VERSION "10.7.4"

NS_ :

BS_:

BU_: ADAS_PT BMS_Tester DUMMY_ECU DUMMY_POD_TOOL EDS_F EDS_R EPS2 GS IDB_PT POD RCU_PT VCU_PT XGW_PT

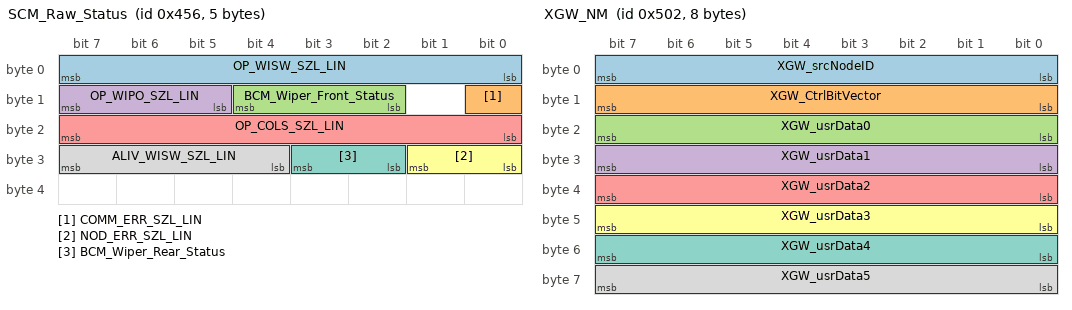
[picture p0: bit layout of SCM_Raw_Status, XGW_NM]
BO_ 1110 SCM_Raw_Status: 5 XGW_PT
  SG_ OP_WISW_SZL_LIN : 7|8@0+ (1,0) [0|255] "" DUMMY_ECU
  SG_ COMM_ERR_SZL_LIN : 8|1@0+ (1,0) [0|1] "" DUMMY_ECU
  SG_ BCM_Wiper_Front_Status : 12|3@0+ (1,0) [0|7] "" IDB_PT
  SG_ OP_WIPO_SZL_LIN : 15|3@0+ (1,0) [0|7] "-" DUMMY_ECU
  SG_ OP_COLS_SZL_LIN : 23|8@0+ (1,0) [0|255] "-" DUMMY_ECU
  SG_ NOD_ERR_SZL_LIN : 25|2@0+ (1,0) [0|3] "" DUMMY_ECU
  SG_ BCM_Wiper_Rear_Status : 27|2@0+ (1,0) [0|3] "" DUMMY_ECU
  SG_ ALIV_WISW_SZL_LIN : 31|4@0+ (1,0) [0|14] "" DUMMY_ECU

BO_ 1168 GS_WarnMsg: 8 GS
  SG_ CHSKM_GS_WarnMsg : 7|8@0+ (1,0) [0|255] "" VCU_PT,XGW_PT
  SG_ ALV_GS_WarnMsg : 11|4@0+ (1,0) [0|14] "" VCU_PT,XGW_PT
  SG_ GS_Warning_Flag_1 : 12|1@0+ (1,0) [0|1] "" VCU_PT,XGW_PT
  SG_ GS_Warning_Flag_2 : 13|1@0+ (1,0) [0|1] "" VCU_PT,XGW_PT
  SG_ GS_Warning_Flag_3 : 14|1@0+ (1,0) [0|1] "-" VCU_PT,XGW_PT
  SG_ GS_Warning_Flag_4 : 15|1@0+ (1,0) [0|1] "-" VCU_PT,XGW_PT
  SG_ GS_Warning_Flag_5 : 16|1@0+ (1,0) [0|1] "" VCU_PT,XGW_PT
  SG_ GS_Warning_Flag_6 : 17|1@0+ (1,0) [0|1] "-" VCU_PT,XGW_PT
  SG_ GS_Warning_Flag_7 : 18|1@0+ (1,0) [0|1] "" VCU_PT,XGW_PT
  SG_ GS_Warning_Flag_8 : 19|1@0+ (1,0) [0|1] "" VCU_PT,XGW_PT
  SG_ GS_Warning_Flag_9 : 20|1@0+ (1,0) [0|1] "-" VCU_PT,XGW_PT
  SG_ GS_Warning_Flag_10 : 21|1@0+ (1,0) [0|1] "-" VCU_PT,XGW_PT
  SG_ GS_Warning_Flag_11 : 22|1@0+ (1,0) [0|1] "" VCU_PT,XGW_PT
  SG_ GS_Warning_Flag_12 : 23|1@0+ (1,0) [0|1] "" VCU_PT,XGW_PT
  SG_ GS_Reserved_signal1 : 31|8@0+ (1,0) [0|255] "-" VCU_PT,XGW_PT
  SG_ GS_Reserved_signal2 : 39|8@0+ (1,0) [0|255] "" VCU_PT,XGW_PT
  SG_ GS_Reserved_signal3 : 47|8@0+ (1,0) [0|255] "" VCU_PT,XGW_PT
  SG_ GS_Reserved_signal4 : 55|8@0+ (1,0) [0|255] "-" VCU_PT,XGW_PT
  SG_ GS_Reserved_signal5 : 63|8@0+ (1,0) [0|255] "" VCU_PT,XGW_PT

BO_ 1178 EDS_R_WarnMsg: 8 EDS_R
  SG_ CHSKM_EDS_R_WarnMsg : 7|8@0+ (1,0) [0|255] "" XGW_PT
  SG_ ALV_EDS_R_WarnMsg : 11|4@0+ (1,0) [0|14] "" XGW_PT
  SG_ EDS_R_Warning_Flag_1 : 12|1@0+ (1,0) [0|1] "" XGW_PT
  SG_ EDS_R_Warning_Flag_2 : 13|1@0+ (1,0) [0|1] "" XGW_PT
  SG_ EDS_R_Warning_Flag_3 : 14|1@0+ (1,0) [0|1] "" XGW_PT
  SG_ EDS_R_Warning_Flag_4 : 15|1@0+ (1,0) [0|1] "-" XGW_PT
  SG_ EDS_R_Warning_Flag_5 : 16|1@0+ (1,0) [0|1] "" XGW_PT
  SG_ EDS_R_Warning_Flag_6 : 17|1@0+ (1,0) [0|1] "-" XGW_PT
  SG_ EDS_R_Warning_Flag_7 : 18|1@0+ (1,0) [0|1] "" XGW_PT
  SG_ EDS_R_Warning_Flag_8 : 19|1@0+ (1,0) [0|1] "" XGW_PT
  SG_ EDS_R_Warning_Flag_9 : 20|1@0+ (1,0) [0|1] "-" XGW_PT
  SG_ EDS_R_Warning_Flag_10 : 21|1@0+ (1,0) [0|1] "" XGW_PT
  SG_ EDS_R_Warning_Flag_11 : 22|1@0+ (1,0) [0|1] "" XGW_PT
  SG_ EDS_R_Warning_Flag_12 : 23|1@0+ (1,0) [0|1] "-" XGW_PT
  SG_ EDS_R_Reserved_signal1 : 31|8@0+ (1,0) [0|255] "" XGW_PT
  SG_ EDS_R_Reserved_signal2 : 39|8@0+ (1,0) [0|255] "" XGW_PT
  SG_ EDS_R_Reserved_signal3 : 47|8@0+ (1,0) [0|255] "-" XGW_PT
  SG_ EDS_R_Reserved_signal4 : 55|8@0+ (1,0) [0|255] "-" XGW_PT
  SG_ EDS_R_Reserved_signal5 : 63|8@0+ (1,0) [0|255] "-" XGW_PT

BO_ 1179 EDS_F_WarnMsg: 8 EDS_F
  SG_ CHSKM_EDS_F_WarnMsg : 7|8@0+ (1,0) [0|255] "" XGW_PT
  SG_ ALV_EDS_F_WarnMsg : 11|4@0+ (1,0) [0|14] "" XGW_PT
  SG_ EDS_F_Warning_Flag_1 : 12|1@0+ (1,0) [0|1] "" XGW_PT
  SG_ EDS_F_Warning_Flag_2 : 13|1@0+ (1,0) [0|1] "-" XGW_PT
  SG_ EDS_F_Warning_Flag_3 : 14|1@0+ (1,0) [0|1] "-" XGW_PT
  SG_ EDS_F_Warning_Flag_4 : 15|1@0+ (1,0) [0|1] "" XGW_PT
  SG_ EDS_F_Warning_Flag_5 : 16|1@0+ (1,0) [0|1] "" XGW_PT
  SG_ EDS_F_Warning_Flag_6 : 17|1@0+ (1,0) [0|1] "-" XGW_PT
  SG_ EDS_F_Warning_Flag_7 : 18|1@0+ (1,0) [0|1] "-" XGW_PT
  SG_ EDS_F_Warning_Flag_8 : 19|1@0+ (1,0) [0|1] "" XGW_PT
  SG_ EDS_F_Warning_Flag_9 : 20|1@0+ (1,0) [0|1] "" XGW_PT
  SG_ EDS_F_Warning_Flag_10 : 21|1@0+ (1,0) [0|1] "-" XGW_PT
  SG_ EDS_F_Warning_Flag_11 : 22|1@0+ (1,0) [0|1] "-" XGW_PT
  SG_ EDS_F_Warning_Flag_12 : 23|1@0+ (1,0) [0|1] "" XGW_PT
  SG_ EDS_F_Reserved_signal1 : 31|8@0+ (1,0) [0|255] "" XGW_PT
  SG_ EDS_F_Reserved_signal2 : 39|8@0+ (1,0) [0|255] "-" XGW_PT
  SG_ EDS_F_Reserved_signal3 : 47|8@0+ (1,0) [0|255] "" XGW_PT
  SG_ EDS_F_Reserved_signal4 : 55|8@0+ (1,0) [0|255] "-" XGW_PT
  SG_ EDS_F_Reserved_signal5 : 63|8@0+ (1,0) [0|255] "" XGW_PT

BO_ 1195 EPS2_WarnMsg: 8 EPS2
  SG_ CHSKM_EPS2_WarnMsg : 7|8@0+ (1,0) [0|255] "" XGW_PT
  SG_ ALV_EPS2_WarnMsg : 11|4@0+ (1,0) [0|14] "" XGW_PT
  SG_ EPS2_Malfunction : 12|1@0+ (1,0) [0|1] "" XGW_PT
  SG_ EPS2_Reduced : 13|1@0+ (1,0) [0|1] "" XGW_PT
  SG_ EPS2_Overheat : 14|1@0+ (1,0) [0|1] "" XGW_PT
  SG_ EPS2_NotReady : 15|1@0+ (1,0) [0|1] "" XGW_PT
  SG_ EPS2_Warning_Flag_5 : 16|1@0+ (1,0) [0|1] "" XGW_PT
  SG_ EPS2_Warning_Flag_6 : 17|1@0+ (1,0) [0|1] "" XGW_PT
  SG_ EPS2_Warning_Flag_7 : 18|1@0+ (1,0) [0|1] "" XGW_PT
  SG_ EPS2_Warning_Flag_8 : 19|1@0+ (1,0) [0|1] "" XGW_PT
  SG_ EPS2_Warning_Flag_9 : 20|1@0+ (1,0) [0|1] "" XGW_PT
  SG_ EPS2_Warning_Flag_10 : 21|1@0+ (1,0) [0|1] "" XGW_PT
  SG_ EPS2_Warning_Flag_11 : 22|1@0+ (1,0) [0|1] "" XGW_PT
  SG_ EPS2_Warning_Flag_12 : 23|1@0+ (1,0) [0|1] "" XGW_PT
  SG_ EPS2_Reserved_signal1 : 31|8@0+ (1,0) [0|255] "" XGW_PT
  SG_ EPS2_Reserved_signal2 : 39|8@0+ (1,0) [0|255] "" XGW_PT
  SG_ EPS2_Reserved_signal3 : 47|8@0+ (1,0) [0|255] "" XGW_PT
  SG_ EPS2_Reserved_signal4 : 55|8@0+ (1,0) [0|255] "" XGW_PT
  SG_ EPS2_Reserved_signal5 : 63|8@0+ (1,0) [0|255] "" XGW_PT

BO_ 1196 VCU_WarnMsg: 8 VCU_PT
  SG_ CHSKM_VCU_WarnMsg : 7|8@0+ (1,0) [0|255] "" XGW_PT
  SG_ ALV_VCU_WarnMsg : 11|4@0+ (1,0) [0|14] "" XGW_PT
  SG_ VCU_GearPOnlyAtStationaryAlert : 12|1@0+ (1,0) [0|1] "" XGW_PT
  SG_ VCU_GearP_NotPossibleAlert : 13|1@0+ (1,0) [0|1] "" XGW_PT
  SG_ VCU_PressBrakeToEngageGear : 14|1@0+ (1,0) [0|1] "" XGW_PT
  SG_ VCU_CantChangeGear : 15|1@0+ (1,0) [0|1] "" XGW_PT
  SG_ VCU_GearMalfunction : 16|1@0+ (1,0) [0|1] "" XGW_PT
  SG_ VCU_RangeAlert : 17|1@0+ (1,0) [0|1] "" XGW_PT
  SG_ VCU_HVSystemReduced : 18|1@0+ (1,0) [0|1] "" XGW_PT
  SG_ VCU_FrontEDSReduced : 19|1@0+ (1,0) [0|1] "" XGW_PT
  SG_ VCU_FrontEDS_Malfunc : 20|1@0+ (1,0) [0|1] "" XGW_PT
  SG_ VCU_RearEDSReduced : 21|1@0+ (1,0) [0|1] "" XGW_PT
  SG_ VCU_RearEDS_Malfunc : 22|1@0+ (1,0) [0|1] "" XGW_PT
  SG_ VCU_CoolingSystem_Malfunc : 23|1@0+ (1,0) [0|1] "" XGW_PT
  SG_ VCU_NeutralRequest : 24|1@0+ (1,0) [0|1] "" XGW_PT
  SG_ VCU_SoftShutdown : 25|1@0+ (1,0) [0|1] "" XGW_PT
  SG_ VCU_EmergencyShutdown : 26|1@0+ (1,0) [0|1] "" XGW_PT
  SG_ VCU_ChgPortDoorSys_Malfunc : 27|1@0+ (1,0) [0|1] "" XGW_PT
  SG_ VCU_Gearchange_NotPossible : 28|1@0+ (1,0) [0|1] "" XGW_PT
  SG_ VCU_12v_Warning : 29|1@0+ (1,0) [0|1] "" XGW_PT
  SG_ VCU_WflagRes19 : 30|1@0+ (1,0) [0|1] "" XGW_PT
  SG_ VCU_WflagRes20 : 31|1@0+ (1,0) [0|1] "" XGW_PT
  SG_ VCU_WflagRes21 : 32|1@0+ (1,0) [0|1] "" XGW_PT
  SG_ VCU_WflagRes22 : 33|1@0+ (1,0) [0|1] "" XGW_PT
  SG_ VCU_WflagRes23 : 34|1@0+ (1,0) [0|1] "" XGW_PT
  SG_ VCU_WflagRes24 : 35|1@0+ (1,0) [0|1] "" XGW_PT
  SG_ VCU_WflagRes25 : 36|1@0+ (1,0) [0|1] "" XGW_PT
  SG_ VCU_WflagRes26 : 37|1@0+ (1,0) [0|1] "" XGW_PT
  SG_ VCU_WflagRes27 : 38|1@0+ (1,0) [0|1] "" XGW_PT
  SG_ VCU_SuperFastCharge_longer : 39|1@0+ (1,0) [0|1] "" XGW_PT
  SG_ VCU_Reserved_signal1 : 47|8@0+ (1,0) [0|255] "" XGW_PT
  SG_ VCU_Reserved_signal2 : 55|8@0+ (1,0) [0|255] "" XGW_PT
  SG_ VCU_Reserved_signal3 : 63|8@0+ (1,0) [0|255] "" XGW_PT

BO_ 1213 POD_WarnMsg: 8 POD
  SG_ CHSKM_POD_WarnMsg : 7|8@0+ (1,0) [0|255] "" XGW_PT
  SG_ ALV_POD_WarnMsg : 11|4@0+ (1,0) [0|14] "" XGW_PT
  SG_ POD_Warning_Flag_1 : 12|1@0+ (1,0) [0|1] "-" XGW_PT
  SG_ POD_Warning_Flag_2 : 13|1@0+ (1,0) [0|1] "-" XGW_PT
  SG_ POD_Warning_Flag_3 : 14|1@0+ (1,0) [0|1] "-" XGW_PT
  SG_ POD_Warning_Flag_4 : 15|1@0+ (1,0) [0|1] "-" XGW_PT
  SG_ POD_Warning_Flag_5 : 16|1@0+ (1,0) [0|1] "-" XGW_PT
  SG_ POD_Warning_Flag_6 : 17|1@0+ (1,0) [0|1] "-" XGW_PT
  SG_ POD_Warning_Flag_7 : 18|1@0+ (1,0) [0|1] "-" XGW_PT
  SG_ POD_Warning_Flag_8 : 19|1@0+ (1,0) [0|1] "-" XGW_PT
  SG_ POD_Warning_Flag_9 : 20|1@0+ (1,0) [0|1] "-" XGW_PT
  SG_ POD_Warning_Flag_10 : 21|1@0+ (1,0) [0|1] "-" XGW_PT
  SG_ POD_Warning_Flag_11 : 22|1@0+ (1,0) [0|1] "-" XGW_PT
  SG_ POD_Warning_Flag_12 : 23|1@0+ (1,0) [0|1] "-" XGW_PT
  SG_ POD_Warning_Flag_13 : 24|1@0+ (1,0) [0|1] "-" XGW_PT
  SG_ POD_Warning_Flag_14 : 25|1@0+ (1,0) [0|1] "-" XGW_PT
  SG_ POD_Warning_Flag_15 : 26|1@0+ (1,0) [0|1] "-" XGW_PT
  SG_ POD_Warning_Flag_16 : 27|1@0+ (1,0) [0|1] "-" XGW_PT
  SG_ POD_Warning_Flag_17 : 28|1@0+ (1,0) [0|1] "-" XGW_PT
  SG_ POD_Warning_Flag_18 : 29|1@0+ (1,0) [0|1] "-" XGW_PT
  SG_ POD_Warning_Flag_19 : 30|1@0+ (1,0) [0|1] "-" XGW_PT
  SG_ POD_Warning_Flag_20 : 31|1@0+ (1,0) [0|1] "-" XGW_PT
  SG_ POD_Warning_Flag_21 : 32|1@0+ (1,0) [0|1] "-" XGW_PT
  SG_ POD_Warning_Flag_22 : 33|1@0+ (1,0) [0|1] "-" XGW_PT
  SG_ POD_Warning_Flag_23 : 34|1@0+ (1,0) [0|1] "-" XGW_PT
  SG_ POD_Warning_Flag_24 : 35|1@0+ (1,0) [0|1] "-" XGW_PT
  SG_ POD_Warning_Flag_25 : 36|1@0+ (1,0) [0|1] "-" XGW_PT
  SG_ POD_Warning_Flag_26 : 37|1@0+ (1,0) [0|1] "-" XGW_PT
  SG_ POD_Warning_Flag_27 : 38|1@0+ (1,0) [0|1] "-" XGW_PT
  SG_ POD_Warning_Flag_28 : 39|1@0+ (1,0) [0|1] "-" XGW_PT
  SG_ POD_Reserved_signal3 : 47|8@0+ (1,0) [0|255] "-" XGW_PT
  SG_ POD_Reserved_signal4 : 55|8@0+ (1,0) [0|255] "-" XGW_PT
  SG_ POD_Reserved_signal5 : 63|8@0+ (1,0) [0|255] "-" XGW_PT

BO_ 1282 XGW_NM: 8 XGW_PT
  SG_ XGW_srcNodeID : 7|8@0+ (1,0) [0|255] "" EDS_F,EDS_R,GS,IDB_PT,POD,VCU_PT
  SG_ XGW_CtrlBitVector : 15|8@0+ (1,0) [0|255] "" EDS_F,EDS_R,GS,IDB_PT,POD,VCU_PT
  SG_ XGW_usrData0 : 23|8@0+ (1,0) [0|255] "" EDS_F,EDS_R,GS,IDB_PT,POD,VCU_PT
  SG_ XGW_usrData1 : 31|8@0+ (1,0) [0|255] "" EDS_F,EDS_R,GS,IDB_PT,POD,VCU_PT
  SG_ XGW_usrData2 : 39|8@0+ (1,0) [0|255] "" EDS_F,EDS_R,GS,IDB_PT,POD,VCU_PT
  SG_ XGW_usrData3 : 47|8@0+ (1,0) [0|255] "" EDS_F,EDS_R,GS,IDB_PT,POD,VCU_PT
  SG_ XGW_usrData4 : 55|8@0+ (1,0) [0|255] "" EDS_F,EDS_R,GS,IDB_PT,POD,VCU_PT
  SG_ XGW_usrData5 : 63|8@0+ (1,0) [0|255] "" EDS_F,EDS_R,GS,IDB_PT,POD,VCU_PT

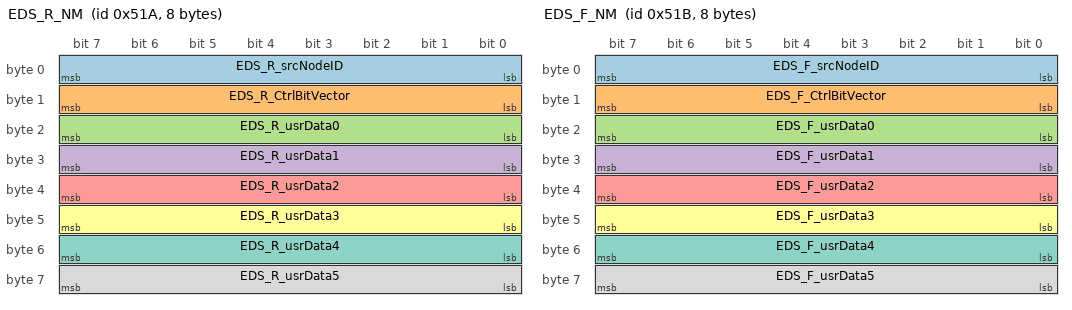
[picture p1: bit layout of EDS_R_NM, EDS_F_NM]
BO_ 1306 EDS_R_NM: 8 EDS_R
  SG_ EDS_R_srcNodeID : 7|8@0+ (1,0) [0|255] "" EDS_F,GS,IDB_PT,POD,VCU_PT,XGW_PT
  SG_ EDS_R_CtrlBitVector : 15|8@0+ (1,0) [0|255] "" EDS_F,GS,IDB_PT,POD,VCU_PT,XGW_PT
  SG_ EDS_R_usrData0 : 23|8@0+ (1,0) [0|255] "" EDS_F,GS,IDB_PT,POD,VCU_PT,XGW_PT
  SG_ EDS_R_usrData1 : 31|8@0+ (1,0) [0|255] "" EDS_F,GS,IDB_PT,POD,VCU_PT,XGW_PT
  SG_ EDS_R_usrData2 : 39|8@0+ (1,0) [0|255] "" EDS_F,GS,IDB_PT,POD,VCU_PT,XGW_PT
  SG_ EDS_R_usrData3 : 47|8@0+ (1,0) [0|255] "" EDS_F,GS,IDB_PT,POD,VCU_PT,XGW_PT
  SG_ EDS_R_usrData4 : 55|8@0+ (1,0) [0|255] "" EDS_F,GS,IDB_PT,POD,VCU_PT,XGW_PT
  SG_ EDS_R_usrData5 : 63|8@0+ (1,0) [0|255] "" EDS_F,GS,IDB_PT,POD,VCU_PT,XGW_PT

BO_ 1307 EDS_F_NM: 8 EDS_F
  SG_ EDS_F_srcNodeID : 7|8@0+ (1,0) [0|255] "" EDS_R,GS,IDB_PT,POD,VCU_PT,XGW_PT
  SG_ EDS_F_CtrlBitVector : 15|8@0+ (1,0) [0|255] "" EDS_R,GS,IDB_PT,POD,VCU_PT,XGW_PT
  SG_ EDS_F_usrData0 : 23|8@0+ (1,0) [0|255] "" EDS_R,GS,IDB_PT,POD,VCU_PT,XGW_PT
  SG_ EDS_F_usrData1 : 31|8@0+ (1,0) [0|255] "" EDS_R,GS,IDB_PT,POD,VCU_PT,XGW_PT
  SG_ EDS_F_usrData2 : 39|8@0+ (1,0) [0|255] "" EDS_R,GS,IDB_PT,POD,VCU_PT,XGW_PT
  SG_ EDS_F_usrData3 : 47|8@0+ (1,0) [0|255] "" EDS_R,GS,IDB_PT,POD,VCU_PT,XGW_PT
  SG_ EDS_F_usrData4 : 55|8@0+ (1,0) [0|255] "" EDS_R,GS,IDB_PT,POD,VCU_PT,XGW_PT
  SG_ EDS_F_usrData5 : 63|8@0+ (1,0) [0|255] "" EDS_R,GS,IDB_PT,POD,VCU_PT,XGW_PT

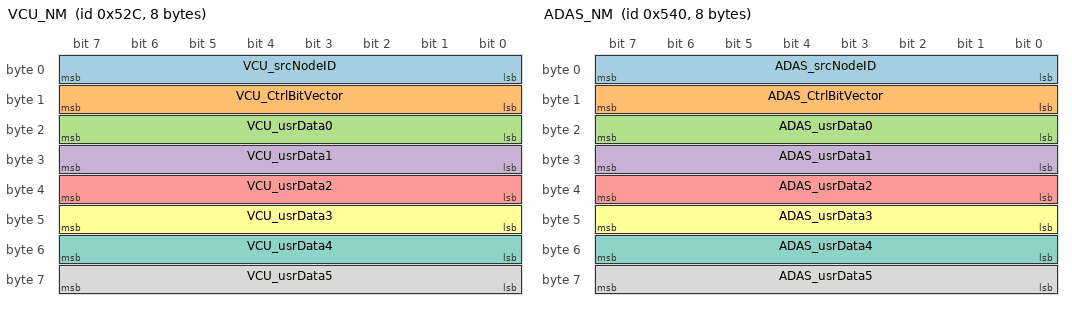
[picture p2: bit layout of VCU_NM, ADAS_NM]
BO_ 1324 VCU_NM: 8 VCU_PT
  SG_ VCU_srcNodeID : 7|8@0+ (1,0) [0|255] "" EDS_F,EDS_R,GS,IDB_PT,POD,XGW_PT
  SG_ VCU_CtrlBitVector : 15|8@0+ (1,0) [0|255] "" EDS_F,EDS_R,GS,IDB_PT,POD,XGW_PT
  SG_ VCU_usrData0 : 23|8@0+ (1,0) [0|255] "" EDS_F,EDS_R,GS,IDB_PT,POD,XGW_PT
  SG_ VCU_usrData1 : 31|8@0+ (1,0) [0|255] "" EDS_F,EDS_R,GS,IDB_PT,POD,XGW_PT
  SG_ VCU_usrData2 : 39|8@0+ (1,0) [0|255] "" EDS_F,EDS_R,GS,IDB_PT,POD,XGW_PT
  SG_ VCU_usrData3 : 47|8@0+ (1,0) [0|255] "" EDS_F,EDS_R,GS,IDB_PT,POD,XGW_PT
  SG_ VCU_usrData4 : 55|8@0+ (1,0) [0|255] "" EDS_F,EDS_R,GS,IDB_PT,POD,XGW_PT
  SG_ VCU_usrData5 : 63|8@0+ (1,0) [0|255] "" EDS_F,EDS_R,GS,IDB_PT,POD,XGW_PT

BO_ 1344 ADAS_NM: 8 ADAS_PT
  SG_ ADAS_srcNodeID : 7|8@0+ (1,0) [0|255] "" EDS_F,EDS_R,GS,IDB_PT,POD,VCU_PT,XGW_PT
  SG_ ADAS_CtrlBitVector : 15|8@0+ (1,0) [0|255] "-" EDS_F,EDS_R,GS,IDB_PT,POD,VCU_PT,XGW_PT
  SG_ ADAS_usrData0 : 23|8@0+ (1,0) [0|255] "" EDS_F,EDS_R,GS,IDB_PT,POD,VCU_PT,XGW_PT
  SG_ ADAS_usrData1 : 31|8@0+ (1,0) [0|255] "" EDS_F,EDS_R,GS,IDB_PT,POD,VCU_PT,XGW_PT
  SG_ ADAS_usrData2 : 39|8@0+ (1,0) [0|255] "" EDS_F,EDS_R,GS,IDB_PT,POD,VCU_PT,XGW_PT
  SG_ ADAS_usrData3 : 47|8@0+ (1,0) [0|255] "-" EDS_F,EDS_R,GS,IDB_PT,POD,VCU_PT,XGW_PT
  SG_ ADAS_usrData4 : 55|8@0+ (1,0) [0|255] "-" EDS_F,EDS_R,GS,IDB_PT,POD,VCU_PT,XGW_PT
  SG_ ADAS_usrData5 : 63|8@0+ (1,0) [0|255] "-" EDS_F,EDS_R,GS,IDB_PT,POD,VCU_PT,XGW_PT

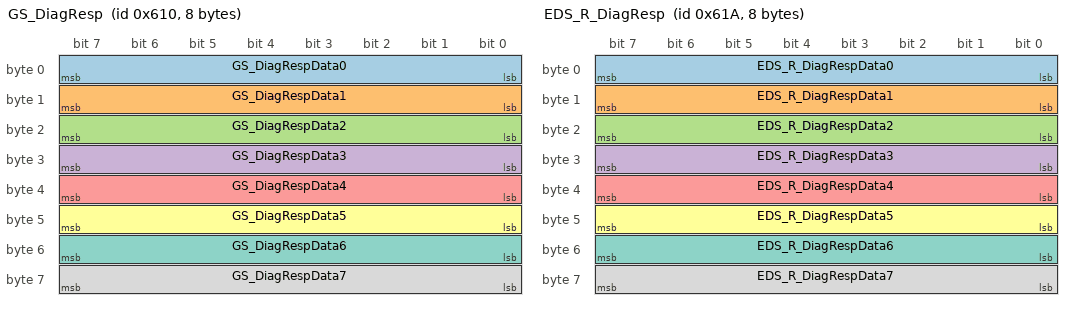
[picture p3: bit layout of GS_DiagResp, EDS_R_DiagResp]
BO_ 1552 GS_DiagResp: 8 GS
  SG_ GS_DiagRespData0 : 7|8@0+ (1,0) [0|255] "-" XGW_PT
  SG_ GS_DiagRespData1 : 15|8@0+ (1,0) [0|255] "" XGW_PT
  SG_ GS_DiagRespData2 : 23|8@0+ (1,0) [0|255] "-" XGW_PT
  SG_ GS_DiagRespData3 : 31|8@0+ (1,0) [0|255] "" XGW_PT
  SG_ GS_DiagRespData4 : 39|8@0+ (1,0) [0|255] "" XGW_PT
  SG_ GS_DiagRespData5 : 47|8@0+ (1,0) [0|255] "" XGW_PT
  SG_ GS_DiagRespData6 : 55|8@0+ (1,0) [0|255] "-" XGW_PT
  SG_ GS_DiagRespData7 : 63|8@0+ (1,0) [0|255] "" XGW_PT

BO_ 1562 EDS_R_DiagResp: 8 EDS_R
  SG_ EDS_R_DiagRespData0 : 7|8@0+ (1,0) [0|255] "" XGW_PT
  SG_ EDS_R_DiagRespData1 : 15|8@0+ (1,0) [0|255] "" XGW_PT
  SG_ EDS_R_DiagRespData2 : 23|8@0+ (1,0) [0|255] "-" XGW_PT
  SG_ EDS_R_DiagRespData3 : 31|8@0+ (1,0) [0|255] "" XGW_PT
  SG_ EDS_R_DiagRespData4 : 39|8@0+ (1,0) [0|255] "" XGW_PT
  SG_ EDS_R_DiagRespData5 : 47|8@0+ (1,0) [0|255] "-" XGW_PT
  SG_ EDS_R_DiagRespData6 : 55|8@0+ (1,0) [0|255] "-" XGW_PT
  SG_ EDS_R_DiagRespData7 : 63|8@0+ (1,0) [0|255] "-" XGW_PT

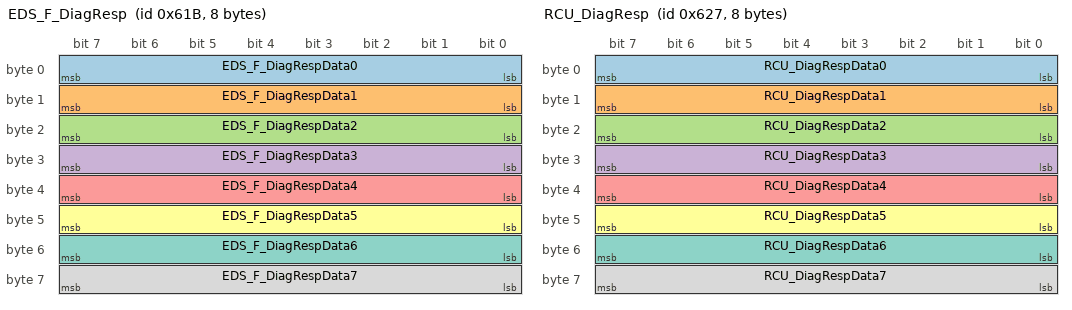
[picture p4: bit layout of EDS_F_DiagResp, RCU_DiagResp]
BO_ 1563 EDS_F_DiagResp: 8 EDS_F
  SG_ EDS_F_DiagRespData0 : 7|8@0+ (1,0) [0|255] "" XGW_PT
  SG_ EDS_F_DiagRespData1 : 15|8@0+ (1,0) [0|255] "" XGW_PT
  SG_ EDS_F_DiagRespData2 : 23|8@0+ (1,0) [0|255] "-" XGW_PT
  SG_ EDS_F_DiagRespData3 : 31|8@0+ (1,0) [0|255] "" XGW_PT
  SG_ EDS_F_DiagRespData4 : 39|8@0+ (1,0) [0|255] "" XGW_PT
  SG_ EDS_F_DiagRespData5 : 47|8@0+ (1,0) [0|255] "" XGW_PT
  SG_ EDS_F_DiagRespData6 : 55|8@0+ (1,0) [0|255] "-" XGW_PT
  SG_ EDS_F_DiagRespData7 : 63|8@0+ (1,0) [0|255] "" XGW_PT

BO_ 1575 RCU_DiagResp: 8 RCU_PT
  SG_ RCU_DiagRespData0 : 7|8@0+ (1,0) [0|255] "" XGW_PT
  SG_ RCU_DiagRespData1 : 15|8@0+ (1,0) [0|255] "" XGW_PT
  SG_ RCU_DiagRespData2 : 23|8@0+ (1,0) [0|255] "" XGW_PT
  SG_ RCU_DiagRespData3 : 31|8@0+ (1,0) [0|255] "" XGW_PT
  SG_ RCU_DiagRespData4 : 39|8@0+ (1,0) [0|255] "" XGW_PT
  SG_ RCU_DiagRespData5 : 47|8@0+ (1,0) [0|255] "" XGW_PT
  SG_ RCU_DiagRespData6 : 55|8@0+ (1,0) [0|255] "" XGW_PT
  SG_ RCU_DiagRespData7 : 63|8@0+ (1,0) [0|255] "" XGW_PT

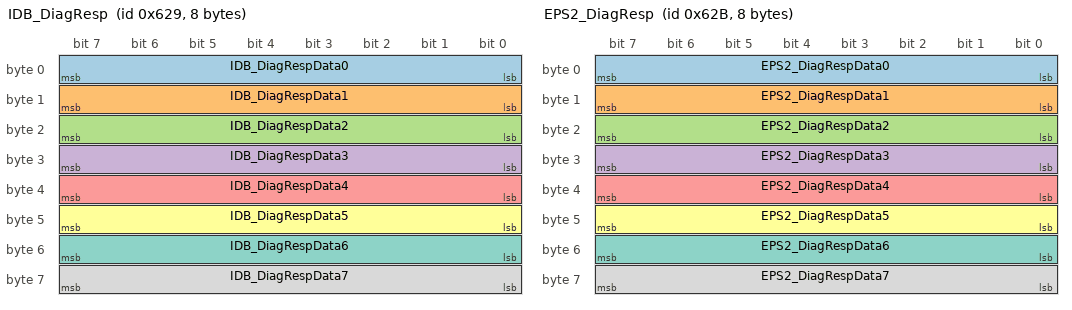
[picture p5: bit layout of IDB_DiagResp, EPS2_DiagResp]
BO_ 1577 IDB_DiagResp: 8 IDB_PT
  SG_ IDB_DiagRespData0 : 7|8@0+ (1,0) [0|255] "" XGW_PT
  SG_ IDB_DiagRespData1 : 15|8@0+ (1,0) [0|255] "-" XGW_PT
  SG_ IDB_DiagRespData2 : 23|8@0+ (1,0) [0|255] "-" XGW_PT
  SG_ IDB_DiagRespData3 : 31|8@0+ (1,0) [0|255] "" XGW_PT
  SG_ IDB_DiagRespData4 : 39|8@0+ (1,0) [0|255] "" XGW_PT
  SG_ IDB_DiagRespData5 : 47|8@0+ (1,0) [0|255] "-" XGW_PT
  SG_ IDB_DiagRespData6 : 55|8@0+ (1,0) [0|255] "-" XGW_PT
  SG_ IDB_DiagRespData7 : 63|8@0+ (1,0) [0|255] "" XGW_PT

BO_ 1579 EPS2_DiagResp: 8 EPS2
  SG_ EPS2_DiagRespData0 : 7|8@0+ (1,0) [0|255] "" XGW_PT
  SG_ EPS2_DiagRespData1 : 15|8@0+ (1,0) [0|255] "-" XGW_PT
  SG_ EPS2_DiagRespData2 : 23|8@0+ (1,0) [0|255] "-" XGW_PT
  SG_ EPS2_DiagRespData3 : 31|8@0+ (1,0) [0|255] "" XGW_PT
  SG_ EPS2_DiagRespData4 : 39|8@0+ (1,0) [0|255] "-" XGW_PT
  SG_ EPS2_DiagRespData5 : 47|8@0+ (1,0) [0|255] "" XGW_PT
  SG_ EPS2_DiagRespData6 : 55|8@0+ (1,0) [0|255] "-" XGW_PT
  SG_ EPS2_DiagRespData7 : 63|8@0+ (1,0) [0|255] "-" XGW_PT

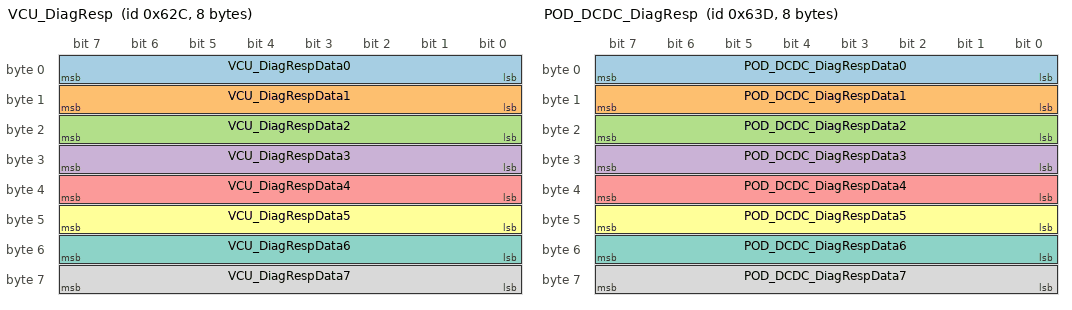
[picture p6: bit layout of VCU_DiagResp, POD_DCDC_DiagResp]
BO_ 1580 VCU_DiagResp: 8 VCU_PT
  SG_ VCU_DiagRespData0 : 7|8@0+ (1,0) [0|255] "" XGW_PT
  SG_ VCU_DiagRespData1 : 15|8@0+ (1,0) [0|255] "" XGW_PT
  SG_ VCU_DiagRespData2 : 23|8@0+ (1,0) [0|255] "" XGW_PT
  SG_ VCU_DiagRespData3 : 31|8@0+ (1,0) [0|255] "" XGW_PT
  SG_ VCU_DiagRespData4 : 39|8@0+ (1,0) [0|255] "-" XGW_PT
  SG_ VCU_DiagRespData5 : 47|8@0+ (1,0) [0|255] "" XGW_PT
  SG_ VCU_DiagRespData6 : 55|8@0+ (1,0) [0|255] "" XGW_PT
  SG_ VCU_DiagRespData7 : 63|8@0+ (1,0) [0|255] "-" XGW_PT

BO_ 1597 POD_DCDC_DiagResp: 8 POD
  SG_ POD_DCDC_DiagRespData0 : 7|8@0+ (1,0) [0|255] "" XGW_PT
  SG_ POD_DCDC_DiagRespData1 : 15|8@0+ (1,0) [0|255] "" XGW_PT
  SG_ POD_DCDC_DiagRespData2 : 23|8@0+ (1,0) [0|255] "-" XGW_PT
  SG_ POD_DCDC_DiagRespData3 : 31|8@0+ (1,0) [0|255] "-" XGW_PT
  SG_ POD_DCDC_DiagRespData4 : 39|8@0+ (1,0) [0|255] "" XGW_PT
  SG_ POD_DCDC_DiagRespData5 : 47|8@0+ (1,0) [0|255] "" XGW_PT
  SG_ POD_DCDC_DiagRespData6 : 55|8@0+ (1,0) [0|255] "-" XGW_PT
  SG_ POD_DCDC_DiagRespData7 : 63|8@0+ (1,0) [0|255] "" XGW_PT

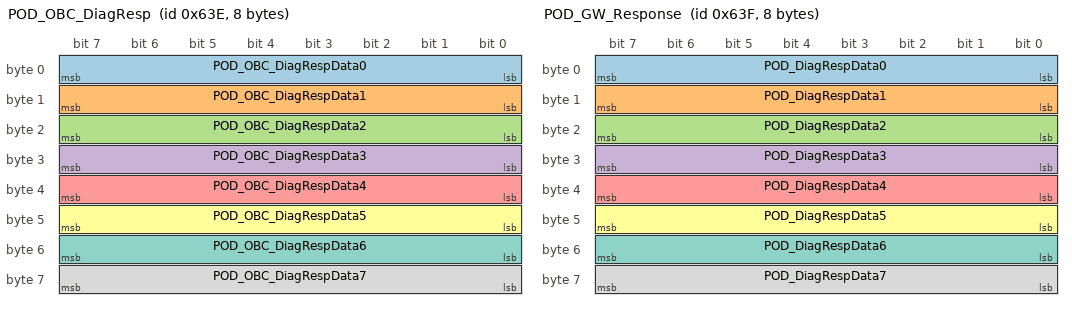
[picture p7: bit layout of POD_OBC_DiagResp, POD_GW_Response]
BO_ 1598 POD_OBC_DiagResp: 8 POD
  SG_ POD_OBC_DiagRespData0 : 7|8@0+ (1,0) [0|255] "" XGW_PT
  SG_ POD_OBC_DiagRespData1 : 15|8@0+ (1,0) [0|255] "-" XGW_PT
  SG_ POD_OBC_DiagRespData2 : 23|8@0+ (1,0) [0|255] "" XGW_PT
  SG_ POD_OBC_DiagRespData3 : 31|8@0+ (1,0) [0|255] "-" XGW_PT
  SG_ POD_OBC_DiagRespData4 : 39|8@0+ (1,0) [0|255] "" XGW_PT
  SG_ POD_OBC_DiagRespData5 : 47|8@0+ (1,0) [0|255] "-" XGW_PT
  SG_ POD_OBC_DiagRespData6 : 55|8@0+ (1,0) [0|255] "" XGW_PT
  SG_ POD_OBC_DiagRespData7 : 63|8@0+ (1,0) [0|255] "-" XGW_PT

BO_ 1599 POD_GW_Response: 8 POD
  SG_ POD_DiagRespData0 : 7|8@0+ (1,0) [0|255] "-" XGW_PT
  SG_ POD_DiagRespData1 : 15|8@0+ (1,0) [0|255] "" XGW_PT
  SG_ POD_DiagRespData2 : 23|8@0+ (1,0) [0|255] "" XGW_PT
  SG_ POD_DiagRespData3 : 31|8@0+ (1,0) [0|255] "-" XGW_PT
  SG_ POD_DiagRespData4 : 39|8@0+ (1,0) [0|255] "-" XGW_PT
  SG_ POD_DiagRespData5 : 47|8@0+ (1,0) [0|255] "-" XGW_PT
  SG_ POD_DiagRespData6 : 55|8@0+ (1,0) [0|255] "" XGW_PT
  SG_ POD_DiagRespData7 : 63|8@0+ (1,0) [0|255] "" XGW_PT

BO_ 1605 POD_OBC_CPU2_Diag_Resp: 8 POD
  SG_ POD_GW_Flash_Resp : 7|64@0+ (1,0) [0|0] "" DUMMY_ECU

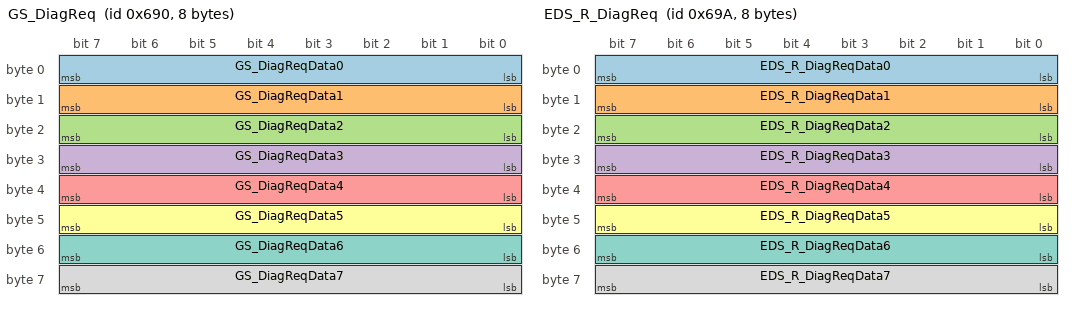
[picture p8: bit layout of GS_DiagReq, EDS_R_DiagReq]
BO_ 1680 GS_DiagReq: 8 XGW_PT
  SG_ GS_DiagReqData0 : 7|8@0+ (1,0) [0|255] "" GS
  SG_ GS_DiagReqData1 : 15|8@0+ (1,0) [0|255] "" GS
  SG_ GS_DiagReqData2 : 23|8@0+ (1,0) [0|255] "" GS
  SG_ GS_DiagReqData3 : 31|8@0+ (1,0) [0|255] "" GS
  SG_ GS_DiagReqData4 : 39|8@0+ (1,0) [0|255] "-" GS
  SG_ GS_DiagReqData5 : 47|8@0+ (1,0) [0|255] "" GS
  SG_ GS_DiagReqData6 : 55|8@0+ (1,0) [0|255] "" GS
  SG_ GS_DiagReqData7 : 63|8@0+ (1,0) [0|255] "" GS

BO_ 1690 EDS_R_DiagReq: 8 XGW_PT
  SG_ EDS_R_DiagReqData0 : 7|8@0+ (1,0) [0|255] "" EDS_R
  SG_ EDS_R_DiagReqData1 : 15|8@0+ (1,0) [0|255] "-" EDS_R
  SG_ EDS_R_DiagReqData2 : 23|8@0+ (1,0) [0|255] "" EDS_R
  SG_ EDS_R_DiagReqData3 : 31|8@0+ (1,0) [0|255] "-" EDS_R
  SG_ EDS_R_DiagReqData4 : 39|8@0+ (1,0) [0|255] "-" EDS_R
  SG_ EDS_R_DiagReqData5 : 47|8@0+ (1,0) [0|255] "" EDS_R
  SG_ EDS_R_DiagReqData6 : 55|8@0+ (1,0) [0|255] "-" EDS_R
  SG_ EDS_R_DiagReqData7 : 63|8@0+ (1,0) [0|255] "" EDS_R

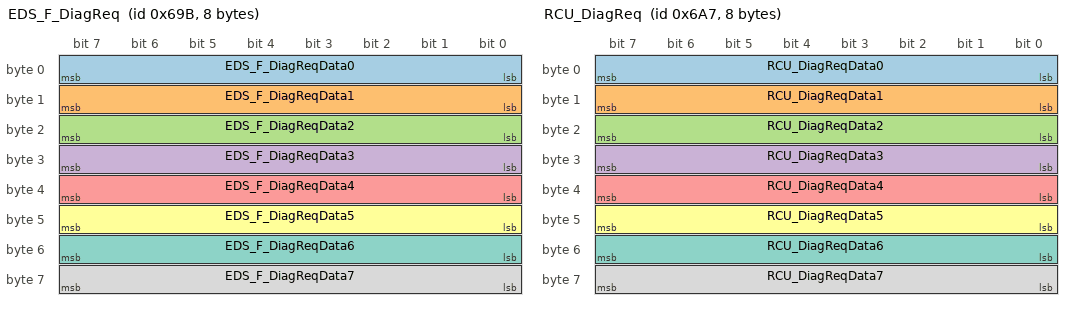
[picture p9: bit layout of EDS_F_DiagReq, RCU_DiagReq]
BO_ 1691 EDS_F_DiagReq: 8 XGW_PT
  SG_ EDS_F_DiagReqData0 : 7|8@0+ (1,0) [0|255] "-" EDS_F
  SG_ EDS_F_DiagReqData1 : 15|8@0+ (1,0) [0|255] "" EDS_F
  SG_ EDS_F_DiagReqData2 : 23|8@0+ (1,0) [0|255] "-" EDS_F
  SG_ EDS_F_DiagReqData3 : 31|8@0+ (1,0) [0|255] "" EDS_F
  SG_ EDS_F_DiagReqData4 : 39|8@0+ (1,0) [0|255] "" EDS_F
  SG_ EDS_F_DiagReqData5 : 47|8@0+ (1,0) [0|255] "" EDS_F
  SG_ EDS_F_DiagReqData6 : 55|8@0+ (1,0) [0|255] "" EDS_F
  SG_ EDS_F_DiagReqData7 : 63|8@0+ (1,0) [0|255] "" EDS_F

BO_ 1703 RCU_DiagReq: 8 XGW_PT
  SG_ RCU_DiagReqData0 : 7|8@0+ (1,0) [0|255] "" RCU_PT
  SG_ RCU_DiagReqData1 : 15|8@0+ (1,0) [0|255] "" RCU_PT
  SG_ RCU_DiagReqData2 : 23|8@0+ (1,0) [0|255] "" RCU_PT
  SG_ RCU_DiagReqData3 : 31|8@0+ (1,0) [0|255] "" RCU_PT
  SG_ RCU_DiagReqData4 : 39|8@0+ (1,0) [0|255] "-" RCU_PT
  SG_ RCU_DiagReqData5 : 47|8@0+ (1,0) [0|255] "" RCU_PT
  SG_ RCU_DiagReqData6 : 55|8@0+ (1,0) [0|255] "-" RCU_PT
  SG_ RCU_DiagReqData7 : 63|8@0+ (1,0) [0|255] "-" RCU_PT

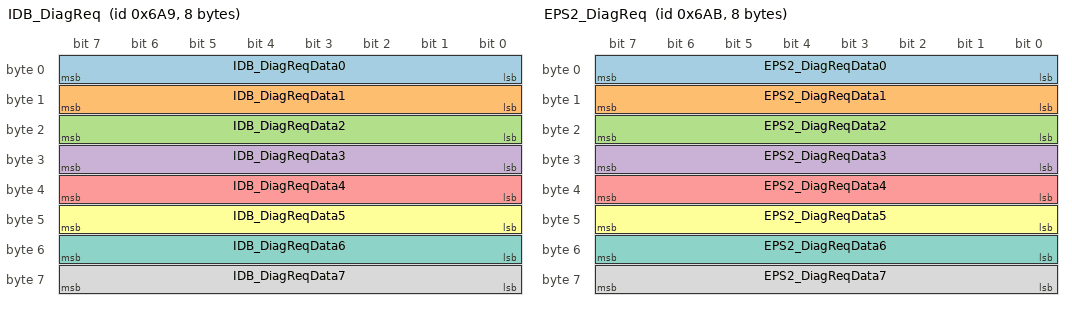
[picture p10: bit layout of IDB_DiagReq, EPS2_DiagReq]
BO_ 1705 IDB_DiagReq: 8 XGW_PT
  SG_ IDB_DiagReqData0 : 7|8@0+ (1,0) [0|255] "" IDB_PT
  SG_ IDB_DiagReqData1 : 15|8@0+ (1,0) [0|255] "" IDB_PT
  SG_ IDB_DiagReqData2 : 23|8@0+ (1,0) [0|255] "" IDB_PT
  SG_ IDB_DiagReqData3 : 31|8@0+ (1,0) [0|255] "" IDB_PT
  SG_ IDB_DiagReqData4 : 39|8@0+ (1,0) [0|255] "" IDB_PT
  SG_ IDB_DiagReqData5 : 47|8@0+ (1,0) [0|255] "" IDB_PT
  SG_ IDB_DiagReqData6 : 55|8@0+ (1,0) [0|255] "-" IDB_PT
  SG_ IDB_DiagReqData7 : 63|8@0+ (1,0) [0|255] "" IDB_PT

BO_ 1707 EPS2_DiagReq: 8 XGW_PT
  SG_ EPS2_DiagReqData0 : 7|8@0+ (1,0) [0|255] "" EPS2
  SG_ EPS2_DiagReqData1 : 15|8@0+ (1,0) [0|255] "" EPS2
  SG_ EPS2_DiagReqData2 : 23|8@0+ (1,0) [0|255] "" EPS2
  SG_ EPS2_DiagReqData3 : 31|8@0+ (1,0) [0|255] "-" EPS2
  SG_ EPS2_DiagReqData4 : 39|8@0+ (1,0) [0|255] "" EPS2
  SG_ EPS2_DiagReqData5 : 47|8@0+ (1,0) [0|255] "-" EPS2
  SG_ EPS2_DiagReqData6 : 55|8@0+ (1,0) [0|255] "" EPS2
  SG_ EPS2_DiagReqData7 : 63|8@0+ (1,0) [0|255] "" EPS2

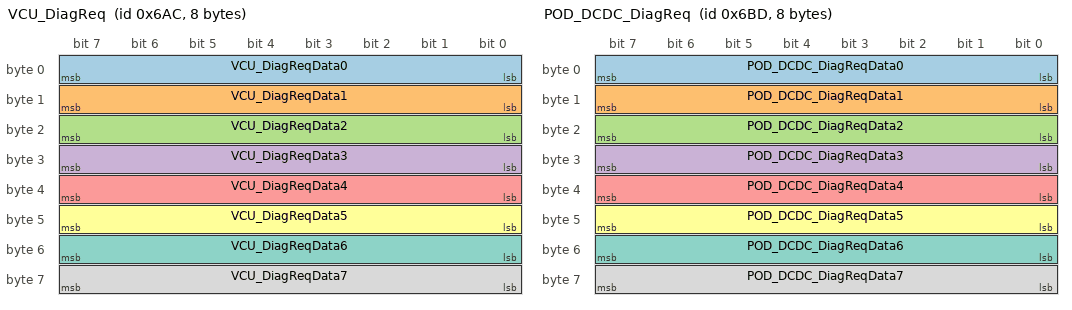
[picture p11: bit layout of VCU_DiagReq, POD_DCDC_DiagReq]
BO_ 1708 VCU_DiagReq: 8 XGW_PT
  SG_ VCU_DiagReqData0 : 7|8@0+ (1,0) [0|255] "-" VCU_PT
  SG_ VCU_DiagReqData1 : 15|8@0+ (1,0) [0|255] "" VCU_PT
  SG_ VCU_DiagReqData2 : 23|8@0+ (1,0) [0|255] "-" VCU_PT
  SG_ VCU_DiagReqData3 : 31|8@0+ (1,0) [0|255] "" VCU_PT
  SG_ VCU_DiagReqData4 : 39|8@0+ (1,0) [0|255] "" VCU_PT
  SG_ VCU_DiagReqData5 : 47|8@0+ (1,0) [0|255] "-" VCU_PT
  SG_ VCU_DiagReqData6 : 55|8@0+ (1,0) [0|255] "" VCU_PT
  SG_ VCU_DiagReqData7 : 63|8@0+ (1,0) [0|255] "-" VCU_PT

BO_ 1725 POD_DCDC_DiagReq: 8 XGW_PT
  SG_ POD_DCDC_DiagReqData0 : 7|8@0+ (1,0) [0|255] "" POD
  SG_ POD_DCDC_DiagReqData1 : 15|8@0+ (1,0) [0|255] "" POD
  SG_ POD_DCDC_DiagReqData2 : 23|8@0+ (1,0) [0|255] "-" POD
  SG_ POD_DCDC_DiagReqData3 : 31|8@0+ (1,0) [0|255] "" POD
  SG_ POD_DCDC_DiagReqData4 : 39|8@0+ (1,0) [0|255] "-" POD
  SG_ POD_DCDC_DiagReqData5 : 47|8@0+ (1,0) [0|255] "-" POD
  SG_ POD_DCDC_DiagReqData6 : 55|8@0+ (1,0) [0|255] "" POD
  SG_ POD_DCDC_DiagReqData7 : 63|8@0+ (1,0) [0|255] "" POD

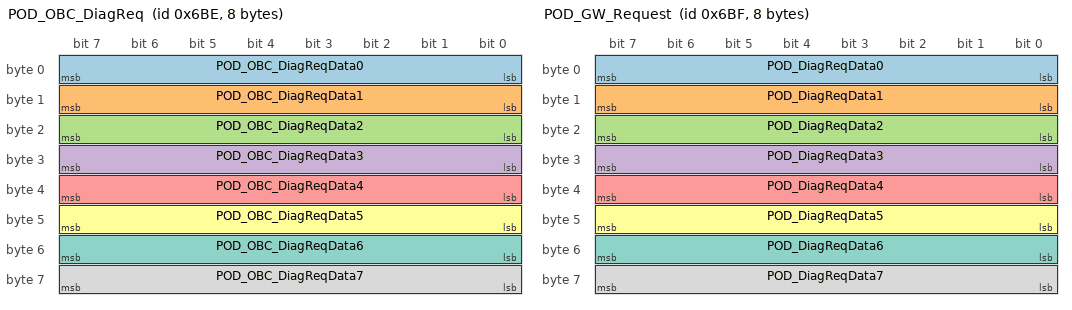
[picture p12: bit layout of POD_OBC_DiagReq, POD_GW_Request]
BO_ 1726 POD_OBC_DiagReq: 8 XGW_PT
  SG_ POD_OBC_DiagReqData0 : 7|8@0+ (1,0) [0|255] "" POD
  SG_ POD_OBC_DiagReqData1 : 15|8@0+ (1,0) [0|255] "" POD
  SG_ POD_OBC_DiagReqData2 : 23|8@0+ (1,0) [0|255] "" POD
  SG_ POD_OBC_DiagReqData3 : 31|8@0+ (1,0) [0|255] "-" POD
  SG_ POD_OBC_DiagReqData4 : 39|8@0+ (1,0) [0|255] "" POD
  SG_ POD_OBC_DiagReqData5 : 47|8@0+ (1,0) [0|255] "" POD
  SG_ POD_OBC_DiagReqData6 : 55|8@0+ (1,0) [0|255] "" POD
  SG_ POD_OBC_DiagReqData7 : 63|8@0+ (1,0) [0|255] "-" POD

BO_ 1727 POD_GW_Request: 8 XGW_PT
  SG_ POD_DiagReqData0 : 7|8@0+ (1,0) [0|255] "-" POD
  SG_ POD_DiagReqData1 : 15|8@0+ (1,0) [0|255] "" POD
  SG_ POD_DiagReqData2 : 23|8@0+ (1,0) [0|255] "" POD
  SG_ POD_DiagReqData3 : 31|8@0+ (1,0) [0|255] "" POD
  SG_ POD_DiagReqData4 : 39|8@0+ (1,0) [0|255] "" POD
  SG_ POD_DiagReqData5 : 47|8@0+ (1,0) [0|255] "" POD
  SG_ POD_DiagReqData6 : 55|8@0+ (1,0) [0|255] "" POD
  SG_ POD_DiagReqData7 : 63|8@0+ (1,0) [0|255] "" POD

BO_ 1733 POD_OBC_CPU2_Diag_Req: 8 DUMMY_ECU
  SG_ POD_GW_Flash_Req : 7|64@0+ (1,0) [0|0] "" POD

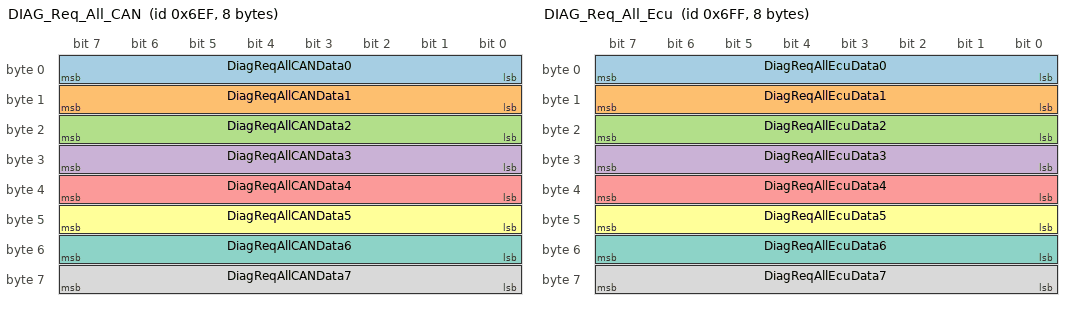
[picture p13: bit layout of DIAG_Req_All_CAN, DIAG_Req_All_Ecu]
BO_ 1775 DIAG_Req_All_CAN: 8 XGW_PT
  SG_ DiagReqAllCANData0 : 7|8@0+ (1,0) [0|255] "-" EDS_F,EDS_R,EPS2,GS,IDB_PT,POD,VCU_PT
  SG_ DiagReqAllCANData1 : 15|8@0+ (1,0) [0|255] "" EDS_F,EDS_R,EPS2,GS,IDB_PT,POD,VCU_PT
  SG_ DiagReqAllCANData2 : 23|8@0+ (1,0) [0|255] "-" EDS_F,EDS_R,EPS2,GS,IDB_PT,POD,VCU_PT
  SG_ DiagReqAllCANData3 : 31|8@0+ (1,0) [0|255] "-" EDS_F,EDS_R,EPS2,GS,IDB_PT,POD,VCU_PT
  SG_ DiagReqAllCANData4 : 39|8@0+ (1,0) [0|255] "" EDS_F,EDS_R,EPS2,GS,IDB_PT,POD,VCU_PT
  SG_ DiagReqAllCANData5 : 47|8@0+ (1,0) [0|255] "" EDS_F,EDS_R,EPS2,GS,IDB_PT,POD,VCU_PT
  SG_ DiagReqAllCANData6 : 55|8@0+ (1,0) [0|255] "" EDS_F,EDS_R,EPS2,GS,IDB_PT,POD,VCU_PT
  SG_ DiagReqAllCANData7 : 63|8@0+ (1,0) [0|255] "" EDS_F,EDS_R,EPS2,GS,IDB_PT,POD,VCU_PT

BO_ 1791 DIAG_Req_All_Ecu: 8 XGW_PT
  SG_ DiagReqAllEcuData0 : 7|8@0+ (1,0) [0|255] "-" EDS_F,EDS_R,EPS2,GS,IDB_PT,POD,VCU_PT
  SG_ DiagReqAllEcuData1 : 15|8@0+ (1,0) [0|255] "" EDS_F,EDS_R,EPS2,GS,IDB_PT,POD,VCU_PT
  SG_ DiagReqAllEcuData2 : 23|8@0+ (1,0) [0|255] "" EDS_F,EDS_R,EPS2,GS,IDB_PT,POD,VCU_PT
  SG_ DiagReqAllEcuData3 : 31|8@0+ (1,0) [0|255] "" EDS_F,EDS_R,EPS2,GS,IDB_PT,POD,VCU_PT
  SG_ DiagReqAllEcuData4 : 39|8@0+ (1,0) [0|255] "-" EDS_F,EDS_R,EPS2,GS,IDB_PT,POD,VCU_PT
  SG_ DiagReqAllEcuData5 : 47|8@0+ (1,0) [0|255] "" EDS_F,EDS_R,EPS2,GS,IDB_PT,POD,VCU_PT
  SG_ DiagReqAllEcuData6 : 55|8@0+ (1,0) [0|255] "" EDS_F,EDS_R,EPS2,GS,IDB_PT,POD,VCU_PT
  SG_ DiagReqAllEcuData7 : 63|8@0+ (1,0) [0|255] "" EDS_F,EDS_R,EPS2,GS,IDB_PT,POD,VCU_PT

BO_ 1793 SEED_CAN_Req1_CCU_R: 8 XGW_PT
  SG_ SEED_CAN_Req1 : 7|64@0+ (1,0) [0|1.84467440737096E+019] "" VCU_PT

BO_ 1795 SEED_CAN_Req2_CCU_F: 8 XGW_PT
  SG_ SEED_CAN_Req2 : 7|64@0+ (1,0) [0|1.84467440737096E+019] "" VCU_PT

BO_ 1801 SEED_CAN_Req5_EDS_R: 8 EDS_R
  SG_ SEED_CAN_Req5 : 7|64@0+ (1,0) [0|1.84467440737096E+019] "" VCU_PT

BO_ 1803 SEED_CAN_Req6_BCM: 8 XGW_PT
  SG_ SEED_CAN_Req6 : 7|64@0+ (1,0) [0|1.84467440737096E+019] "" VCU_PT

BO_ 1805 SEED_CAN_Req7_VCU_PT: 8 VCU_PT
  SG_ SEED_CAN_Req7 : 7|64@0+ (1,0) [0|1.84467440737096E+019] "" ADAS_PT,EDS_F,EDS_R,IDB_PT,POD,XGW_PT

BO_ 1807 SEED_CAN_Req8_ADAS_PT: 8 ADAS_PT
  SG_ SEED_CAN_Req8 : 7|64@0+ (1,0) [0|1.84467440737096E+019] "" VCU_PT

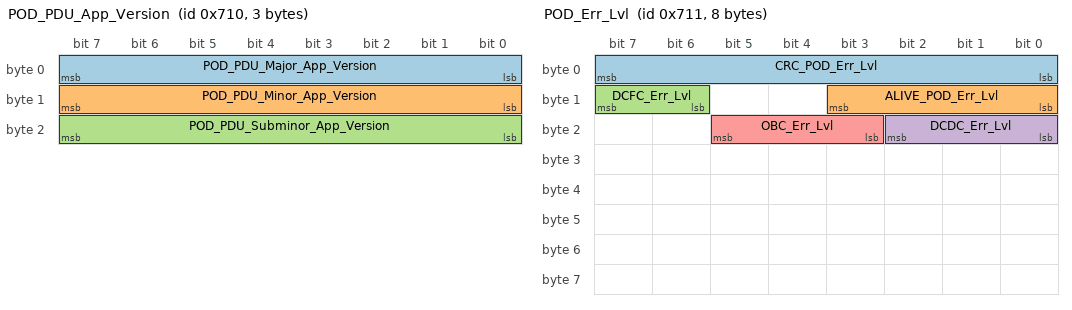
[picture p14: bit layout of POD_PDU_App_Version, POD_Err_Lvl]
BO_ 1808 POD_PDU_App_Version: 3 POD
  SG_ POD_PDU_Major_App_Version : 7|8@0+ (1,0) [0|255] "" DUMMY_POD_TOOL
  SG_ POD_PDU_Minor_App_Version : 15|8@0+ (1,0) [0|255] "" DUMMY_POD_TOOL
  SG_ POD_PDU_Subminor_App_Version : 23|8@0+ (1,0) [0|255] "" DUMMY_POD_TOOL

BO_ 1809 POD_Err_Lvl: 8 POD
  SG_ CRC_POD_Err_Lvl : 7|8@0+ (1,0) [0|255] "" VCU_PT
  SG_ ALIVE_POD_Err_Lvl : 11|4@0+ (1,0) [0|14] "" VCU_PT
  SG_ DCFC_Err_Lvl : 15|2@0+ (1,0) [0|3] "" VCU_PT
  SG_ DCDC_Err_Lvl : 18|3@0+ (1,0) [0|5] "" VCU_PT
  SG_ OBC_Err_Lvl : 21|3@0+ (1,0) [0|5] "" VCU_PT

BO_ 1815 SEED_CAN_Req10_IDB_PT: 8 IDB_PT
  SG_ SEED_CAN_Req10 : 7|64@0+ (1,0) [0|1.84467440737096E+019] "" VCU_PT

BO_ 1843 SEED_CAN_Req18_MHU: 8 XGW_PT
  SG_ SEED_CAN_Req18 : 7|64@0+ (1,0) [0|1.84467440737096E+019] "" VCU_PT

BO_ 1857 SEED_CAN_Req23_EDS_F: 8 EDS_F
  SG_ SEED_CAN_Req23 : 7|64@0+ (1,0) [0|1.84467440737096E+019] "" VCU_PT

BO_ 1859 SEED_CAN_Req22_POD: 8 POD
  SG_ SEED_CAN_Req22 : 7|64@0+ (1,0) [0|1.84467440737096E+019] "" VCU_PT

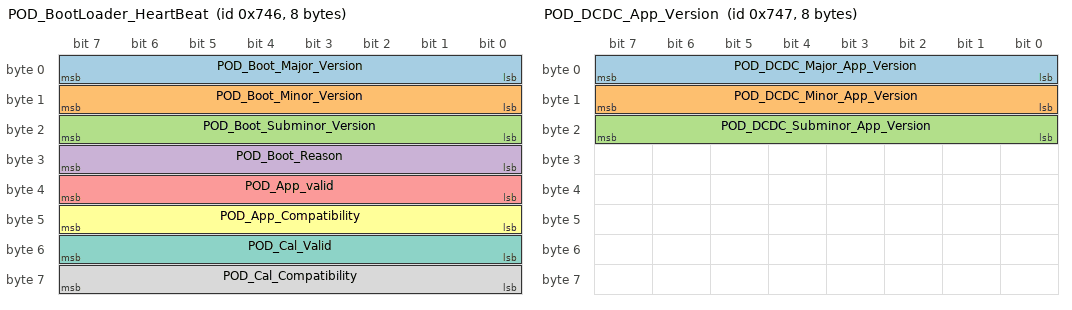
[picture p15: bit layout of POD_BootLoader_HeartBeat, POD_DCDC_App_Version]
BO_ 1862 POD_BootLoader_HeartBeat: 8 POD
  SG_ POD_Boot_Major_Version : 7|8@0+ (1,0) [0|255] "" DUMMY_POD_TOOL
  SG_ POD_Boot_Minor_Version : 15|8@0+ (1,0) [0|255] "" DUMMY_POD_TOOL
  SG_ POD_Boot_Subminor_Version : 23|8@0+ (1,0) [0|255] "" DUMMY_POD_TOOL
  SG_ POD_Boot_Reason : 31|8@0+ (1,0) [0|255] "" DUMMY_POD_TOOL
  SG_ POD_App_valid : 39|8@0+ (1,0) [0|255] "" DUMMY_POD_TOOL
  SG_ POD_App_Compatibility : 47|8@0+ (1,0) [0|255] "" DUMMY_POD_TOOL
  SG_ POD_Cal_Valid : 55|8@0+ (1,0) [0|255] "" DUMMY_POD_TOOL
  SG_ POD_Cal_Compatibility : 63|8@0+ (1,0) [0|255] "" DUMMY_POD_TOOL

BO_ 1863 POD_DCDC_App_Version: 8 POD
  SG_ POD_DCDC_Major_App_Version : 7|8@0+ (1,0) [0|255] "" DUMMY_POD_TOOL
  SG_ POD_DCDC_Minor_App_Version : 15|8@0+ (1,0) [0|255] "" DUMMY_POD_TOOL
  SG_ POD_DCDC_Subminor_App_Version : 23|8@0+ (1,0) [0|255] "" DUMMY_POD_TOOL

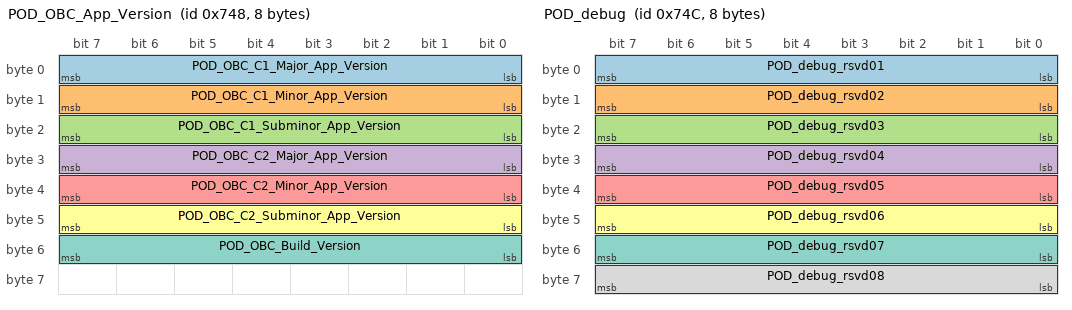
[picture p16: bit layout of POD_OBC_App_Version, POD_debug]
BO_ 1864 POD_OBC_App_Version: 8 POD
  SG_ POD_OBC_C1_Major_App_Version : 7|8@0+ (1,0) [0|255] "" DUMMY_POD_TOOL
  SG_ POD_OBC_C1_Minor_App_Version : 15|8@0+ (1,0) [0|255] "" DUMMY_POD_TOOL
  SG_ POD_OBC_C1_Subminor_App_Version : 23|8@0+ (1,0) [0|255] "" DUMMY_POD_TOOL
  SG_ POD_OBC_C2_Major_App_Version : 31|8@0+ (1,0) [0|255] "" DUMMY_POD_TOOL
  SG_ POD_OBC_C2_Minor_App_Version : 39|8@0+ (1,0) [0|255] "" DUMMY_POD_TOOL
  SG_ POD_OBC_C2_Subminor_App_Version : 47|8@0+ (1,0) [0|255] "" DUMMY_POD_TOOL
  SG_ POD_OBC_Build_Version : 55|8@0+ (1,0) [0|255] "" DUMMY_POD_TOOL

BO_ 1868 POD_debug: 8 POD
  SG_ POD_debug_rsvd01 : 7|8@0+ (1,0) [0|255] "" DUMMY_POD_TOOL
  SG_ POD_debug_rsvd02 : 15|8@0+ (1,0) [0|255] "" DUMMY_POD_TOOL
  SG_ POD_debug_rsvd03 : 23|8@0+ (1,0) [0|255] "" DUMMY_POD_TOOL
  SG_ POD_debug_rsvd04 : 31|8@0+ (1,0) [0|255] "" DUMMY_POD_TOOL
  SG_ POD_debug_rsvd05 : 39|8@0+ (1,0) [0|255] "" DUMMY_POD_TOOL
  SG_ POD_debug_rsvd06 : 47|8@0+ (1,0) [0|255] "" DUMMY_POD_TOOL
  SG_ POD_debug_rsvd07 : 55|8@0+ (1,0) [0|255] "" DUMMY_POD_TOOL
  SG_ POD_debug_rsvd08 : 63|8@0+ (1,0) [0|255] "" DUMMY_POD_TOOL

BO_ 1869 POD_GTW_EventMatrix: 8 POD
  SG_ POD_DCDC_AppVersion_mia : 0|1@0+ (1,0) [0|1] "" VCU_PT
  SG_ POD_OBC_AppVersion_mia : 5|1@0+ (1,0) [0|1] "" VCU_PT
  SG_ POD_DCDC_Status0x326_mia : 8|1@0+ (1,0) [0|1] "" VCU_PT
  SG_ POD_DCDC_Status0x346_mia : 9|1@0+ (1,0) [0|1] "" VCU_PT
  SG_ POD_DCDC_Thermal0x366_mia : 10|1@0+ (1,0) [0|1] "" VCU_PT
  SG_ POD_FC_Status0x327_mia : 11|1@0+ (1,0) [0|1] "" VCU_PT
  SG_ POD_OBC_Status0x313_mia : 12|1@0+ (1,0) [0|1] "" VCU_PT
  SG_ POD_OBC_Status0x323_mia : 13|1@0+ (1,0) [0|1] "" VCU_PT
  SG_ POD_BMS_Status0x249_mia : 14|1@0+ (1,0) [0|1] "" VCU_PT
  SG_ POD_BOOT_Broadcast_mia : 15|1@0+ (1,0) [0|1] "" VCU_PT
  SG_ POD_DCDC_Status0x326_chksum : 16|1@0+ (1,0) [0|1] "" VCU_PT
  SG_ POD_DCDC_Status0x346_chksum : 17|1@0+ (1,0) [0|1] "" VCU_PT
  SG_ POD_DCDC_Thermal0x366_chksum : 18|1@0+ (1,0) [0|1] "" VCU_PT
  SG_ POD_FC_Status0x327_chksum : 19|1@0+ (1,0) [0|1] "" VCU_PT
  SG_ POD_OBC_Status0x313_chksum : 20|1@0+ (1,0) [0|1] "" VCU_PT
  SG_ POD_OBC_Status0x323_chksum : 21|1@0+ (1,0) [0|1] "" VCU_PT
  SG_ POD_BMS_Status0x249_chksum : 22|1@0+ (1,0) [0|1] "" VCU_PT
  SG_ POD_BOOT_Broadcast_chksum : 23|1@0+ (1,0) [0|1] "" VCU_PT
  SG_ POD_OBC_Status0x323_alivecntr : 24|1@0+ (1,0) [0|1] "" VCU_PT
  SG_ POD_DCDC_Status0x346_alivecntr : 25|1@0+ (1,0) [0|1] "" VCU_PT
  SG_ POD_DCDC_Thermal0x366_alivecntr : 26|1@0+ (1,0) [0|1] "" VCU_PT
  SG_ POD_FC_Status0x327_alivecntr : 27|1@0+ (1,0) [0|1] "" VCU_PT
  SG_ POD_OBC_Status0x313_alivecntr : 28|1@0+ (1,0) [0|1] "" VCU_PT
  SG_ POD_DCDC_Status0x326_alivecntr : 29|1@0+ (1,0) [0|1] "" VCU_PT
  SG_ POD_BMS_Status0x249_alivecntr : 30|1@0+ (1,0) [0|1] "" VCU_PT
  SG_ POD_BOOT_Broadcast_alivecntr : 31|1@0+ (1,0) [0|1] "" VCU_PT
  SG_ POD_VCU_NM_mia : 32|1@0+ (1,0) [0|1] "" VCU_PT
  SG_ POD_VCU_ThermalInfoFb_mia : 33|1@0+ (1,0) [0|1] "" VCU_PT
  SG_ POD_VCU_podInfo_mia : 34|1@0+ (1,0) [0|1] "" VCU_PT
  SG_ POD_BMS_Coolant_mia : 38|1@0+ (1,0) [0|1] "" VCU_PT
  SG_ POD_VCU_NM_chksum : 40|1@0+ (1,0) [0|1] "" VCU_PT
  SG_ POD_VCU_ThermalInfoFb_chksum : 41|1@0+ (1,0) [0|1] "" VCU_PT
  SG_ POD_VCU_podInfo_chksum : 42|1@0+ (1,0) [0|1] "" VCU_PT
  SG_ POD_BMS_Coolant_chksum : 46|1@0+ (1,0) [0|1] "" VCU_PT
  SG_ POD_VCU_NM_alivecntr : 48|1@0+ (1,0) [0|1] "" VCU_PT
  SG_ POD_VCU_ThermalInfoFb_alivecntr : 49|1@0+ (1,0) [0|1] "" VCU_PT
  SG_ POD_VCU_podInfo_alivecntr : 50|1@0+ (1,0) [0|1] "" VCU_PT
  SG_ POD_BMS_Coolant_alivecntr : 54|1@0+ (1,0) [0|1] "" VCU_PT

BO_ 1870 POD_OBC_EventMatrix: 8 POD
  SG_ POD_OBC_evt_gtwMIA : 0|1@0+ (1,0) [0|1] "" VCU_PT
  SG_ POD_OBC_evt_fuseOpen : 1|1@0+ (1,0) [0|1] "" VCU_PT
  SG_ POD_OBC_evt_fLineUFWrn : 2|1@0+ (1,0) [0|1] "" VCU_PT
  SG_ POD_OBC_evt_fLineUFFlt : 3|1@0+ (1,0) [0|1] "" VCU_PT
  SG_ POD_OBC_evt_fLineOFWrn : 4|1@0+ (1,0) [0|1] "" VCU_PT
  SG_ POD_OBC_evt_fLineOFFlt : 5|1@0+ (1,0) [0|1] "" VCU_PT
  SG_ POD_OBC_evt_eStopFlt : 6|1@0+ (1,0) [0|1] "" VCU_PT
  SG_ POD_OBC_evt_evsePwrInsufficient : 7|1@0+ (1,0) [0|1] "" VCU_PT
  SG_ POD_OBC_evt_vOutUVWrn : 8|1@0+ (1,0) [0|1] "" VCU_PT
  SG_ POD_OBC_evt_vOutUVFlt : 9|1@0+ (1,0) [0|1] "" VCU_PT
  SG_ POD_OBC_evt_vOutOVWrn : 10|1@0+ (1,0) [0|1] "" VCU_PT
  SG_ POD_OBC_evt_vOutOVFlt : 11|1@0+ (1,0) [0|1] "" VCU_PT
  SG_ POD_OBC_evt_psfbErr : 12|1@0+ (1,0) [0|1] "" VCU_PT
  SG_ POD_OBC_evt_rsvd1 : 13|1@0+ (1,0) [0|1] "" VCU_PT
  SG_ POD_OBC_evt_hwIDInvalid : 14|1@0+ (1,0) [0|1] "" VCU_PT
  SG_ POD_OBC_evt_hwFlt : 15|1@0+ (1,0) [0|1] "" VCU_PT
  SG_ POD_OBC_evt_vLineImbalWrn : 16|1@0+ (1,0) [0|1] "" VCU_PT
  SG_ POD_OBC_evt_vLineImbalFlt : 17|1@0+ (1,0) [0|1] "" VCU_PT
  SG_ POD_OBC_evt_vDCLinkPchgFail : 18|1@0+ (1,0) [0|1] "" VCU_PT
  SG_ POD_OBC_evt_vDCLinkOVWrn : 19|1@0+ (1,0) [0|1] "" VCU_PT
  SG_ POD_OBC_evt_vDCLinkOVFlt : 20|1@0+ (1,0) [0|1] "" VCU_PT
  SG_ POD_OBC_evt_rsvd2 : 21|1@0+ (1,0) [0|1] "" VCU_PT
  SG_ POD_OBC_evt_rsvd3 : 22|1@0+ (1,0) [0|1] "" VCU_PT
  SG_ POD_OBC_evt_vcuMIA : 23|1@0+ (1,0) [0|1] "" VCU_PT
  SG_ POD_OBC_evt_vPhaseDetectFail : 24|1@0+ (1,0) [0|1] "" VCU_PT
  SG_ POD_OBC_evt_vLineUVWrn : 25|1@0+ (1,0) [0|1] "" VCU_PT
  SG_ POD_OBC_evt_vLineUVFlt : 26|1@0+ (1,0) [0|1] "" VCU_PT
  SG_ POD_OBC_evt_vLineOVWrn : 27|1@0+ (1,0) [0|1] "" VCU_PT
  SG_ POD_OBC_evt_vLineOVFlt : 28|1@0+ (1,0) [0|1] "" VCU_PT
  SG_ POD_OBC_evt_rsvd4 : 29|1@0+ (1,0) [0|1] "" VCU_PT
  SG_ POD_OBC_evt_rsvd5 : 30|1@0+ (1,0) [0|1] "" VCU_PT
  SG_ POD_OBC_evt_vLineInterrupted : 31|1@0+ (1,0) [0|1] "" VCU_PT
  SG_ POD_OBC_evt_iLineImbalFlt : 32|1@0+ (1,0) [0|1] "" VCU_PT
  SG_ POD_OBC_evt_iLineOCWrn : 33|1@0+ (1,0) [0|1] "" VCU_PT
  SG_ POD_OBC_evt_iLineOCFlt : 34|1@0+ (1,0) [0|1] "" VCU_PT
  SG_ POD_OBC_evt_tSensorFail : 35|1@0+ (1,0) [0|1] "" VCU_PT
  SG_ POD_OBC_evt_fLineDetWrn : 36|1@0+ (1,0) [0|1] "" VCU_PT
  SG_ POD_OBC_evt_fLineDetFlt : 37|1@0+ (1,0) [0|1] "" VCU_PT
  SG_ POD_OBC_evt_tChargerBoardOTWrn : 38|1@0+ (1,0) [0|1] "" VCU_PT
  SG_ POD_OBC_evt_tChargerBoardOTFlt : 39|1@0+ (1,0) [0|1] "" VCU_PT
  SG_ POD_OBC_evt_iOutNegOCFlt : 40|1@0+ (1,0) [0|1] "" VCU_PT
  SG_ POD_OBC_evt_iOutOCWrn : 41|1@0+ (1,0) [0|1] "" VCU_PT
  SG_ POD_OBC_evt_iOutOCFlt : 42|1@0+ (1,0) [0|1] "" VCU_PT
  SG_ POD_OBC_evt_isoPwrFail : 43|1@0+ (1,0) [0|1] "" VCU_PT
  SG_ POD_OBC_evt_swMismatch : 44|1@0+ (1,0) [0|1] "" VCU_PT
  SG_ POD_OBC_evt_vDCLinkUVWrn : 45|1@0+ (1,0) [0|1] "" VCU_PT
  SG_ POD_OBC_evt_vDCLinkUVFlt : 46|1@0+ (1,0) [0|1] "" VCU_PT
  SG_ POD_OBC_evt_iLineImbalWrn : 47|1@0+ (1,0) [0|1] "" VCU_PT
  SG_ POD_OBC_evt_PfcStartFault : 48|1@0+ (1,0) [0|1] "" VCU_PT
  SG_ POD_OBC_evt_iOutSensorErr : 49|1@0+ (1,0) [0|1] "" VCU_PT
  SG_ POD_OBC_evt_iLine4SensorErr : 50|1@0+ (1,0) [0|1] "" VCU_PT
  SG_ POD_OBC_evt_iLine3SensorErr : 51|1@0+ (1,0) [0|1] "" VCU_PT
  SG_ POD_OBC_evt_iLine2SensorErr : 52|1@0+ (1,0) [0|1] "" VCU_PT
  SG_ POD_OBC_evt_iLine1SensorErr : 53|1@0+ (1,0) [0|1] "" VCU_PT
  SG_ POD_OBC_evt_tColdPlateOTWrn : 54|1@0+ (1,0) [0|1] "" VCU_PT
  SG_ POD_OBC_evt_tColdPlateOTFlt : 55|1@0+ (1,0) [0|1] "" VCU_PT
  SG_ POD_OBC_evt_tChargeBoardUTWrn : 56|1@0+ (1,0) [0|1] "" VCU_PT
  SG_ POD_OBC_evt_tChargeBoardUTFault : 57|1@0+ (1,0) [0|1] "" VCU_PT
  SG_ POD_OBC_evt_tColdPlateUTWrn : 58|1@0+ (1,0) [0|1] "" VCU_PT
  SG_ POD_OBC_evt_tColdPlateUTFault : 59|1@0+ (1,0) [0|1] "" VCU_PT
  SG_ POD_OBC_evt_rsvd6 : 60|1@0+ (1,0) [0|1] "" VCU_PT
  SG_ POD_OBC_evt_rsvd7 : 61|1@0+ (1,0) [0|1] "" VCU_PT
  SG_ POD_OBC_evt_rsvd8 : 62|1@0+ (1,0) [0|1] "" VCU_PT
  SG_ POD_OBC_evt_DualCoreOprtFault : 63|1@0+ (1,0) [0|1] "" VCU_PT

BO_ 1871 POD_DCDC_EventMatrix: 8 POD
  SG_ POD_DCDC_evt_VCU_mia : 0|1@0+ (1,0) [0|1] "" VCU_PT
  SG_ POD_DCDC_evt_GTW_mia : 1|1@0+ (1,0) [0|1] "" VCU_PT
  SG_ POD_DCDC_Evt_Power_mismatch : 2|1@0+ (1,0) [0|1] "" VCU_PT
  SG_ POD_DCDC_evt_HV_Volt_Abnormal : 4|1@0+ (1,0) [0|1] "" VCU_PT
  SG_ POD_DCDC_evt_LV_Volt_Abnormal : 5|1@0+ (1,0) [0|1] "" VCU_PT
  SG_ POD_DCDC_evt_HV_Volt_OFF_Range : 6|1@0+ (1,0) [0|1] "" VCU_PT
  SG_ POD_DCDC_evt_fetTempHigh : 8|1@0+ (1,0) [0|1] "" VCU_PT
  SG_ POD_DCDC_evt_fetTempLow : 9|1@0+ (1,0) [0|1] "" VCU_PT
  SG_ POD_DCDC_evt_ColdplateTempHigh : 10|1@0+ (1,0) [0|1] "" VCU_PT
  SG_ POD_DCDC_evt_ColdplateTempLow : 11|1@0+ (1,0) [0|1] "" VCU_PT
  SG_ POD_DCDC_evt_Busbar_POS_TempHigh : 12|1@0+ (1,0) [0|1] "" VCU_PT
  SG_ POD_DCDC_evt_Busbar_NEG_TempHigh : 13|1@0+ (1,0) [0|1] "" VCU_PT
  SG_ POD_DCDC_evt_NTC_fail_fet : 14|1@0+ (1,0) [0|1] "" VCU_PT
  SG_ POD_DCDC_evt_NTC_Fail_ColdPlate : 15|1@0+ (1,0) [0|1] "" VCU_PT
  SG_ POD_DCDC_evt_NTC_Fail_BB_P : 16|1@0+ (1,0) [0|1] "" VCU_PT
  SG_ POD_DCDC_evt_NTC_Fail_BB_N : 17|1@0+ (1,0) [0|1] "" VCU_PT
  SG_ POD_DCDC_evt_vin_sensor_fail : 20|1@0+ (1,0) [0|1] "" VCU_PT
  SG_ POD_DCDC_evt_HV_IHigh : 24|1@0+ (1,0) [0|1] "" VCU_PT
  SG_ POD_DCDC_evt_HV_VHigh : 25|1@0+ (1,0) [0|1] "" VCU_PT
  SG_ POD_DCDC_evt_HV_VLow : 26|1@0+ (1,0) [0|1] "" VCU_PT
  SG_ POD_DCDC_evt_LV_IHigh : 27|1@0+ (1,0) [0|1] "" VCU_PT
  SG_ POD_DCDC_evt_LV_VHigh : 28|1@0+ (1,0) [0|1] "" VCU_PT
  SG_ POD_DCDC_evt_LV_VLow : 29|1@0+ (1,0) [0|1] "" VCU_PT
  SG_ POD_DCDC_evt_LV_Shortcircuit : 30|1@0+ (1,0) [0|1] "" VCU_PT
  SG_ POD_DCDC_evt_EEPROM_Failure : 31|1@0+ (1,0) [0|1] "" VCU_PT
  SG_ POD_DCDC_evt_Error_Comm : 32|1@0+ (1,0) [0|1] "" VCU_PT
  SG_ POD_DCDC_evt_Cont_welded : 33|1@0+ (1,0) [0|1] "" VCU_PT
  SG_ POD_DCDC_evt_Cont_Stuck_open : 34|1@0+ (1,0) [0|1] "" VCU_PT
  SG_ POD_DCDC_evt_Reverse_I_Protect : 35|1@0+ (1,0) [0|1] "" VCU_PT
  SG_ POD_DCDC_evt_HWTrip_avg_HVCurr : 40|1@0+ (1,0) [0|1] "" VCU_PT
  SG_ POD_DCDC_evt_HWTrip_pri_Current : 41|1@0+ (1,0) [0|1] "" VCU_PT
  SG_ POD_DCDC_evt_HWTrip_LV_Voltage : 42|1@0+ (1,0) [0|1] "" VCU_PT
  SG_ POD_DCDC_evt_SWTrip_HV_Ovp : 43|1@0+ (1,0) [0|1] "" VCU_PT
  SG_ POD_DCDC_evt_SWTrip_LV_Ovp : 44|1@0+ (1,0) [0|1] "" VCU_PT
  SG_ POD_DCDC_evt_SWTrip_LV_Ocp : 45|1@0+ (1,0) [0|1] "" VCU_PT

BO_ 1873 VCU_DebugDiag: 8 VCU_PT
  SG_ VCU_DebugDiag2 : 4|3@0+ (1,0) [0|4] "" DUMMY_ECU,XGW_PT
  SG_ VCU_DebugDiag1 : 7|3@0+ (1,0) [0|4] "" DUMMY_ECU,XGW_PT
  SG_ VCU_DebugDiag5 : 9|3@0+ (1,0) [0|4] "" DUMMY_ECU,XGW_PT
  SG_ VCU_DebugDiag4 : 12|3@0+ (1,0) [0|4] "" DUMMY_ECU,XGW_PT
  SG_ VCU_DebugDiag3 : 15|3@0+ (1,0) [0|4] "" DUMMY_ECU,XGW_PT
  SG_ VCU_DebugDiag8 : 16|3@0+ (1,0) [0|4] "" DUMMY_ECU,XGW_PT
  SG_ VCU_DebugDiag7 : 19|3@0+ (1,0) [0|4] "" DUMMY_ECU,XGW_PT
  SG_ VCU_DebugDiag6 : 22|3@0+ (1,0) [0|4] "" DUMMY_ECU,XGW_PT
  SG_ VCU_DebugDiag10 : 26|3@0+ (1,0) [0|4] "" DUMMY_ECU,XGW_PT
  SG_ VCU_DebugDiag9 : 29|3@0+ (1,0) [0|4] "" DUMMY_ECU,XGW_PT
  SG_ VCU_DebugDiag13 : 33|3@0+ (1,0) [0|4] "" DUMMY_ECU,XGW_PT
  SG_ VCU_DebugDiag12 : 36|3@0+ (1,0) [0|4] "" DUMMY_ECU,XGW_PT
  SG_ VCU_DebugDiag11 : 39|3@0+ (1,0) [0|4] "" DUMMY_ECU,XGW_PT
  SG_ VCU_DebugDiag16 : 40|3@0+ (1,0) [0|4] "" DUMMY_ECU,XGW_PT
  SG_ VCU_DebugDiag15 : 43|3@0+ (1,0) [0|4] "" DUMMY_ECU,XGW_PT
  SG_ VCU_DebugDiag14 : 46|3@0+ (1,0) [0|4] "" DUMMY_ECU,XGW_PT
  SG_ VCU_DebugDiag18 : 50|3@0+ (1,0) [0|4] "" DUMMY_ECU,XGW_PT
  SG_ VCU_DebugDiag17 : 53|3@0+ (1,0) [0|4] "" DUMMY_ECU,XGW_PT
  SG_ VCU_DebugDiag20 : 60|3@0+ (1,0) [0|4] "" DUMMY_ECU,XGW_PT
  SG_ VCU_DebugDiag19 : 63|3@0+ (1,0) [0|4] "" DUMMY_ECU,XGW_PT

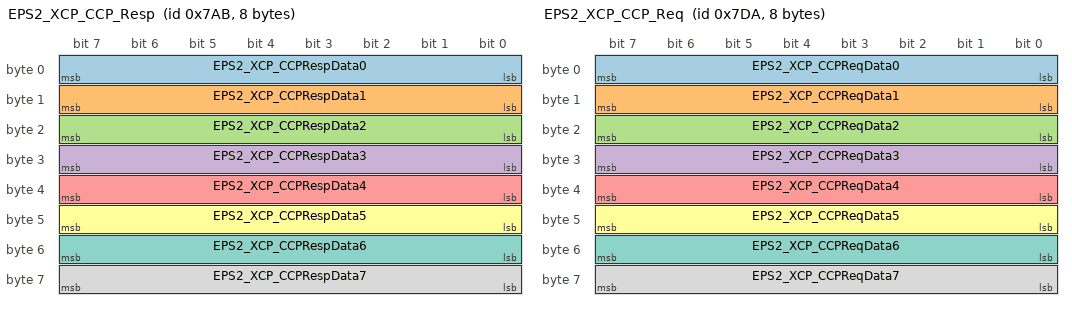
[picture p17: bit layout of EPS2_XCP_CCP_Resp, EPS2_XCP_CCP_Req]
BO_ 1963 EPS2_XCP_CCP_Resp: 8 EPS2
  SG_ EPS2_XCP_CCPRespData0 : 7|8@0+ (1,0) [0|255] "" DUMMY_ECU
  SG_ EPS2_XCP_CCPRespData1 : 15|8@0+ (1,0) [0|255] "" DUMMY_ECU
  SG_ EPS2_XCP_CCPRespData2 : 23|8@0+ (1,0) [0|255] "" DUMMY_ECU
  SG_ EPS2_XCP_CCPRespData3 : 31|8@0+ (1,0) [0|255] "" DUMMY_ECU
  SG_ EPS2_XCP_CCPRespData4 : 39|8@0+ (1,0) [0|255] "" DUMMY_ECU
  SG_ EPS2_XCP_CCPRespData5 : 47|8@0+ (1,0) [0|255] "" DUMMY_ECU
  SG_ EPS2_XCP_CCPRespData6 : 55|8@0+ (1,0) [0|255] "" DUMMY_ECU
  SG_ EPS2_XCP_CCPRespData7 : 63|8@0+ (1,0) [0|255] "" DUMMY_ECU

BO_ 2010 EPS2_XCP_CCP_Req: 8 DUMMY_ECU
  SG_ EPS2_XCP_CCPReqData0 : 7|8@0+ (1,0) [0|255] "" EPS2
  SG_ EPS2_XCP_CCPReqData1 : 15|8@0+ (1,0) [0|255] "" EPS2
  SG_ EPS2_XCP_CCPReqData2 : 23|8@0+ (1,0) [0|255] "" EPS2
  SG_ EPS2_XCP_CCPReqData3 : 31|8@0+ (1,0) [0|255] "" EPS2
  SG_ EPS2_XCP_CCPReqData4 : 39|8@0+ (1,0) [0|255] "" EPS2
  SG_ EPS2_XCP_CCPReqData5 : 47|8@0+ (1,0) [0|255] "" EPS2
  SG_ EPS2_XCP_CCPReqData6 : 55|8@0+ (1,0) [0|255] "" EPS2
  SG_ EPS2_XCP_CCPReqData7 : 63|8@0+ (1,0) [0|255] "" EPS2

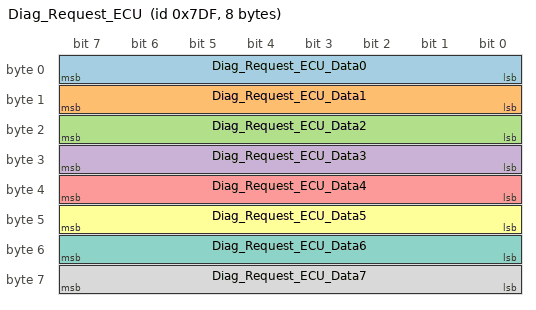
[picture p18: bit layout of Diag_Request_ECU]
BO_ 2015 Diag_Request_ECU: 8 XGW_PT
  SG_ Diag_Request_ECU_Data0 : 7|8@0+ (1,0) [0|255] "" EDS_F,EDS_R,EPS2,GS,IDB_PT,POD,VCU_PT
  SG_ Diag_Request_ECU_Data1 : 15|8@0+ (1,0) [0|255] "-" EDS_F,EDS_R,EPS2,GS,IDB_PT,POD,VCU_PT
  SG_ Diag_Request_ECU_Data2 : 23|8@0+ (1,0) [0|255] "-" EDS_F,EDS_R,EPS2,GS,IDB_PT,POD,VCU_PT
  SG_ Diag_Request_ECU_Data3 : 31|8@0+ (1,0) [0|255] "" EDS_F,EDS_R,EPS2,GS,IDB_PT,POD,VCU_PT
  SG_ Diag_Request_ECU_Data4 : 39|8@0+ (1,0) [0|255] "-" EDS_F,EDS_R,EPS2,GS,IDB_PT,POD,VCU_PT
  SG_ Diag_Request_ECU_Data5 : 47|8@0+ (1,0) [0|255] "" EDS_F,EDS_R,EPS2,GS,IDB_PT,POD,VCU_PT
  SG_ Diag_Request_ECU_Data6 : 55|8@0+ (1,0) [0|255] "-" EDS_F,EDS_R,EPS2,GS,IDB_PT,POD,VCU_PT
  SG_ Diag_Request_ECU_Data7 : 63|8@0+ (1,0) [0|255] "" EDS_F,EDS_R,EPS2,GS,IDB_PT,POD,VCU_PT

CM_ BO_ 1110 "SCM_Raw_Status";
CM_ BO_ 1168 "GS Warning message";
CM_ BO_ 1178 "EDS Rear Warning message";
CM_ BO_ 1179 "EDS Front Warning message";
CM_ BO_ 1195 "EPS2 warning message";
CM_ BO_ 1196 "VCU Warning message";
CM_ BO_ 1213 "POD WarnMsg";
CM_ BO_ 1282 "XGW Network Management";
CM_ BO_ 1306 "EDS Rear Network Management";
CM_ BO_ 1307 "EDS Front Network Management";
CM_ BO_ 1324 "VCU Network Management";
CM_ BO_ 1344 "ADAS NM";
CM_ BO_ 1552 "GS Diagnostic Responde";
CM_ BO_ 1562 "EDS Rear Diagnostic Responde";
CM_ BO_ 1563 "EDS Front Diagnostic Responde";
CM_ BO_ 1575 "Diagnostic Response for RCU     ";
CM_ BO_ 1577 "IDB Diagnostic Response";
CM_ BO_ 1579 "Diagnostic Response for EPS2     ";
CM_ BO_ 1580 "VCU Diagnostic Responde";
CM_ BO_ 1597 "POD DCDC Diagnostic Response";
CM_ BO_ 1598 "POD OBC Diagnostic Response";
CM_ BO_ 1599 "POD Diagnostic Response";
CM_ BO_ 1605 "Response message for Flashing of OBC CPU1";
CM_ BO_ 1680 "GS Diagnostic Request";
CM_ BO_ 1690 "EDS Rear Diagnostic Request";
CM_ BO_ 1691 "EDS Front Diagnostic Request";
CM_ BO_ 1703 "Diagnostic Request for RCU     ";
CM_ BO_ 1705 "IDB Diagnostic Request";
CM_ BO_ 1707 "Diagnostic Request for EPS2     ";
CM_ BO_ 1708 "VCU Diagnostic Request";
CM_ BO_ 1725 "POD DCDC Diagnostic Request";
CM_ BO_ 1726 "POD OBC Diagnostic Request";
CM_ BO_ 1727 "POD Diagnostic Request";
CM_ BO_ 1733 "Request message for Flashing of OBC CPU1";
CM_ BO_ 1775 "Diagnostic Request for all CAN";
CM_ BO_ 1791 "Diagnostic Request for all ECUs";
CM_ BO_ 1793 "SEED_CAN_Req1";
CM_ BO_ 1795 "SEED_CAN_Req2";
CM_ BO_ 1801 "SEED CAN Req5";
CM_ BO_ 1803 "SEED_CAN_Req6";
CM_ BO_ 1805 "SEED_CAN_Req7";
CM_ BO_ 1807 "SEED_CAN_Req8";
CM_ BO_ 1808 "POD PDU App Version";
CM_ BO_ 1809 "POD Error Level";
CM_ BO_ 1815 "SEED_CAN_Req10";
CM_ BO_ 1843 "SEED_CAN_Req18";
CM_ BO_ 1857 "SEED CAN Req 23";
CM_ BO_ 1859 "SEED CAN Req 22";
CM_ BO_ 1862 "POD heartBeatBoot";
CM_ BO_ 1863 "POD DCDC App Version";
CM_ BO_ 1864 "POD OBC App Version";
CM_ BO_ 1869 "POD Gateway Event Matrix";
CM_ BO_ 1870 "OBC's event matrix";
CM_ BO_ 1871 "DC DC Event Matrix";
CM_ BO_ 1873 "VCU_DebugDiag";
CM_ BO_ 1963 "CCP XCP tool response";
CM_ BO_ 2010 "CCP XCP tool request";
CM_ BO_ 2015 "Diagnostic Request for all ECUs";
CM_ SG_ 1110 OP_WISW_SZL_LIN "Wiper Status Signal (Right Stalk)
Bit 0~1 : Switch status on Automatic wiping, Wiper step 1, Wiper step 2 switch status
Bit 2: Not used.(this bit is always 0.)
Bit 3: Front mist switch status
Bit 4: Front washer switch status
Bit 5: Not used.(this bit is always 0.)
Bit 6: Rear wiping switch status
Bit 7: Rear washing switch status
* 1111 1111: Signal Invalid
";
CM_ SG_ 1110 COMM_ERR_SZL_LIN "This signal showes if there is or was a communication error.";
CM_ SG_ 1110 BCM_Wiper_Front_Status "Front Wiper Motor Feedback of status";
CM_ SG_ 1110 OP_WIPO_SZL_LIN "Wiper Step (Right Stalk)
0x0: Step 1
0x1: Step 2
0x2: Step 3
0x4: Step 4
0x7: signal invalid
";
CM_ SG_ 1110 OP_COLS_SZL_LIN "Left Stalk Lever Signal (Light function)
*the status of each bit follows this: (0: Off, 1: ON)
Bit 0: Highway flashing right indicator status
Bit 1: Flashing right indicator status
Bit 2: Highway flashing left indicator status
Bit 3: Flashing left indicator status
Bit 4: High-beam light status
Bit 5: High-beam light flashing status
Bit 6: Reserved
Bit 7: Not used.(this value is always ?0?)
* 1111 1111: Signal Invalid";
CM_ SG_ 1110 NOD_ERR_SZL_LIN "If SCM detects any error (any error status occurred), SCM sends this signal as ?error active?.";
CM_ SG_ 1110 BCM_Wiper_Rear_Status "Rear wiper status check";
CM_ SG_ 1110 ALIV_WISW_SZL_LIN "Standard Alive-counter for validation of the transmission between SCM and Master ECU.";
CM_ SG_ 1168 CHSKM_GS_WarnMsg "Checksum";
CM_ SG_ 1168 ALV_GS_WarnMsg "Alive Counter";
CM_ SG_ 1168 GS_Warning_Flag_1 "P BUTTON FAULT ERROR";
CM_ SG_ 1168 GS_Warning_Flag_2 "R BUTTON FAULT ERROR";
CM_ SG_ 1168 GS_Warning_Flag_3 "N BUTTON FAULT ERROR";
CM_ SG_ 1168 GS_Warning_Flag_4 "D BUTTON FAULT ERROR";
CM_ SG_ 1168 GS_Warning_Flag_5 "P BUTTON STUCK FAULT ERROR";
CM_ SG_ 1168 GS_Warning_Flag_6 "R BUTTON STUCK FAULT ERROR";
CM_ SG_ 1168 GS_Warning_Flag_7 "N BUTTON STUCK FAULT ERROR";
CM_ SG_ 1168 GS_Warning_Flag_8 "D BUTTON STUCK FAULT ERROR";
CM_ SG_ 1168 GS_Warning_Flag_9 "Warning Message Flag, Component owner, Supplier align and define for this signal";
CM_ SG_ 1168 GS_Warning_Flag_10 "Warning Message Flag, Component owner, Supplier align and define for this signal";
CM_ SG_ 1168 GS_Warning_Flag_11 "Warning Message Flag, Component owner, Supplier align and define for this signal";
CM_ SG_ 1168 GS_Warning_Flag_12 "Warning Message Flag, Component owner, Supplier align and define for this signal";
CM_ SG_ 1168 GS_Reserved_signal1 "Warning Message Flag, Component owner, Supplier align and define for this signal";
CM_ SG_ 1168 GS_Reserved_signal2 "Warning Message Flag, Component owner, Supplier align and define for this signal";
CM_ SG_ 1168 GS_Reserved_signal3 "Warning Message Flag, Component owner, Supplier align and define for this signal";
CM_ SG_ 1168 GS_Reserved_signal4 "Warning Message Flag, Component owner, Supplier align and define for this signal";
CM_ SG_ 1168 GS_Reserved_signal5 "Warning Message Flag, Component owner, Supplier align and define for this signal";
CM_ SG_ 1178 CHSKM_EDS_R_WarnMsg "Checksum";
CM_ SG_ 1178 ALV_EDS_R_WarnMsg "Alive Counter";
CM_ SG_ 1178 EDS_R_Warning_Flag_1 "Warning Message Flag, Component owner, Supplier align and define for this signal";
CM_ SG_ 1178 EDS_R_Warning_Flag_2 "Warning Message Flag, Component owner, Supplier align and define for this signal";
CM_ SG_ 1178 EDS_R_Warning_Flag_3 "Warning Message Flag, Component owner, Supplier align and define for this signal";
CM_ SG_ 1178 EDS_R_Warning_Flag_4 "Warning Message Flag, Component owner, Supplier align and define for this signal";
CM_ SG_ 1178 EDS_R_Warning_Flag_5 "Warning Message Flag, Component owner, Supplier align and define for this signal";
CM_ SG_ 1178 EDS_R_Warning_Flag_6 "Warning Message Flag, Component owner, Supplier align and define for this signal";
CM_ SG_ 1178 EDS_R_Warning_Flag_7 "Warning Message Flag, Component owner, Supplier align and define for this signal";
CM_ SG_ 1178 EDS_R_Warning_Flag_8 "Warning Message Flag, Component owner, Supplier align and define for this signal";
CM_ SG_ 1178 EDS_R_Warning_Flag_9 "Warning Message Flag, Component owner, Supplier align and define for this signal";
CM_ SG_ 1178 EDS_R_Warning_Flag_10 "Warning Message Flag, Component owner, Supplier align and define for this signal";
CM_ SG_ 1178 EDS_R_Warning_Flag_11 "Warning Message Flag, Component owner, Supplier align and define for this signal";
CM_ SG_ 1178 EDS_R_Warning_Flag_12 "Warning Message Flag, Component owner, Supplier align and define for this signal";
CM_ SG_ 1178 EDS_R_Reserved_signal1 "Warning Message Flag, Component owner, Supplier align and define for this signal";
CM_ SG_ 1178 EDS_R_Reserved_signal2 "Warning Message Flag, Component owner, Supplier align and define for this signal";
CM_ SG_ 1178 EDS_R_Reserved_signal3 "Warning Message Flag, Component owner, Supplier align and define for this signal";
CM_ SG_ 1178 EDS_R_Reserved_signal4 "Warning Message Flag, Component owner, Supplier align and define for this signal";
CM_ SG_ 1178 EDS_R_Reserved_signal5 "Warning Message Flag, Component owner, Supplier align and define for this signal";
CM_ SG_ 1179 CHSKM_EDS_F_WarnMsg "Checksum";
CM_ SG_ 1179 ALV_EDS_F_WarnMsg "Alive Counter";
CM_ SG_ 1179 EDS_F_Warning_Flag_1 "Warning Message Flag, Component owner, Supplier align and define for this signal";
CM_ SG_ 1179 EDS_F_Warning_Flag_2 "Warning Message Flag, Component owner, Supplier align and define for this signal";
CM_ SG_ 1179 EDS_F_Warning_Flag_3 "Warning Message Flag, Component owner, Supplier align and define for this signal";
CM_ SG_ 1179 EDS_F_Warning_Flag_4 "Warning Message Flag, Component owner, Supplier align and define for this signal";
CM_ SG_ 1179 EDS_F_Warning_Flag_5 "Warning Message Flag, Component owner, Supplier align and define for this signal";
CM_ SG_ 1179 EDS_F_Warning_Flag_6 "Warning Message Flag, Component owner, Supplier align and define for this signal";
CM_ SG_ 1179 EDS_F_Warning_Flag_7 "Warning Message Flag, Component owner, Supplier align and define for this signal";
CM_ SG_ 1179 EDS_F_Warning_Flag_8 "Warning Message Flag, Component owner, Supplier align and define for this signal";
CM_ SG_ 1179 EDS_F_Warning_Flag_9 "Warning Message Flag, Component owner, Supplier align and define for this signal";
CM_ SG_ 1179 EDS_F_Warning_Flag_10 "Warning Message Flag, Component owner, Supplier align and define for this signal";
CM_ SG_ 1179 EDS_F_Warning_Flag_11 "Warning Message Flag, Component owner, Supplier align and define for this signal";
CM_ SG_ 1179 EDS_F_Warning_Flag_12 "Warning Message Flag, Component owner, Supplier align and define for this signal";
CM_ SG_ 1179 EDS_F_Reserved_signal1 "Warning Message Flag, Component owner, Supplier align and define for this signal";
CM_ SG_ 1179 EDS_F_Reserved_signal2 "Warning Message Flag, Component owner, Supplier align and define for this signal";
CM_ SG_ 1179 EDS_F_Reserved_signal3 "Warning Message Flag, Component owner, Supplier align and define for this signal";
CM_ SG_ 1179 EDS_F_Reserved_signal4 "Warning Message Flag, Component owner, Supplier align and define for this signal";
CM_ SG_ 1179 EDS_F_Reserved_signal5 "Warning Message Flag, Component owner, Supplier align and define for this signal";
CM_ SG_ 1195 CHSKM_EPS2_WarnMsg "Checksum";
CM_ SG_ 1195 ALV_EPS2_WarnMsg "Alive Counter";
CM_ SG_ 1195 EPS2_Malfunction "EPS2 malfunction, No Power Assistance Steering Available";
CM_ SG_ 1195 EPS2_Reduced "EPS2 reduced, Power Steering Assistance Reduced";
CM_ SG_ 1195 EPS2_Overheat "EPS2 Overheat, No Power Assistance Steering Available";
CM_ SG_ 1195 EPS2_NotReady "EPS2 is not ready, No Power Assistance Steering Available";
CM_ SG_ 1195 EPS2_Warning_Flag_5 "Warning Message Flag, Component owner, Supplier align and define for this signal";
CM_ SG_ 1195 EPS2_Warning_Flag_6 "Warning Message Flag, Component owner, Supplier align and define for this signal";
CM_ SG_ 1195 EPS2_Warning_Flag_7 "Warning Message Flag, Component owner, Supplier align and define for this signal";
CM_ SG_ 1195 EPS2_Warning_Flag_8 "Warning Message Flag, Component owner, Supplier align and define for this signal";
CM_ SG_ 1195 EPS2_Warning_Flag_9 "Warning Message Flag, Component owner, Supplier align and define for this signal";
CM_ SG_ 1195 EPS2_Warning_Flag_10 "Warning Message Flag, Component owner, Supplier align and define for this signal";
CM_ SG_ 1195 EPS2_Warning_Flag_11 "Warning Message Flag, Component owner, Supplier align and define for this signal";
CM_ SG_ 1195 EPS2_Warning_Flag_12 "Warning Message Flag, Component owner, Supplier align and define for this signal";
CM_ SG_ 1195 EPS2_Reserved_signal1 "Warning Message Flag, Component owner, Supplier align and define for this signal";
CM_ SG_ 1195 EPS2_Reserved_signal2 "Warning Message Flag, Component owner, Supplier align and define for this signal";
CM_ SG_ 1195 EPS2_Reserved_signal3 "Warning Message Flag, Component owner, Supplier align and define for this signal";
CM_ SG_ 1195 EPS2_Reserved_signal4 "Warning Message Flag, Component owner, Supplier align and define for this signal";
CM_ SG_ 1195 EPS2_Reserved_signal5 "Warning Message Flag, Component owner, Supplier align and define for this signal";
CM_ SG_ 1196 CHSKM_VCU_WarnMsg "Checksum";
CM_ SG_ 1196 ALV_VCU_WarnMsg "Alive Counter";
CM_ SG_ 1196 VCU_GearPOnlyAtStationaryAlert "Gear position P only when stationary";
CM_ SG_ 1196 VCU_GearP_NotPossibleAlert "Gear P not possible,  Due to EPP lock is not possible, gear position P may not be possible.";
CM_ SG_ 1196 VCU_PressBrakeToEngageGear "Press Brake to engage gear hint";
CM_ SG_ 1196 VCU_CantChangeGear "Unable to change gear position";
CM_ SG_ 1196 VCU_GearMalfunction "Gear change might be not possible, Possibly faulty selector lever";
CM_ SG_ 1196 VCU_RangeAlert "The range warning, charging soon";
CM_ SG_ 1196 VCU_HVSystemReduced "Reduced HV System Power";
CM_ SG_ 1196 VCU_FrontEDSReduced "Reduced Front EDS Power";
CM_ SG_ 1196 VCU_FrontEDS_Malfunc "Front EDS malfunction";
CM_ SG_ 1196 VCU_RearEDSReduced "Reduced Rear EDS Power";
CM_ SG_ 1196 VCU_RearEDS_Malfunc "Rear EDS malfunction";
CM_ SG_ 1196 VCU_CoolingSystem_Malfunc "EV Cooling system malfunction";
CM_ SG_ 1196 VCU_NeutralRequest "Neutral request warning";
CM_ SG_ 1196 VCU_SoftShutdown "Soft shutdown warning";
CM_ SG_ 1196 VCU_EmergencyShutdown "Emergency Shutdown warning";
CM_ SG_ 1196 VCU_ChgPortDoorSys_Malfunc "Charging Port Door Defective";
CM_ SG_ 1196 VCU_Gearchange_NotPossible "During Game Mode, or charging gun attached, gear change not possible";
CM_ SG_ 1196 VCU_12v_Warning "VCU warning for 12v battery based on data received from BCM ";
CM_ SG_ 1196 VCU_WflagRes19 "Reserved VCU Warning message";
CM_ SG_ 1196 VCU_WflagRes20 "Reserved VCU Warning message";
CM_ SG_ 1196 VCU_WflagRes21 "Reserved VCU Warning message";
CM_ SG_ 1196 VCU_WflagRes22 "Reserved VCU Warning message";
CM_ SG_ 1196 VCU_WflagRes23 "Reserved VCU Warning message";
CM_ SG_ 1196 VCU_WflagRes24 "Reserved VCU Warning message";
CM_ SG_ 1196 VCU_WflagRes25 "Reserved VCU Warning message";
CM_ SG_ 1196 VCU_WflagRes26 "Reserved VCU Warning message";
CM_ SG_ 1196 VCU_WflagRes27 "Reserved VCU Warning message";
CM_ SG_ 1196 VCU_SuperFastCharge_longer "VCU SuperFastCharge longer";
CM_ SG_ 1196 VCU_Reserved_signal1 "Warning Message Flag, Component owner, Supplier align and define for this signal";
CM_ SG_ 1196 VCU_Reserved_signal2 "Warning Message Flag, Component owner, Supplier align and define for this signal";
CM_ SG_ 1196 VCU_Reserved_signal3 "Warning Message Flag, Component owner, Supplier align and define for this signal";
CM_ SG_ 1213 CHSKM_POD_WarnMsg "Checksum";
CM_ SG_ 1213 ALV_POD_WarnMsg "Alive Counter";
CM_ SG_ 1213 POD_Warning_Flag_1 "Warning Message Flag, Component owner, Supplier align and define for this signal";
CM_ SG_ 1213 POD_Warning_Flag_2 "Warning Message Flag, Component owner, Supplier align and define for this signal";
CM_ SG_ 1213 POD_Warning_Flag_3 "Warning Message Flag, Component owner, Supplier align and define for this signal";
CM_ SG_ 1213 POD_Warning_Flag_4 "Warning Message Flag, Component owner, Supplier align and define for this signal";
CM_ SG_ 1213 POD_Warning_Flag_5 "Warning Message Flag, Component owner, Supplier align and define for this signal";
CM_ SG_ 1213 POD_Warning_Flag_6 "Warning Message Flag, Component owner, Supplier align and define for this signal";
CM_ SG_ 1213 POD_Warning_Flag_7 "Warning Message Flag, Component owner, Supplier align and define for this signal";
CM_ SG_ 1213 POD_Warning_Flag_8 "Warning Message Flag, Component owner, Supplier align and define for this signal";
CM_ SG_ 1213 POD_Warning_Flag_9 "Warning Message Flag, Component owner, Supplier align and define for this signal";
CM_ SG_ 1213 POD_Warning_Flag_10 "Warning Message Flag, Component owner, Supplier align and define for this signal";
CM_ SG_ 1213 POD_Warning_Flag_11 "Warning Message Flag, Component owner, Supplier align and define for this signal";
CM_ SG_ 1213 POD_Warning_Flag_12 "Warning Message Flag, Component owner, Supplier align and define for this signal";
CM_ SG_ 1213 POD_Warning_Flag_13 "Warning Message Flag, Component owner, Supplier align and define for this signal";
CM_ SG_ 1213 POD_Warning_Flag_14 "Warning Message Flag, Component owner, Supplier align and define for this signal";
CM_ SG_ 1213 POD_Warning_Flag_15 "Warning Message Flag, Component owner, Supplier align and define for this signal";
CM_ SG_ 1213 POD_Warning_Flag_16 "Warning Message Flag, Component owner, Supplier align and define for this signal";
CM_ SG_ 1213 POD_Warning_Flag_17 "Warning Message Flag, Component owner, Supplier align and define for this signal";
CM_ SG_ 1213 POD_Warning_Flag_18 "Warning Message Flag, Component owner, Supplier align and define for this signal";
CM_ SG_ 1213 POD_Warning_Flag_19 "Warning Message Flag, Component owner, Supplier align and define for this signal";
CM_ SG_ 1213 POD_Warning_Flag_20 "Warning Message Flag, Component owner, Supplier align and define for this signal";
CM_ SG_ 1213 POD_Warning_Flag_21 "Warning Message Flag, Component owner, Supplier align and define for this signal";
CM_ SG_ 1213 POD_Warning_Flag_22 "Warning Message Flag, Component owner, Supplier align and define for this signal";
CM_ SG_ 1213 POD_Warning_Flag_23 "Warning Message Flag, Component owner, Supplier align and define for this signal";
CM_ SG_ 1213 POD_Warning_Flag_24 "Warning Message Flag, Component owner, Supplier align and define for this signal";
CM_ SG_ 1213 POD_Warning_Flag_25 "Warning Message Flag, Component owner, Supplier align and define for this signal";
CM_ SG_ 1213 POD_Warning_Flag_26 "Warning Message Flag, Component owner, Supplier align and define for this signal";
CM_ SG_ 1213 POD_Warning_Flag_27 "Warning Message Flag, Component owner, Supplier align and define for this signal";
CM_ SG_ 1213 POD_Warning_Flag_28 "Warning Message Flag, Component owner, Supplier align and define for this signal";
CM_ SG_ 1213 POD_Reserved_signal3 "Warning Message Flag, Component owner, Supplier align and define for this signal";
CM_ SG_ 1213 POD_Reserved_signal4 "Warning Message Flag, Component owner, Supplier align and define for this signal";
CM_ SG_ 1213 POD_Reserved_signal5 "Warning Message Flag, Component owner, Supplier align and define for this signal";
CM_ SG_ 1282 XGW_srcNodeID "Network Management Signal";
CM_ SG_ 1282 XGW_CtrlBitVector "Network Management Signal";
CM_ SG_ 1282 XGW_usrData0 "Network Management Signal";
CM_ SG_ 1282 XGW_usrData1 "Network Management Signal";
CM_ SG_ 1282 XGW_usrData2 "Network Management Signal";
CM_ SG_ 1282 XGW_usrData3 "Network Management Signal";
CM_ SG_ 1282 XGW_usrData4 "Network Management Signal";
CM_ SG_ 1282 XGW_usrData5 "Network Management Signal";
CM_ SG_ 1306 EDS_R_srcNodeID "Network Management Signal";
CM_ SG_ 1306 EDS_R_CtrlBitVector "Network Management Signal";
CM_ SG_ 1306 EDS_R_usrData0 "Network Management Signal";
CM_ SG_ 1306 EDS_R_usrData1 "Network Management Signal";
CM_ SG_ 1306 EDS_R_usrData2 "Network Management Signal";
CM_ SG_ 1306 EDS_R_usrData3 "Network Management Signal";
CM_ SG_ 1306 EDS_R_usrData4 "Network Management Signal";
CM_ SG_ 1306 EDS_R_usrData5 "Network Management Signal";
CM_ SG_ 1307 EDS_F_srcNodeID "Network Management Signal";
CM_ SG_ 1307 EDS_F_CtrlBitVector "Network Management Signal";
CM_ SG_ 1307 EDS_F_usrData0 "Network Management Signal";
CM_ SG_ 1307 EDS_F_usrData1 "Network Management Signal";
CM_ SG_ 1307 EDS_F_usrData2 "Network Management Signal";
CM_ SG_ 1307 EDS_F_usrData3 "Network Management Signal";
CM_ SG_ 1307 EDS_F_usrData4 "Network Management Signal";
CM_ SG_ 1307 EDS_F_usrData5 "Network Management Signal";
CM_ SG_ 1324 VCU_srcNodeID "Network Management Signal";
CM_ SG_ 1324 VCU_CtrlBitVector "Network Management Signal";
CM_ SG_ 1324 VCU_usrData0 "Network Management Signal";
CM_ SG_ 1324 VCU_usrData1 "Network Management Signal";
CM_ SG_ 1324 VCU_usrData2 "Network Management Signal";
CM_ SG_ 1324 VCU_usrData3 "Network Management Signal";
CM_ SG_ 1324 VCU_usrData4 "Network Management Signal";
CM_ SG_ 1324 VCU_usrData5 "Network Management Signal";
CM_ SG_ 1344 ADAS_srcNodeID "Network Management Signal";
CM_ SG_ 1344 ADAS_CtrlBitVector "Network Management Signal";
CM_ SG_ 1344 ADAS_usrData0 "Network Management Signal";
CM_ SG_ 1344 ADAS_usrData1 "Network Management Signal";
CM_ SG_ 1344 ADAS_usrData2 "Network Management Signal";
CM_ SG_ 1344 ADAS_usrData3 "Network Management Signal";
CM_ SG_ 1344 ADAS_usrData4 "Network Management Signal";
CM_ SG_ 1344 ADAS_usrData5 "Network Management Signal";
CM_ SG_ 1552 GS_DiagRespData0 "Remote Diagnostic signal Data response";
CM_ SG_ 1552 GS_DiagRespData1 "Diagnostic signal Data response";
CM_ SG_ 1552 GS_DiagRespData2 "Remote Diagnostic signal Data response";
CM_ SG_ 1552 GS_DiagRespData3 "Diagnostic signal Data response";
CM_ SG_ 1552 GS_DiagRespData4 "Diagnostic signal Data response";
CM_ SG_ 1552 GS_DiagRespData5 "Diagnostic signal Data response";
CM_ SG_ 1552 GS_DiagRespData6 "Remote Diagnostic signal Data response";
CM_ SG_ 1552 GS_DiagRespData7 "Diagnostic signal Data response";
CM_ SG_ 1562 EDS_R_DiagRespData0 "Diagnostic signal Data response";
CM_ SG_ 1562 EDS_R_DiagRespData1 "Diagnostic signal Data response";
CM_ SG_ 1562 EDS_R_DiagRespData2 "Remote Diagnostic signal Data response";
CM_ SG_ 1562 EDS_R_DiagRespData3 "Diagnostic signal Data response";
CM_ SG_ 1562 EDS_R_DiagRespData4 "Diagnostic signal Data response";
CM_ SG_ 1562 EDS_R_DiagRespData5 "Remote Diagnostic signal Data response";
CM_ SG_ 1562 EDS_R_DiagRespData6 "Remote Diagnostic signal Data response";
CM_ SG_ 1562 EDS_R_DiagRespData7 "Remote Diagnostic signal Data response";
CM_ SG_ 1563 EDS_F_DiagRespData0 "Diagnostic signal Data response";
CM_ SG_ 1563 EDS_F_DiagRespData1 "Diagnostic signal Data response";
CM_ SG_ 1563 EDS_F_DiagRespData2 "Remote Diagnostic signal Data response";
CM_ SG_ 1563 EDS_F_DiagRespData3 "Diagnostic signal Data response";
CM_ SG_ 1563 EDS_F_DiagRespData4 "Diagnostic signal Data response";
CM_ SG_ 1563 EDS_F_DiagRespData5 "Diagnostic signal Data response";
CM_ SG_ 1563 EDS_F_DiagRespData6 "Remote Diagnostic signal Data response";
CM_ SG_ 1563 EDS_F_DiagRespData7 "Diagnostic signal Data response";
CM_ SG_ 1575 RCU_DiagRespData0 "Diagnostic signal Data response";
CM_ SG_ 1575 RCU_DiagRespData1 "Diagnostic signal Data response";
CM_ SG_ 1575 RCU_DiagRespData2 "Diagnostic signal Data response";
CM_ SG_ 1575 RCU_DiagRespData3 "Diagnostic signal Data response";
CM_ SG_ 1575 RCU_DiagRespData4 "Diagnostic signal Data response";
CM_ SG_ 1575 RCU_DiagRespData5 "Diagnostic signal Data response...";
CM_ SG_ 1575 RCU_DiagRespData6 "Diagnostic signal Data response";
CM_ SG_ 1575 RCU_DiagRespData7 "Diagnostic signal Data response...";
CM_ SG_ 1577 IDB_DiagRespData0 "Diagnostic signal Data response";
CM_ SG_ 1577 IDB_DiagRespData1 "Remote Diagnostic signal Data response";
CM_ SG_ 1577 IDB_DiagRespData2 "Remote Diagnostic signal Data response";
CM_ SG_ 1577 IDB_DiagRespData3 "Diagnostic signal Data response";
CM_ SG_ 1577 IDB_DiagRespData4 "Diagnostic signal Data response";
CM_ SG_ 1577 IDB_DiagRespData5 "Remote Diagnostic signal Data response";
CM_ SG_ 1577 IDB_DiagRespData6 "Remote Diagnostic signal Data response";
CM_ SG_ 1577 IDB_DiagRespData7 "Diagnostic signal Data response";
CM_ SG_ 1579 EPS2_DiagRespData0 "Diagnostic signal Data response...";
CM_ SG_ 1579 EPS2_DiagRespData1 "Remote Diagnostic signal Data response";
CM_ SG_ 1579 EPS2_DiagRespData2 "Remote Diagnostic signal Data response";
CM_ SG_ 1579 EPS2_DiagRespData3 "Diagnostic signal Data response";
CM_ SG_ 1579 EPS2_DiagRespData4 "Remote Diagnostic signal Data response";
CM_ SG_ 1579 EPS2_DiagRespData5 "Diagnostic signal Data response";
CM_ SG_ 1579 EPS2_DiagRespData6 "Remote Diagnostic signal Data response";
CM_ SG_ 1579 EPS2_DiagRespData7 "Remote Diagnostic signal Data response";
CM_ SG_ 1580 VCU_DiagRespData0 "Diagnostic signal Data response";
CM_ SG_ 1580 VCU_DiagRespData1 "Diagnostic signal Data response";
CM_ SG_ 1580 VCU_DiagRespData2 "Diagnostic signal Data response";
CM_ SG_ 1580 VCU_DiagRespData3 "Diagnostic signal Data response";
CM_ SG_ 1580 VCU_DiagRespData4 "Remote Diagnostic signal Data response";
CM_ SG_ 1580 VCU_DiagRespData5 "Diagnostic signal Data response";
CM_ SG_ 1580 VCU_DiagRespData6 "Diagnostic signal Data response";
CM_ SG_ 1580 VCU_DiagRespData7 "Remote Diagnostic signal Data response";
CM_ SG_ 1597 POD_DCDC_DiagRespData0 "Diagnostic signal Data response";
CM_ SG_ 1597 POD_DCDC_DiagRespData1 "Diagnostic signal Data response";
CM_ SG_ 1597 POD_DCDC_DiagRespData2 "Remote Diagnostic signal Data response";
CM_ SG_ 1597 POD_DCDC_DiagRespData3 "Remote Diagnostic signal Data response";
CM_ SG_ 1597 POD_DCDC_DiagRespData4 "Diagnostic signal Data response";
CM_ SG_ 1597 POD_DCDC_DiagRespData5 "Diagnostic signal Data response";
CM_ SG_ 1597 POD_DCDC_DiagRespData6 "Remote Diagnostic signal Data response";
CM_ SG_ 1597 POD_DCDC_DiagRespData7 "Diagnostic signal Data response";
CM_ SG_ 1598 POD_OBC_DiagRespData0 "Diagnostic signal Data response";
CM_ SG_ 1598 POD_OBC_DiagRespData1 "Remote Diagnostic signal Data response";
CM_ SG_ 1598 POD_OBC_DiagRespData2 "Diagnostic signal Data response";
CM_ SG_ 1598 POD_OBC_DiagRespData3 "Remote Diagnostic signal Data response";
CM_ SG_ 1598 POD_OBC_DiagRespData4 "Diagnostic signal Data response";
CM_ SG_ 1598 POD_OBC_DiagRespData5 "Remote Diagnostic signal Data response";
CM_ SG_ 1598 POD_OBC_DiagRespData6 "Diagnostic signal Data response";
CM_ SG_ 1598 POD_OBC_DiagRespData7 "Remote Diagnostic signal Data response";
CM_ SG_ 1599 POD_DiagRespData0 "Diagnostic signal Data response";
CM_ SG_ 1599 POD_DiagRespData1 "Diagnostic signal Data response";
CM_ SG_ 1599 POD_DiagRespData2 "Diagnostic signal Data response";
CM_ SG_ 1599 POD_DiagRespData3 "Diagnostic signal Data response";
CM_ SG_ 1599 POD_DiagRespData4 "Diagnostic signal Data response";
CM_ SG_ 1599 POD_DiagRespData5 "Diagnostic signal Data response";
CM_ SG_ 1599 POD_DiagRespData6 "Diagnostic signal Data response";
CM_ SG_ 1599 POD_DiagRespData7 "Diagnostic signal Data response";
CM_ SG_ 1605 POD_GW_Flash_Resp "Response message for Flashing of OBC CPU1";
CM_ SG_ 1680 GS_DiagReqData0 "Diagnostic signal Data request";
CM_ SG_ 1680 GS_DiagReqData1 "Diagnostic signal Data request";
CM_ SG_ 1680 GS_DiagReqData2 "Diagnostic signal Data request";
CM_ SG_ 1680 GS_DiagReqData3 "Diagnostic signal Data request";
CM_ SG_ 1680 GS_DiagReqData4 "Remote Diagnostic signal Data request";
CM_ SG_ 1680 GS_DiagReqData5 "Diagnostic signal Data request";
CM_ SG_ 1680 GS_DiagReqData6 "Diagnostic signal Data request";
CM_ SG_ 1680 GS_DiagReqData7 "Diagnostic signal Data request";
CM_ SG_ 1690 EDS_R_DiagReqData0 "Diagnostic signal Data request";
CM_ SG_ 1690 EDS_R_DiagReqData1 "Remote Diagnostic signal Data request";
CM_ SG_ 1690 EDS_R_DiagReqData2 "Diagnostic signal Data request";
CM_ SG_ 1690 EDS_R_DiagReqData3 "Remote Diagnostic signal Data request";
CM_ SG_ 1690 EDS_R_DiagReqData4 "Remote Diagnostic signal Data request";
CM_ SG_ 1690 EDS_R_DiagReqData5 "Diagnostic signal Data request";
CM_ SG_ 1690 EDS_R_DiagReqData6 "Remote Diagnostic signal Data request";
CM_ SG_ 1690 EDS_R_DiagReqData7 "Diagnostic signal Data request";
CM_ SG_ 1691 EDS_F_DiagReqData0 "Remote Diagnostic signal Data request";
CM_ SG_ 1691 EDS_F_DiagReqData1 "Diagnostic signal Data request";
CM_ SG_ 1691 EDS_F_DiagReqData2 "Remote Diagnostic signal Data request";
CM_ SG_ 1691 EDS_F_DiagReqData3 "Diagnostic signal Data request";
CM_ SG_ 1691 EDS_F_DiagReqData4 "Diagnostic signal Data request";
CM_ SG_ 1691 EDS_F_DiagReqData5 "Diagnostic signal Data request";
CM_ SG_ 1691 EDS_F_DiagReqData6 "Diagnostic signal Data request";
CM_ SG_ 1691 EDS_F_DiagReqData7 "Diagnostic signal Data request";
CM_ SG_ 1703 RCU_DiagReqData0 "Diagnostic signal Data request";
CM_ SG_ 1703 RCU_DiagReqData1 "Diagnostic signal Data request";
CM_ SG_ 1703 RCU_DiagReqData2 "Diagnostic signal Data request";
CM_ SG_ 1703 RCU_DiagReqData3 "Diagnostic signal Data request";
CM_ SG_ 1703 RCU_DiagReqData4 "Remote Diagnostic signal Data request";
CM_ SG_ 1703 RCU_DiagReqData5 "Diagnostic signal Data request";
CM_ SG_ 1703 RCU_DiagReqData6 "Remote Diagnostic signal Data request";
CM_ SG_ 1703 RCU_DiagReqData7 "Remote Diagnostic signal Data request";
CM_ SG_ 1705 IDB_DiagReqData0 "Diagnostic signal Data request";
CM_ SG_ 1705 IDB_DiagReqData1 "Diagnostic signal Data request";
CM_ SG_ 1705 IDB_DiagReqData2 "Diagnostic signal Data request";
CM_ SG_ 1705 IDB_DiagReqData3 "Diagnostic signal Data request";
CM_ SG_ 1705 IDB_DiagReqData4 "Diagnostic signal Data request";
CM_ SG_ 1705 IDB_DiagReqData5 "Diagnostic signal Data request";
CM_ SG_ 1705 IDB_DiagReqData6 "Remote Diagnostic signal Data request";
CM_ SG_ 1705 IDB_DiagReqData7 "Diagnostic signal Data request";
CM_ SG_ 1707 EPS2_DiagReqData0 "Diagnostic signal Data request";
CM_ SG_ 1707 EPS2_DiagReqData1 "Diagnostic signal Data request";
CM_ SG_ 1707 EPS2_DiagReqData2 "Diagnostic signal Data request";
CM_ SG_ 1707 EPS2_DiagReqData3 "Remote Diagnostic signal Data request";
CM_ SG_ 1707 EPS2_DiagReqData4 "Diagnostic signal Data request";
CM_ SG_ 1707 EPS2_DiagReqData5 "Remote Diagnostic signal Data request";
CM_ SG_ 1707 EPS2_DiagReqData6 "Diagnostic signal Data request";
CM_ SG_ 1707 EPS2_DiagReqData7 "Diagnostic signal Data request";
CM_ SG_ 1708 VCU_DiagReqData0 "Remote Diagnostic signal Data request";
CM_ SG_ 1708 VCU_DiagReqData1 "Diagnostic signal Data request";
CM_ SG_ 1708 VCU_DiagReqData2 "Remote Diagnostic signal Data request";
CM_ SG_ 1708 VCU_DiagReqData3 "Diagnostic signal Data request";
CM_ SG_ 1708 VCU_DiagReqData4 "Diagnostic signal Data request";
CM_ SG_ 1708 VCU_DiagReqData5 "Remote Diagnostic signal Data request";
CM_ SG_ 1708 VCU_DiagReqData6 "Diagnostic signal Data request";
CM_ SG_ 1708 VCU_DiagReqData7 "Remote Diagnostic signal Data request";
CM_ SG_ 1725 POD_DCDC_DiagReqData0 "Diagnostic signal Data request";
CM_ SG_ 1725 POD_DCDC_DiagReqData1 "Diagnostic signal Data request";
CM_ SG_ 1725 POD_DCDC_DiagReqData2 "Remote Diagnostic signal Data request";
CM_ SG_ 1725 POD_DCDC_DiagReqData3 "Diagnostic signal Data request";
CM_ SG_ 1725 POD_DCDC_DiagReqData4 "Remote Diagnostic signal Data request";
CM_ SG_ 1725 POD_DCDC_DiagReqData5 "Remote Diagnostic signal Data request";
CM_ SG_ 1725 POD_DCDC_DiagReqData6 "Diagnostic signal Data request";
CM_ SG_ 1725 POD_DCDC_DiagReqData7 "Diagnostic signal Data request";
CM_ SG_ 1726 POD_OBC_DiagReqData0 "Diagnostic signal Data request";
CM_ SG_ 1726 POD_OBC_DiagReqData1 "Diagnostic signal Data request";
CM_ SG_ 1726 POD_OBC_DiagReqData2 "Diagnostic signal Data request";
CM_ SG_ 1726 POD_OBC_DiagReqData3 "Remote Diagnostic signal Data request";
CM_ SG_ 1726 POD_OBC_DiagReqData4 "Diagnostic signal Data request";
CM_ SG_ 1726 POD_OBC_DiagReqData5 "Diagnostic signal Data request";
CM_ SG_ 1726 POD_OBC_DiagReqData6 "Diagnostic signal Data request";
CM_ SG_ 1726 POD_OBC_DiagReqData7 "Remote Diagnostic signal Data request";
CM_ SG_ 1727 POD_DiagReqData0 "Diagnostic signal Data request";
CM_ SG_ 1727 POD_DiagReqData1 "Diagnostic signal Data request";
CM_ SG_ 1727 POD_DiagReqData2 "Diagnostic signal Data request";
CM_ SG_ 1727 POD_DiagReqData3 "Diagnostic signal Data request";
CM_ SG_ 1727 POD_DiagReqData4 "Diagnostic signal Data request";
CM_ SG_ 1727 POD_DiagReqData5 "Diagnostic signal Data request";
CM_ SG_ 1727 POD_DiagReqData6 "Diagnostic signal Data request";
CM_ SG_ 1727 POD_DiagReqData7 "Diagnostic signal Data request";
CM_ SG_ 1733 POD_GW_Flash_Req "Request message for Flashing of OBC CPU1";
CM_ SG_ 1775 DiagReqAllCANData0 "Diagnostic message Request all CAN";
CM_ SG_ 1775 DiagReqAllCANData1 "Diagnostic message Request all CAN";
CM_ SG_ 1775 DiagReqAllCANData2 "Diagnostic message Request all CAN";
CM_ SG_ 1775 DiagReqAllCANData3 "Diagnostic message Request all CAN";
CM_ SG_ 1775 DiagReqAllCANData4 "Diagnostic message Request all CAN";
CM_ SG_ 1775 DiagReqAllCANData5 "Diagnostic message Request all CAN";
CM_ SG_ 1775 DiagReqAllCANData6 "Diagnostic message Request all CAN";
CM_ SG_ 1775 DiagReqAllCANData7 "Diagnostic message Request all CAN";
CM_ SG_ 1791 DiagReqAllEcuData0 "Diagnostic message all ECUs";
CM_ SG_ 1791 DiagReqAllEcuData1 "Diagnostic message all ECUs";
CM_ SG_ 1791 DiagReqAllEcuData2 "Diagnostic message all ECUs";
CM_ SG_ 1791 DiagReqAllEcuData3 "Diagnostic message all ECUs";
CM_ SG_ 1791 DiagReqAllEcuData4 "Diagnostic message all ECUs";
CM_ SG_ 1791 DiagReqAllEcuData5 "Diagnostic message all ECUs";
CM_ SG_ 1791 DiagReqAllEcuData6 "Diagnostic message all ECUs";
CM_ SG_ 1791 DiagReqAllEcuData7 "Diagnostic message all ECUs";
CM_ SG_ 1793 SEED_CAN_Req1 "byte 0/1 identifier of target ECU...";
CM_ SG_ 1795 SEED_CAN_Req2 "byte 0/1 identifier of target ECU...";
CM_ SG_ 1801 SEED_CAN_Req5 "byte 0/1 identifier of target ECU...";
CM_ SG_ 1803 SEED_CAN_Req6 "byte 0/1 identifier of target ECU
byte 2/3 service request type 270x/670x
byte 4-7 seed key";
CM_ SG_ 1805 SEED_CAN_Req7 "byte 0/1 identifier of target ECU
byte 2/3 service request type 270x/670x
byte 4-7 seed key";
CM_ SG_ 1807 SEED_CAN_Req8 "byte 0/1 identifier of target ECU...";
CM_ SG_ 1808 POD_PDU_Major_App_Version "POD PDU major application version";
CM_ SG_ 1808 POD_PDU_Minor_App_Version "POD PDU minor application version";
CM_ SG_ 1808 POD_PDU_Subminor_App_Version "POD PDU subminor application version";
CM_ SG_ 1809 CRC_POD_Err_Lvl "Checksum";
CM_ SG_ 1809 ALIVE_POD_Err_Lvl "Alive Counter";
CM_ SG_ 1809 DCFC_Err_Lvl "DCFC Error level for fault management";
CM_ SG_ 1809 DCDC_Err_Lvl "DCDC Error level for fault management";
CM_ SG_ 1809 OBC_Err_Lvl "OBC Error level for fault management";
CM_ SG_ 1815 SEED_CAN_Req10 "byte 0/1 identifier of target ECU...";
CM_ SG_ 1843 SEED_CAN_Req18 "byte 0/1 identifier of target ECU...";
CM_ SG_ 1857 SEED_CAN_Req23 "byte 0/1 identifier of target ECU...";
CM_ SG_ 1859 SEED_CAN_Req22 "byte 0/1 identifier of target ECU...";
CM_ SG_ 1862 POD_Boot_Major_Version "Bootloader Major version";
CM_ SG_ 1862 POD_Boot_Minor_Version "Bootloader Minor version";
CM_ SG_ 1862 POD_Boot_Subminor_Version "Bootloader Subminor version";
CM_ SG_ 1862 POD_Boot_Reason "Bootloader bootup reason";
CM_ SG_ 1862 POD_App_valid "Application validation status";
CM_ SG_ 1862 POD_App_Compatibility "Application compatibility status";
CM_ SG_ 1862 POD_Cal_Valid "Calibration validation status";
CM_ SG_ 1862 POD_Cal_Compatibility "Calibration compatibility status";
CM_ SG_ 1863 POD_DCDC_Major_App_Version "POD DCDC major application version";
CM_ SG_ 1863 POD_DCDC_Minor_App_Version "POD DCDC minor application version";
CM_ SG_ 1863 POD_DCDC_Subminor_App_Version "POD DCDC subminor application version";
CM_ SG_ 1864 POD_OBC_C1_Major_App_Version "POD OBC major application version";
CM_ SG_ 1864 POD_OBC_C1_Minor_App_Version "POD OBC minor application version";
CM_ SG_ 1864 POD_OBC_C1_Subminor_App_Version "POD OBC subminor application version";
CM_ SG_ 1864 POD_OBC_C2_Major_App_Version "POD OBC CPU2 major application version";
CM_ SG_ 1864 POD_OBC_C2_Minor_App_Version "POD OBC CPU2 minor application version";
CM_ SG_ 1864 POD_OBC_C2_Subminor_App_Version "POD OBC CPU2 subminor application version";
CM_ SG_ 1864 POD_OBC_Build_Version "POD OBC Build Ver";
CM_ SG_ 1869 POD_DCDC_AppVersion_mia "Status of DCDC App Version msg";
CM_ SG_ 1869 POD_OBC_AppVersion_mia "Status of OBC App Version msg";
CM_ SG_ 1869 POD_DCDC_Status0x326_mia "Status of DCDC Status 0x326";
CM_ SG_ 1869 POD_DCDC_Status0x346_mia "Status of DCDC Status 0x346 ";
CM_ SG_ 1869 POD_DCDC_Thermal0x366_mia "Status of DCDC Thermal 0x366 
";
CM_ SG_ 1869 POD_FC_Status0x327_mia "Status of FC Status 0x327";
CM_ SG_ 1869 POD_OBC_Status0x313_mia "Status of OBC Status 0x313";
CM_ SG_ 1869 POD_OBC_Status0x323_mia "Status of OBC Status 0x323 ";
CM_ SG_ 1869 POD_BMS_Status0x249_mia "Status of BMS";
CM_ SG_ 1869 POD_BOOT_Broadcast_mia "Status of Bootloader Broadcast ";
CM_ SG_ 1869 POD_DCDC_Status0x326_chksum "Status of DCDC Status 0x326 checksum";
CM_ SG_ 1869 POD_DCDC_Status0x346_chksum "Status of DCDC Status 0x346 checksum";
CM_ SG_ 1869 POD_DCDC_Thermal0x366_chksum "Status of DCDC Thermal 0x366 checksum";
CM_ SG_ 1869 POD_FC_Status0x327_chksum "Status of FC Status 0x327 check sum";
CM_ SG_ 1869 POD_OBC_Status0x313_chksum "Status of OBC Status 0x313 check sum";
CM_ SG_ 1869 POD_OBC_Status0x323_chksum "Status of OBC Status 0x323 check sum
";
CM_ SG_ 1869 POD_BMS_Status0x249_chksum "Status of BMS checksum";
CM_ SG_ 1869 POD_BOOT_Broadcast_chksum "Status of Bootloader Broadcast checksum";
CM_ SG_ 1869 POD_OBC_Status0x323_alivecntr "Status of OBC Status 0x323 alivecounter
";
CM_ SG_ 1869 POD_DCDC_Status0x346_alivecntr "Status of DCDC Status 0x346 alive counter";
CM_ SG_ 1869 POD_DCDC_Thermal0x366_alivecntr "Status of DCDC Thermal 0x366 alive counter
";
CM_ SG_ 1869 POD_FC_Status0x327_alivecntr "Status of FC Status 0x327 alive counter
";
CM_ SG_ 1869 POD_OBC_Status0x313_alivecntr "POD_OBC_Status0x313_alivecntr";
CM_ SG_ 1869 POD_DCDC_Status0x326_alivecntr "Status of DCDC Status 0x326 alive counter
";
CM_ SG_ 1869 POD_BMS_Status0x249_alivecntr "Status of BMS status alive counter";
CM_ SG_ 1869 POD_BOOT_Broadcast_alivecntr "Status of Bootloader Broadcast alive counter";
CM_ SG_ 1869 POD_VCU_NM_mia "Status of VCU NM mia";
CM_ SG_ 1869 POD_VCU_ThermalInfoFb_mia "Status of VCU Thermal info Feedback";
CM_ SG_ 1869 POD_VCU_podInfo_mia "Status of VCU POD Info";
CM_ SG_ 1869 POD_BMS_Coolant_mia "Status of BMS coolant";
CM_ SG_ 1869 POD_VCU_NM_chksum "Status of VCU NM chksum";
CM_ SG_ 1869 POD_VCU_ThermalInfoFb_chksum "Status of VCU Thermal info Feedback  checksum";
CM_ SG_ 1869 POD_VCU_podInfo_chksum "Status of VCU POD Info checksum";
CM_ SG_ 1869 POD_BMS_Coolant_chksum "Status of BMS coolant checksum";
CM_ SG_ 1869 POD_VCU_NM_alivecntr "Status of VCU NM alive counter
";
CM_ SG_ 1869 POD_VCU_ThermalInfoFb_alivecntr "Status of VCU Thermal info Feedback alive counter";
CM_ SG_ 1869 POD_VCU_podInfo_alivecntr "Status of VCU POD Info alive counter
";
CM_ SG_ 1869 POD_BMS_Coolant_alivecntr "Status of BMS coolant alive counter";
CM_ SG_ 1870 POD_OBC_evt_gtwMIA "POD GTW MIA";
CM_ SG_ 1870 POD_OBC_evt_fuseOpen "POD_OBC_evt_fuseOpen";
CM_ SG_ 1870 POD_OBC_evt_fLineUFWrn "Line Frequency Under Warning";
CM_ SG_ 1870 POD_OBC_evt_fLineUFFlt "Line Frequency Under Fault";
CM_ SG_ 1870 POD_OBC_evt_fLineOFWrn "Line Frequency Over Warning";
CM_ SG_ 1870 POD_OBC_evt_fLineOFFlt "Line Frequency Over Fault";
CM_ SG_ 1870 POD_OBC_evt_eStopFlt "OBC SW Emergency Stop Fault";
CM_ SG_ 1870 POD_OBC_evt_evsePwrInsufficient "EVSE Power Insufficient";
CM_ SG_ 1870 POD_OBC_evt_vOutUVWrn "Output Undervoltage Warning";
CM_ SG_ 1870 POD_OBC_evt_vOutUVFlt "Output Undervoltage Fault";
CM_ SG_ 1870 POD_OBC_evt_vOutOVWrn "Output Overvoltage Warning";
CM_ SG_ 1870 POD_OBC_evt_vOutOVFlt "Output Overvoltage Fault";
CM_ SG_ 1870 POD_OBC_evt_psfbErr "PSFB Error";
CM_ SG_ 1870 POD_OBC_evt_rsvd1 "Reserved POD OBC Event";
CM_ SG_ 1870 POD_OBC_evt_hwIDInvalid "OBC HW ID Invalid";
CM_ SG_ 1870 POD_OBC_evt_hwFlt "OBC HW Fault";
CM_ SG_ 1870 POD_OBC_evt_vLineImbalWrn "Line Voltage Imbalance Warning";
CM_ SG_ 1870 POD_OBC_evt_vLineImbalFlt "Line Voltage Imbalance Fault";
CM_ SG_ 1870 POD_OBC_evt_vDCLinkPchgFail "DC Link Precharge Failure";
CM_ SG_ 1870 POD_OBC_evt_vDCLinkOVWrn "DC Link Overvoltage Warning";
CM_ SG_ 1870 POD_OBC_evt_vDCLinkOVFlt "DC Link Overvoltage Fault";
CM_ SG_ 1870 POD_OBC_evt_rsvd2 "Reserved POD OBC Event";
CM_ SG_ 1870 POD_OBC_evt_rsvd3 "Reserved POD OBC Event";
CM_ SG_ 1870 POD_OBC_evt_vcuMIA "VCU MIA";
CM_ SG_ 1870 POD_OBC_evt_vPhaseDetectFail "Phase Detect Failure";
CM_ SG_ 1870 POD_OBC_evt_vLineUVWrn "Line Undervoltage Warning";
CM_ SG_ 1870 POD_OBC_evt_vLineUVFlt "Line Undervoltage Fault";
CM_ SG_ 1870 POD_OBC_evt_vLineOVWrn "Line Overvoltage Warning";
CM_ SG_ 1870 POD_OBC_evt_vLineOVFlt "Line Overvoltage Fault";
CM_ SG_ 1870 POD_OBC_evt_rsvd4 "Reserved POD OBC Event";
CM_ SG_ 1870 POD_OBC_evt_rsvd5 "Reserved POD OBC Event";
CM_ SG_ 1870 POD_OBC_evt_vLineInterrupted "Line Connection Interrupted ";
CM_ SG_ 1870 POD_OBC_evt_iLineImbalFlt "Line Current Imbalance Fault";
CM_ SG_ 1870 POD_OBC_evt_iLineOCWrn "Line Over Current Warning";
CM_ SG_ 1870 POD_OBC_evt_iLineOCFlt "Line Over Current Fault";
CM_ SG_ 1870 POD_OBC_evt_tSensorFail "Temperature Sensor Fail";
CM_ SG_ 1870 POD_OBC_evt_fLineDetWrn "Line Frequency Detect Warning";
CM_ SG_ 1870 POD_OBC_evt_fLineDetFlt "Line Frequency Detect Fault";
CM_ SG_ 1870 POD_OBC_evt_tChargerBoardOTWrn "Charger Board Over Temperature Warning";
CM_ SG_ 1870 POD_OBC_evt_tChargerBoardOTFlt "Charger Board Over Temperature Fault";
CM_ SG_ 1870 POD_OBC_evt_iOutNegOCFlt "Output Negative Over Current Fault";
CM_ SG_ 1870 POD_OBC_evt_iOutOCWrn "Output Over Current Warning";
CM_ SG_ 1870 POD_OBC_evt_iOutOCFlt "Output Over Current Fault";
CM_ SG_ 1870 POD_OBC_evt_isoPwrFail "ISO Power Fail";
CM_ SG_ 1870 POD_OBC_evt_swMismatch "SW Configuration Mismatch (Flashed SW != Build Config)";
CM_ SG_ 1870 POD_OBC_evt_vDCLinkUVWrn "DC Link Undervoltage Warning";
CM_ SG_ 1870 POD_OBC_evt_vDCLinkUVFlt "DC Link Undervoltage Fault";
CM_ SG_ 1870 POD_OBC_evt_iLineImbalWrn "Line Current Imbalance Warning";
CM_ SG_ 1870 POD_OBC_evt_PfcStartFault "PFC Start Fault";
CM_ SG_ 1870 POD_OBC_evt_iOutSensorErr "Output Current Sensor Error";
CM_ SG_ 1870 POD_OBC_evt_iLine4SensorErr "Line4 Current Sensor Error";
CM_ SG_ 1870 POD_OBC_evt_iLine3SensorErr "Line3 Current Sensor Error";
CM_ SG_ 1870 POD_OBC_evt_iLine2SensorErr "Line2 Current Sensor Error";
CM_ SG_ 1870 POD_OBC_evt_iLine1SensorErr "Line1 Current Sensor Error";
CM_ SG_ 1870 POD_OBC_evt_tColdPlateOTWrn "Cold Plate Over Temperature Warning";
CM_ SG_ 1870 POD_OBC_evt_tColdPlateOTFlt "Cold Plate Over Temperature Fault";
CM_ SG_ 1870 POD_OBC_evt_tChargeBoardUTWrn "Charge board under temperature warning";
CM_ SG_ 1870 POD_OBC_evt_tChargeBoardUTFault "Charge board under temperature fault";
CM_ SG_ 1870 POD_OBC_evt_tColdPlateUTWrn "Cold Plate under temperature warning";
CM_ SG_ 1870 POD_OBC_evt_tColdPlateUTFault "Cold Plate under temperature fault";
CM_ SG_ 1870 POD_OBC_evt_rsvd6 "Reserved POD OBC Event";
CM_ SG_ 1870 POD_OBC_evt_rsvd7 "Reserved POD OBC Event";
CM_ SG_ 1870 POD_OBC_evt_rsvd8 "Reserved POD OBC Event";
CM_ SG_ 1870 POD_OBC_evt_DualCoreOprtFault "Dual core operation fault";
CM_ SG_ 1871 POD_DCDC_evt_VCU_mia "EID_VCU_MIA";
CM_ SG_ 1871 POD_DCDC_evt_GTW_mia "EID_GTW_MIA";
CM_ SG_ 1871 POD_DCDC_Evt_Power_mismatch "EID_POWER_MISMATCH";
CM_ SG_ 1871 POD_DCDC_evt_HV_Volt_Abnormal " HV Voltage out of normal range 270V ÷ 465V";
CM_ SG_ 1871 POD_DCDC_evt_LV_Volt_Abnormal " LV Voltage out of normal range 9V ÷ 16V";
CM_ SG_ 1871 POD_DCDC_evt_HV_Volt_OFF_Range "HV Voltage > 475V OR < 260V";
CM_ SG_ 1871 POD_DCDC_evt_fetTempHigh "Over Mosfet Temperature";
CM_ SG_ 1871 POD_DCDC_evt_fetTempLow "Under Mosfet Temperature";
CM_ SG_ 1871 POD_DCDC_evt_ColdplateTempHigh "Over Coldplate Temperature";
CM_ SG_ 1871 POD_DCDC_evt_ColdplateTempLow "Under Coldplate Temperature";
CM_ SG_ 1871 POD_DCDC_evt_Busbar_POS_TempHigh "Over Bus Bar Positive Temperature";
CM_ SG_ 1871 POD_DCDC_evt_Busbar_NEG_TempHigh "Over Bus Bar Negative Temperature";
CM_ SG_ 1871 POD_DCDC_evt_NTC_fail_fet "Mosfet Temperature Failure";
CM_ SG_ 1871 POD_DCDC_evt_NTC_Fail_BB_P "Bus Bar Positive Temperature Failure
";
CM_ SG_ 1871 POD_DCDC_evt_NTC_Fail_BB_N "Bus Bar Negative Temperature Failure";
CM_ SG_ 1871 POD_DCDC_evt_vin_sensor_fail "Vin Sensor Fail";
CM_ SG_ 1871 POD_DCDC_evt_HV_IHigh "Over HV Input Current protection by SW Level 1";
CM_ SG_ 1871 POD_DCDC_evt_HV_VHigh "Over HV Input Voltage protection by SW Level 1";
CM_ SG_ 1871 POD_DCDC_evt_HV_VLow "Under HV Input Voltage protection by SW Level 1";
CM_ SG_ 1871 POD_DCDC_evt_LV_IHigh "Over LV Output Current protection by SW Level 1";
CM_ SG_ 1871 POD_DCDC_evt_LV_VHigh "Over LV Output Voltage protection by SW Level 1";
CM_ SG_ 1871 POD_DCDC_evt_LV_VLow "Under LV Output Voltage protection by SW Level 1";
CM_ SG_ 1871 POD_DCDC_evt_LV_Shortcircuit "Short Circuit protection by SW Level 1";
CM_ SG_ 1871 POD_DCDC_evt_EEPROM_Failure "Eeprom failure";
CM_ SG_ 1871 POD_DCDC_evt_Error_Comm "Communication Error";
CM_ SG_ 1871 POD_DCDC_evt_Cont_welded "Contactor WELDED";
CM_ SG_ 1871 POD_DCDC_evt_Cont_Stuck_open "Contactor is stucked in OPEN state";
CM_ SG_ 1871 POD_DCDC_evt_Reverse_I_Protect "Reverse Current Protection";
CM_ SG_ 1871 POD_DCDC_evt_HWTrip_avg_HVCurr "Protect Over Average HV Current by HW (HW Tripzone)";
CM_ SG_ 1871 POD_DCDC_evt_HWTrip_pri_Current "Protect Over Primary Current by SW (SW Tripzone)";
CM_ SG_ 1871 POD_DCDC_evt_HWTrip_LV_Voltage "Protect Over LV Voltage by HW (HW Tripzone)";
CM_ SG_ 1871 POD_DCDC_evt_SWTrip_HV_Ovp "Over HV Input Voltage protection by SW Level 2 (SW Tripzone)";
CM_ SG_ 1871 POD_DCDC_evt_SWTrip_LV_Ovp "Over LV  Output Voltage protection by SW Level 2 (SW Tripzone)";
CM_ SG_ 1871 POD_DCDC_evt_SWTrip_LV_Ocp "Over LV Output Current protection by SW Level 2 (SW Tripzone)";
CM_ SG_ 1873 VCU_DebugDiag2 "VCU Acm component error level";
CM_ SG_ 1873 VCU_DebugDiag1 "VCU xGW component error level";
CM_ SG_ 1873 VCU_DebugDiag5 "VCU Regen brake component error level";
CM_ SG_ 1873 VCU_DebugDiag4 "VCU Idb component error level";
CM_ SG_ 1873 VCU_DebugDiag3 "VCU Brake component error level";
CM_ SG_ 1873 VCU_DebugDiag8 "VCU Ags component error level";
CM_ SG_ 1873 VCU_DebugDiag7 "VCU Lvd component error level";
CM_ SG_ 1873 VCU_DebugDiag6 "VCU Eds component error level";
CM_ SG_ 1873 VCU_DebugDiag10 "VCU Fan component error level";
CM_ SG_ 1873 VCU_DebugDiag9 "VCU Ptc component error level";
CM_ SG_ 1873 VCU_DebugDiag13 "VCU Valve component error level";
CM_ SG_ 1873 VCU_DebugDiag12 "VCU Tsen component error level";
CM_ SG_ 1873 VCU_DebugDiag11 "VCU Hvac component error level";
CM_ SG_ 1873 VCU_DebugDiag16 "VCU Bms component error level";
CM_ SG_ 1873 VCU_DebugDiag15 "VCU Vehicle speed component error level";
CM_ SG_ 1873 VCU_DebugDiag14 "VCU Water pump component error level";
CM_ SG_ 1873 VCU_DebugDiag18 "VCU Accelerator pedal component error level";
CM_ SG_ 1873 VCU_DebugDiag17 "VCU Obc component error level";
CM_ SG_ 1873 VCU_DebugDiag20 "VCU Dcdc component error level";
CM_ SG_ 1873 VCU_DebugDiag19 "VCU charging component errror level";
CM_ SG_ 1963 EPS2_XCP_CCPRespData0 "XCP_CCP Data response";
CM_ SG_ 1963 EPS2_XCP_CCPRespData1 "XCP_CCP Data response";
CM_ SG_ 1963 EPS2_XCP_CCPRespData2 "XCP_CCP Data response";
CM_ SG_ 1963 EPS2_XCP_CCPRespData3 "XCP_CCP Data response";
CM_ SG_ 1963 EPS2_XCP_CCPRespData4 "XCP_CCP Data response";
CM_ SG_ 1963 EPS2_XCP_CCPRespData5 "XCP_CCP Data response";
CM_ SG_ 1963 EPS2_XCP_CCPRespData6 "XCP_CCP Data response";
CM_ SG_ 1963 EPS2_XCP_CCPRespData7 "XCP_CCP Data response";
CM_ SG_ 2010 EPS2_XCP_CCPReqData0 "XCP_CCP Data request";
CM_ SG_ 2010 EPS2_XCP_CCPReqData1 "XCP_CCP Data request";
CM_ SG_ 2010 EPS2_XCP_CCPReqData2 "XCP_CCP Data request";
CM_ SG_ 2010 EPS2_XCP_CCPReqData3 "XCP_CCP Data request";
CM_ SG_ 2010 EPS2_XCP_CCPReqData4 "XCP_CCP Data request";
CM_ SG_ 2010 EPS2_XCP_CCPReqData5 "XCP_CCP Data request";
CM_ SG_ 2010 EPS2_XCP_CCPReqData6 "XCP_CCP Data request";
CM_ SG_ 2010 EPS2_XCP_CCPReqData7 "XCP_CCP Data request";
CM_ SG_ 2015 Diag_Request_ECU_Data0 "Diagnostic message all ECUs";
CM_ SG_ 2015 Diag_Request_ECU_Data1 "Diagnostic message all ECUs";
CM_ SG_ 2015 Diag_Request_ECU_Data2 "Diagnostic message all ECUs";
CM_ SG_ 2015 Diag_Request_ECU_Data3 "Diagnostic message all ECUs";
CM_ SG_ 2015 Diag_Request_ECU_Data4 "Diagnostic message all ECUs";
CM_ SG_ 2015 Diag_Request_ECU_Data5 "Diagnostic message all ECUs";
CM_ SG_ 2015 Diag_Request_ECU_Data6 "Diagnostic message all ECUs";
CM_ SG_ 2015 Diag_Request_ECU_Data7 "Diagnostic message all ECUs";

BA_DEF_ BO_  "GenMsgSendType" ENUM "Cyclic","NotUsed","NotUsed","NotUsed","NotUsed","NotUsed","NotUsed","IfActive","NoMsgSendType","NotUsed";
BA_DEF_ BO_  "GenMsgILSupport" ENUM "No","Yes";
BA_DEF_ BO_  "DiagResponse" ENUM "No","Yes";
BA_DEF_ BO_  "DiagRequest" ENUM "No","Yes";
BA_DEF_ BO_  "NmAsrMessage" ENUM "No","Yes";
BA_DEF_ BO_  "DiagState" ENUM "No","Yes";
BA_DEF_ BO_  "DiagUudtResponse" ENUM "False","True";
BA_DEF_ BO_  "GenMsgStartDelayTime" INT 0 65535;
BA_DEF_ BO_  "GenMsgDelayTime" INT 0 0;
BA_DEF_ BO_  "GenMsgNrOfRepetition" INT 0 0;
BA_DEF_ BO_  "GenMsgCycleTimeFast" INT 0 0;
BA_DEF_ BO_  "GenMsgCycleTime" INT 0 0;
BA_DEF_ SG_  "GenSigSendType" ENUM "Cyclic","OnWrite","OnWriteWithRepetition","OnChange","OnChangeWithRepetition","IfActive","IfActiveWithRepetition","NoSigSendType","NotUsed","NotUsed","NotUsed","NotUsed","NotUsed";
BA_DEF_ SG_  "InvalidValue" STRING;
BA_DEF_ SG_  "GenSigStartValue" INT 0 0;
BA_DEF_ SG_  "GenSigTimeoutTime_ALL" INT 0 65535;
BA_DEF_DEF_  "DiagRequest" "No";
BA_DEF_DEF_  "DiagResponse" "No";
BA_DEF_DEF_  "DiagState" "No";
BA_DEF_DEF_  "DiagUudtResponse" "False";
BA_DEF_DEF_  "GenMsgCycleTime" 0;
BA_DEF_DEF_  "GenMsgCycleTimeFast" 0;
BA_DEF_DEF_  "GenMsgDelayTime" 0;
BA_DEF_DEF_  "GenMsgILSupport" "Yes";
BA_DEF_DEF_  "GenMsgNrOfRepetition" 0;
BA_DEF_DEF_  "GenMsgSendType" "NoMsgSendType";
BA_DEF_DEF_  "GenMsgStartDelayTime" 0;
BA_DEF_DEF_  "GenSigSendType" "Cyclic";
BA_DEF_DEF_  "GenSigStartValue" 0;
BA_DEF_DEF_  "GenSigTimeoutTime_ALL" 0;
BA_DEF_DEF_  "NmAsrMessage" "No";
BA_ "GenMsgCycleTime" BO_ 1168 1000;
BA_ "GenMsgCycleTimeFast" BO_ 1168 100;
BA_ "GenMsgNrOfRepetition" BO_ 1168 2;
BA_ "GenMsgSendType" BO_ 1168 0;
BA_ "GenMsgCycleTime" BO_ 1178 1000;
BA_ "GenMsgCycleTimeFast" BO_ 1178 100;
BA_ "GenMsgNrOfRepetition" BO_ 1178 2;
BA_ "GenMsgSendType" BO_ 1178 0;
BA_ "GenMsgCycleTime" BO_ 1179 1000;
BA_ "GenMsgCycleTimeFast" BO_ 1179 100;
BA_ "GenMsgNrOfRepetition" BO_ 1179 2;
BA_ "GenMsgSendType" BO_ 1179 0;
BA_ "GenMsgCycleTime" BO_ 1195 1000;
BA_ "GenMsgCycleTimeFast" BO_ 1195 100;
BA_ "GenMsgNrOfRepetition" BO_ 1195 2;
BA_ "GenMsgSendType" BO_ 1195 0;
BA_ "GenMsgCycleTime" BO_ 1196 1000;
BA_ "GenMsgCycleTimeFast" BO_ 1196 100;
BA_ "GenMsgNrOfRepetition" BO_ 1196 2;
BA_ "GenMsgSendType" BO_ 1196 0;
BA_ "GenMsgCycleTime" BO_ 1213 1000;
BA_ "GenMsgCycleTimeFast" BO_ 1213 100;
BA_ "GenMsgNrOfRepetition" BO_ 1213 2;
BA_ "GenMsgSendType" BO_ 1213 0;
BA_ "GenMsgCycleTime" BO_ 1282 640;
BA_ "GenMsgSendType" BO_ 1282 0;
BA_ "NmAsrMessage" BO_ 1282 1;
BA_ "GenMsgCycleTime" BO_ 1306 640;
BA_ "GenMsgSendType" BO_ 1306 0;
BA_ "NmAsrMessage" BO_ 1306 1;
BA_ "GenMsgCycleTime" BO_ 1307 640;
BA_ "GenMsgSendType" BO_ 1307 0;
BA_ "NmAsrMessage" BO_ 1307 1;
BA_ "GenMsgCycleTime" BO_ 1324 640;
BA_ "GenMsgSendType" BO_ 1324 0;
BA_ "NmAsrMessage" BO_ 1324 1;
BA_ "GenMsgCycleTime" BO_ 1344 640;
BA_ "GenMsgSendType" BO_ 1344 0;
BA_ "NmAsrMessage" BO_ 1344 1;
BA_ "DiagResponse" BO_ 1552 1;
BA_ "DiagResponse" BO_ 1562 1;
BA_ "DiagResponse" BO_ 1563 1;
BA_ "DiagResponse" BO_ 1575 1;
BA_ "GenMsgILSupport" BO_ 1575 0;
BA_ "DiagResponse" BO_ 1577 1;
BA_ "DiagResponse" BO_ 1579 1;
BA_ "GenMsgILSupport" BO_ 1579 0;
BA_ "DiagResponse" BO_ 1580 1;
BA_ "DiagResponse" BO_ 1597 1;
BA_ "DiagResponse" BO_ 1598 1;
BA_ "DiagResponse" BO_ 1599 1;
BA_ "DiagResponse" BO_ 1605 1;
BA_ "DiagRequest" BO_ 1680 1;
BA_ "DiagRequest" BO_ 1690 1;
BA_ "DiagRequest" BO_ 1691 1;
BA_ "DiagRequest" BO_ 1703 1;
BA_ "DiagRequest" BO_ 1705 1;
BA_ "DiagRequest" BO_ 1707 1;
BA_ "GenMsgILSupport" BO_ 1707 0;
BA_ "DiagRequest" BO_ 1708 1;
BA_ "DiagRequest" BO_ 1725 1;
BA_ "DiagRequest" BO_ 1726 1;
BA_ "DiagRequest" BO_ 1727 1;
BA_ "DiagRequest" BO_ 1733 1;
BA_ "DiagRequest" BO_ 1775 1;
BA_ "DiagRequest" BO_ 1791 1;
BA_ "GenMsgCycleTime" BO_ 1808 1000;
BA_ "GenMsgSendType" BO_ 1808 0;
BA_ "GenMsgCycleTime" BO_ 1809 1000;
BA_ "GenMsgSendType" BO_ 1809 0;
BA_ "DiagResponse" BO_ 1862 1;
BA_ "DiagResponse" BO_ 1863 1;
BA_ "GenMsgCycleTime" BO_ 1863 1000;
BA_ "GenMsgSendType" BO_ 1863 0;
BA_ "DiagResponse" BO_ 1864 1;
BA_ "GenMsgCycleTime" BO_ 1864 1000;
BA_ "GenMsgSendType" BO_ 1864 0;
BA_ "GenMsgCycleTime" BO_ 1868 100;
BA_ "GenMsgSendType" BO_ 1868 0;
BA_ "GenMsgCycleTime" BO_ 1869 100;
BA_ "GenMsgSendType" BO_ 1869 0;
BA_ "GenMsgCycleTime" BO_ 1870 100;
BA_ "GenMsgSendType" BO_ 1870 0;
BA_ "GenMsgCycleTime" BO_ 1871 100;
BA_ "GenMsgSendType" BO_ 1871 0;
BA_ "GenMsgCycleTime" BO_ 1873 100;
BA_ "GenMsgSendType" BO_ 1873 0;
BA_ "DiagResponse" BO_ 1963 1;
BA_ "GenMsgILSupport" BO_ 1963 0;
BA_ "DiagRequest" BO_ 2010 1;
BA_ "GenMsgILSupport" BO_ 2010 0;
BA_ "DiagRequest" BO_ 2015 1;
BA_ "GenSigSendType" SG_ 1110 OP_WISW_SZL_LIN 3;
BA_ "InvalidValue" SG_ 1110 OP_WISW_SZL_LIN "";
BA_ "GenSigSendType" SG_ 1110 COMM_ERR_SZL_LIN 3;
BA_ "InvalidValue" SG_ 1110 COMM_ERR_SZL_LIN "";
BA_ "GenSigSendType" SG_ 1110 BCM_Wiper_Front_Status 3;
BA_ "InvalidValue" SG_ 1110 BCM_Wiper_Front_Status "";
BA_ "GenSigSendType" SG_ 1110 OP_WIPO_SZL_LIN 3;
BA_ "InvalidValue" SG_ 1110 OP_WIPO_SZL_LIN "";
BA_ "GenSigSendType" SG_ 1110 OP_COLS_SZL_LIN 3;
BA_ "InvalidValue" SG_ 1110 OP_COLS_SZL_LIN "";
BA_ "GenSigSendType" SG_ 1110 NOD_ERR_SZL_LIN 3;
BA_ "InvalidValue" SG_ 1110 NOD_ERR_SZL_LIN "";
BA_ "GenSigSendType" SG_ 1110 BCM_Wiper_Rear_Status 3;
BA_ "InvalidValue" SG_ 1110 BCM_Wiper_Rear_Status "3h";
BA_ "GenSigSendType" SG_ 1110 ALIV_WISW_SZL_LIN 3;
BA_ "InvalidValue" SG_ 1110 ALIV_WISW_SZL_LIN "Fh";
BA_ "GenSigSendType" SG_ 1168 CHSKM_GS_WarnMsg 3;
BA_ "GenSigTimeoutTime_ALL" SG_ 1168 CHSKM_GS_WarnMsg 5000;
BA_ "InvalidValue" SG_ 1168 CHSKM_GS_WarnMsg "";
BA_ "GenSigSendType" SG_ 1168 ALV_GS_WarnMsg 3;
BA_ "GenSigTimeoutTime_ALL" SG_ 1168 ALV_GS_WarnMsg 5000;
BA_ "InvalidValue" SG_ 1168 ALV_GS_WarnMsg "Fh";
BA_ "GenSigSendType" SG_ 1168 GS_Warning_Flag_1 4;
BA_ "GenSigTimeoutTime_ALL" SG_ 1168 GS_Warning_Flag_1 5000;
BA_ "InvalidValue" SG_ 1168 GS_Warning_Flag_1 "";
BA_ "GenSigSendType" SG_ 1168 GS_Warning_Flag_2 4;
BA_ "GenSigTimeoutTime_ALL" SG_ 1168 GS_Warning_Flag_2 5000;
BA_ "InvalidValue" SG_ 1168 GS_Warning_Flag_2 "";
BA_ "GenSigSendType" SG_ 1168 GS_Warning_Flag_3 4;
BA_ "GenSigTimeoutTime_ALL" SG_ 1168 GS_Warning_Flag_3 5000;
BA_ "InvalidValue" SG_ 1168 GS_Warning_Flag_3 "";
BA_ "GenSigSendType" SG_ 1168 GS_Warning_Flag_4 4;
BA_ "GenSigTimeoutTime_ALL" SG_ 1168 GS_Warning_Flag_4 5000;
BA_ "InvalidValue" SG_ 1168 GS_Warning_Flag_4 "";
BA_ "GenSigSendType" SG_ 1168 GS_Warning_Flag_5 4;
BA_ "GenSigTimeoutTime_ALL" SG_ 1168 GS_Warning_Flag_5 5000;
BA_ "InvalidValue" SG_ 1168 GS_Warning_Flag_5 "";
BA_ "GenSigSendType" SG_ 1168 GS_Warning_Flag_6 4;
BA_ "GenSigTimeoutTime_ALL" SG_ 1168 GS_Warning_Flag_6 5000;
BA_ "InvalidValue" SG_ 1168 GS_Warning_Flag_6 "";
BA_ "GenSigSendType" SG_ 1168 GS_Warning_Flag_7 4;
BA_ "GenSigTimeoutTime_ALL" SG_ 1168 GS_Warning_Flag_7 5000;
BA_ "InvalidValue" SG_ 1168 GS_Warning_Flag_7 "";
BA_ "GenSigSendType" SG_ 1168 GS_Warning_Flag_8 4;
BA_ "GenSigTimeoutTime_ALL" SG_ 1168 GS_Warning_Flag_8 5000;
BA_ "InvalidValue" SG_ 1168 GS_Warning_Flag_8 "";
BA_ "GenSigSendType" SG_ 1168 GS_Warning_Flag_9 4;
BA_ "GenSigTimeoutTime_ALL" SG_ 1168 GS_Warning_Flag_9 5000;
BA_ "InvalidValue" SG_ 1168 GS_Warning_Flag_9 "";
BA_ "GenSigSendType" SG_ 1168 GS_Warning_Flag_10 4;
BA_ "GenSigTimeoutTime_ALL" SG_ 1168 GS_Warning_Flag_10 5000;
BA_ "InvalidValue" SG_ 1168 GS_Warning_Flag_10 "";
BA_ "GenSigSendType" SG_ 1168 GS_Warning_Flag_11 4;
BA_ "GenSigTimeoutTime_ALL" SG_ 1168 GS_Warning_Flag_11 5000;
BA_ "InvalidValue" SG_ 1168 GS_Warning_Flag_11 "";
BA_ "GenSigSendType" SG_ 1168 GS_Warning_Flag_12 4;
BA_ "GenSigTimeoutTime_ALL" SG_ 1168 GS_Warning_Flag_12 5000;
BA_ "InvalidValue" SG_ 1168 GS_Warning_Flag_12 "";
BA_ "GenSigSendType" SG_ 1168 GS_Reserved_signal1 4;
BA_ "GenSigTimeoutTime_ALL" SG_ 1168 GS_Reserved_signal1 5000;
BA_ "InvalidValue" SG_ 1168 GS_Reserved_signal1 "";
BA_ "GenSigSendType" SG_ 1168 GS_Reserved_signal2 4;
BA_ "GenSigTimeoutTime_ALL" SG_ 1168 GS_Reserved_signal2 5000;
BA_ "InvalidValue" SG_ 1168 GS_Reserved_signal2 "";
BA_ "GenSigSendType" SG_ 1168 GS_Reserved_signal3 4;
BA_ "GenSigTimeoutTime_ALL" SG_ 1168 GS_Reserved_signal3 5000;
BA_ "InvalidValue" SG_ 1168 GS_Reserved_signal3 "";
BA_ "GenSigSendType" SG_ 1168 GS_Reserved_signal4 4;
BA_ "GenSigTimeoutTime_ALL" SG_ 1168 GS_Reserved_signal4 5000;
BA_ "InvalidValue" SG_ 1168 GS_Reserved_signal4 "";
BA_ "GenSigSendType" SG_ 1168 GS_Reserved_signal5 4;
BA_ "GenSigTimeoutTime_ALL" SG_ 1168 GS_Reserved_signal5 5000;
BA_ "InvalidValue" SG_ 1168 GS_Reserved_signal5 "";
BA_ "GenSigSendType" SG_ 1178 CHSKM_EDS_R_WarnMsg 3;
BA_ "GenSigTimeoutTime_ALL" SG_ 1178 CHSKM_EDS_R_WarnMsg 5000;
BA_ "InvalidValue" SG_ 1178 CHSKM_EDS_R_WarnMsg "";
BA_ "GenSigSendType" SG_ 1178 ALV_EDS_R_WarnMsg 3;
BA_ "GenSigTimeoutTime_ALL" SG_ 1178 ALV_EDS_R_WarnMsg 5000;
BA_ "InvalidValue" SG_ 1178 ALV_EDS_R_WarnMsg "Fh";
BA_ "GenSigSendType" SG_ 1178 EDS_R_Warning_Flag_1 4;
BA_ "GenSigTimeoutTime_ALL" SG_ 1178 EDS_R_Warning_Flag_1 5000;
BA_ "InvalidValue" SG_ 1178 EDS_R_Warning_Flag_1 "";
BA_ "GenSigSendType" SG_ 1178 EDS_R_Warning_Flag_2 4;
BA_ "GenSigTimeoutTime_ALL" SG_ 1178 EDS_R_Warning_Flag_2 5000;
BA_ "InvalidValue" SG_ 1178 EDS_R_Warning_Flag_2 "";
BA_ "GenSigSendType" SG_ 1178 EDS_R_Warning_Flag_3 4;
BA_ "GenSigTimeoutTime_ALL" SG_ 1178 EDS_R_Warning_Flag_3 5000;
BA_ "InvalidValue" SG_ 1178 EDS_R_Warning_Flag_3 "";
BA_ "GenSigSendType" SG_ 1178 EDS_R_Warning_Flag_4 4;
BA_ "GenSigTimeoutTime_ALL" SG_ 1178 EDS_R_Warning_Flag_4 5000;
BA_ "InvalidValue" SG_ 1178 EDS_R_Warning_Flag_4 "";
BA_ "GenSigSendType" SG_ 1178 EDS_R_Warning_Flag_5 4;
BA_ "GenSigTimeoutTime_ALL" SG_ 1178 EDS_R_Warning_Flag_5 5000;
BA_ "InvalidValue" SG_ 1178 EDS_R_Warning_Flag_5 "";
BA_ "GenSigSendType" SG_ 1178 EDS_R_Warning_Flag_6 4;
BA_ "GenSigTimeoutTime_ALL" SG_ 1178 EDS_R_Warning_Flag_6 5000;
BA_ "InvalidValue" SG_ 1178 EDS_R_Warning_Flag_6 "";
BA_ "GenSigSendType" SG_ 1178 EDS_R_Warning_Flag_7 4;
BA_ "GenSigTimeoutTime_ALL" SG_ 1178 EDS_R_Warning_Flag_7 5000;
BA_ "InvalidValue" SG_ 1178 EDS_R_Warning_Flag_7 "";
BA_ "GenSigSendType" SG_ 1178 EDS_R_Warning_Flag_8 4;
BA_ "GenSigTimeoutTime_ALL" SG_ 1178 EDS_R_Warning_Flag_8 5000;
BA_ "InvalidValue" SG_ 1178 EDS_R_Warning_Flag_8 "";
BA_ "GenSigSendType" SG_ 1178 EDS_R_Warning_Flag_9 4;
BA_ "GenSigTimeoutTime_ALL" SG_ 1178 EDS_R_Warning_Flag_9 5000;
BA_ "InvalidValue" SG_ 1178 EDS_R_Warning_Flag_9 "";
BA_ "GenSigSendType" SG_ 1178 EDS_R_Warning_Flag_10 4;
BA_ "GenSigTimeoutTime_ALL" SG_ 1178 EDS_R_Warning_Flag_10 5000;
BA_ "InvalidValue" SG_ 1178 EDS_R_Warning_Flag_10 "";
BA_ "GenSigSendType" SG_ 1178 EDS_R_Warning_Flag_11 4;
BA_ "GenSigTimeoutTime_ALL" SG_ 1178 EDS_R_Warning_Flag_11 5000;
BA_ "InvalidValue" SG_ 1178 EDS_R_Warning_Flag_11 "";
BA_ "GenSigSendType" SG_ 1178 EDS_R_Warning_Flag_12 4;
BA_ "GenSigTimeoutTime_ALL" SG_ 1178 EDS_R_Warning_Flag_12 5000;
BA_ "InvalidValue" SG_ 1178 EDS_R_Warning_Flag_12 "";
BA_ "GenSigSendType" SG_ 1178 EDS_R_Reserved_signal1 4;
BA_ "GenSigTimeoutTime_ALL" SG_ 1178 EDS_R_Reserved_signal1 5000;
BA_ "InvalidValue" SG_ 1178 EDS_R_Reserved_signal1 "";
BA_ "GenSigSendType" SG_ 1178 EDS_R_Reserved_signal2 4;
BA_ "GenSigTimeoutTime_ALL" SG_ 1178 EDS_R_Reserved_signal2 5000;
BA_ "InvalidValue" SG_ 1178 EDS_R_Reserved_signal2 "";
BA_ "GenSigSendType" SG_ 1178 EDS_R_Reserved_signal3 4;
BA_ "GenSigTimeoutTime_ALL" SG_ 1178 EDS_R_Reserved_signal3 5000;
BA_ "InvalidValue" SG_ 1178 EDS_R_Reserved_signal3 "";
BA_ "GenSigSendType" SG_ 1178 EDS_R_Reserved_signal4 4;
BA_ "GenSigTimeoutTime_ALL" SG_ 1178 EDS_R_Reserved_signal4 5000;
BA_ "InvalidValue" SG_ 1178 EDS_R_Reserved_signal4 "";
BA_ "GenSigSendType" SG_ 1178 EDS_R_Reserved_signal5 4;
BA_ "GenSigTimeoutTime_ALL" SG_ 1178 EDS_R_Reserved_signal5 5000;
BA_ "InvalidValue" SG_ 1178 EDS_R_Reserved_signal5 "";
BA_ "GenSigSendType" SG_ 1179 CHSKM_EDS_F_WarnMsg 3;
BA_ "GenSigTimeoutTime_ALL" SG_ 1179 CHSKM_EDS_F_WarnMsg 5000;
BA_ "InvalidValue" SG_ 1179 CHSKM_EDS_F_WarnMsg "";
BA_ "GenSigSendType" SG_ 1179 ALV_EDS_F_WarnMsg 3;
BA_ "GenSigTimeoutTime_ALL" SG_ 1179 ALV_EDS_F_WarnMsg 5000;
BA_ "InvalidValue" SG_ 1179 ALV_EDS_F_WarnMsg "Fh";
BA_ "GenSigSendType" SG_ 1179 EDS_F_Warning_Flag_1 4;
BA_ "GenSigTimeoutTime_ALL" SG_ 1179 EDS_F_Warning_Flag_1 5000;
BA_ "InvalidValue" SG_ 1179 EDS_F_Warning_Flag_1 "";
BA_ "GenSigSendType" SG_ 1179 EDS_F_Warning_Flag_2 4;
BA_ "GenSigTimeoutTime_ALL" SG_ 1179 EDS_F_Warning_Flag_2 5000;
BA_ "InvalidValue" SG_ 1179 EDS_F_Warning_Flag_2 "";
BA_ "GenSigSendType" SG_ 1179 EDS_F_Warning_Flag_3 4;
BA_ "GenSigTimeoutTime_ALL" SG_ 1179 EDS_F_Warning_Flag_3 5000;
BA_ "InvalidValue" SG_ 1179 EDS_F_Warning_Flag_3 "";
BA_ "GenSigSendType" SG_ 1179 EDS_F_Warning_Flag_4 4;
BA_ "GenSigTimeoutTime_ALL" SG_ 1179 EDS_F_Warning_Flag_4 5000;
BA_ "InvalidValue" SG_ 1179 EDS_F_Warning_Flag_4 "";
BA_ "GenSigSendType" SG_ 1179 EDS_F_Warning_Flag_5 4;
BA_ "GenSigTimeoutTime_ALL" SG_ 1179 EDS_F_Warning_Flag_5 5000;
BA_ "InvalidValue" SG_ 1179 EDS_F_Warning_Flag_5 "";
BA_ "GenSigSendType" SG_ 1179 EDS_F_Warning_Flag_6 4;
BA_ "GenSigTimeoutTime_ALL" SG_ 1179 EDS_F_Warning_Flag_6 5000;
BA_ "InvalidValue" SG_ 1179 EDS_F_Warning_Flag_6 "";
BA_ "GenSigSendType" SG_ 1179 EDS_F_Warning_Flag_7 4;
BA_ "GenSigTimeoutTime_ALL" SG_ 1179 EDS_F_Warning_Flag_7 5000;
BA_ "InvalidValue" SG_ 1179 EDS_F_Warning_Flag_7 "";
BA_ "GenSigSendType" SG_ 1179 EDS_F_Warning_Flag_8 4;
BA_ "GenSigTimeoutTime_ALL" SG_ 1179 EDS_F_Warning_Flag_8 5000;
BA_ "InvalidValue" SG_ 1179 EDS_F_Warning_Flag_8 "";
BA_ "GenSigSendType" SG_ 1179 EDS_F_Warning_Flag_9 4;
BA_ "GenSigTimeoutTime_ALL" SG_ 1179 EDS_F_Warning_Flag_9 5000;
BA_ "InvalidValue" SG_ 1179 EDS_F_Warning_Flag_9 "";
BA_ "GenSigSendType" SG_ 1179 EDS_F_Warning_Flag_10 4;
BA_ "GenSigTimeoutTime_ALL" SG_ 1179 EDS_F_Warning_Flag_10 5000;
BA_ "InvalidValue" SG_ 1179 EDS_F_Warning_Flag_10 "";
BA_ "GenSigSendType" SG_ 1179 EDS_F_Warning_Flag_11 4;
BA_ "GenSigTimeoutTime_ALL" SG_ 1179 EDS_F_Warning_Flag_11 5000;
BA_ "InvalidValue" SG_ 1179 EDS_F_Warning_Flag_11 "";
BA_ "GenSigSendType" SG_ 1179 EDS_F_Warning_Flag_12 4;
BA_ "GenSigTimeoutTime_ALL" SG_ 1179 EDS_F_Warning_Flag_12 5000;
BA_ "InvalidValue" SG_ 1179 EDS_F_Warning_Flag_12 "";
BA_ "GenSigSendType" SG_ 1179 EDS_F_Reserved_signal1 4;
BA_ "GenSigTimeoutTime_ALL" SG_ 1179 EDS_F_Reserved_signal1 5000;
BA_ "InvalidValue" SG_ 1179 EDS_F_Reserved_signal1 "";
BA_ "GenSigSendType" SG_ 1179 EDS_F_Reserved_signal2 4;
BA_ "GenSigTimeoutTime_ALL" SG_ 1179 EDS_F_Reserved_signal2 5000;
BA_ "InvalidValue" SG_ 1179 EDS_F_Reserved_signal2 "";
BA_ "GenSigSendType" SG_ 1179 EDS_F_Reserved_signal3 4;
BA_ "GenSigTimeoutTime_ALL" SG_ 1179 EDS_F_Reserved_signal3 5000;
BA_ "InvalidValue" SG_ 1179 EDS_F_Reserved_signal3 "";
BA_ "GenSigSendType" SG_ 1179 EDS_F_Reserved_signal4 4;
BA_ "GenSigTimeoutTime_ALL" SG_ 1179 EDS_F_Reserved_signal4 5000;
BA_ "InvalidValue" SG_ 1179 EDS_F_Reserved_signal4 "";
BA_ "GenSigSendType" SG_ 1179 EDS_F_Reserved_signal5 4;
BA_ "GenSigTimeoutTime_ALL" SG_ 1179 EDS_F_Reserved_signal5 5000;
BA_ "InvalidValue" SG_ 1179 EDS_F_Reserved_signal5 "";
BA_ "GenSigSendType" SG_ 1195 CHSKM_EPS2_WarnMsg 3;
BA_ "GenSigTimeoutTime_ALL" SG_ 1195 CHSKM_EPS2_WarnMsg 5000;
BA_ "InvalidValue" SG_ 1195 CHSKM_EPS2_WarnMsg "";
BA_ "GenSigSendType" SG_ 1195 ALV_EPS2_WarnMsg 3;
BA_ "GenSigTimeoutTime_ALL" SG_ 1195 ALV_EPS2_WarnMsg 5000;
BA_ "InvalidValue" SG_ 1195 ALV_EPS2_WarnMsg "Fh";
BA_ "GenSigSendType" SG_ 1195 EPS2_Malfunction 4;
BA_ "GenSigTimeoutTime_ALL" SG_ 1195 EPS2_Malfunction 5000;
BA_ "InvalidValue" SG_ 1195 EPS2_Malfunction "";
BA_ "GenSigSendType" SG_ 1195 EPS2_Reduced 4;
BA_ "GenSigTimeoutTime_ALL" SG_ 1195 EPS2_Reduced 5000;
BA_ "InvalidValue" SG_ 1195 EPS2_Reduced "";
BA_ "GenSigSendType" SG_ 1195 EPS2_Overheat 4;
BA_ "GenSigTimeoutTime_ALL" SG_ 1195 EPS2_Overheat 5000;
BA_ "InvalidValue" SG_ 1195 EPS2_Overheat "";
BA_ "GenSigSendType" SG_ 1195 EPS2_NotReady 4;
BA_ "GenSigTimeoutTime_ALL" SG_ 1195 EPS2_NotReady 5000;
BA_ "InvalidValue" SG_ 1195 EPS2_NotReady "";
BA_ "GenSigSendType" SG_ 1195 EPS2_Warning_Flag_5 4;
BA_ "GenSigTimeoutTime_ALL" SG_ 1195 EPS2_Warning_Flag_5 5000;
BA_ "InvalidValue" SG_ 1195 EPS2_Warning_Flag_5 "";
BA_ "GenSigSendType" SG_ 1195 EPS2_Warning_Flag_6 4;
BA_ "GenSigTimeoutTime_ALL" SG_ 1195 EPS2_Warning_Flag_6 5000;
BA_ "InvalidValue" SG_ 1195 EPS2_Warning_Flag_6 "";
BA_ "GenSigSendType" SG_ 1195 EPS2_Warning_Flag_7 4;
BA_ "GenSigTimeoutTime_ALL" SG_ 1195 EPS2_Warning_Flag_7 5000;
BA_ "InvalidValue" SG_ 1195 EPS2_Warning_Flag_7 "";
BA_ "GenSigSendType" SG_ 1195 EPS2_Warning_Flag_8 4;
BA_ "GenSigTimeoutTime_ALL" SG_ 1195 EPS2_Warning_Flag_8 5000;
BA_ "InvalidValue" SG_ 1195 EPS2_Warning_Flag_8 "";
BA_ "GenSigSendType" SG_ 1195 EPS2_Warning_Flag_9 4;
BA_ "GenSigTimeoutTime_ALL" SG_ 1195 EPS2_Warning_Flag_9 5000;
BA_ "InvalidValue" SG_ 1195 EPS2_Warning_Flag_9 "";
BA_ "GenSigSendType" SG_ 1195 EPS2_Warning_Flag_10 4;
BA_ "GenSigTimeoutTime_ALL" SG_ 1195 EPS2_Warning_Flag_10 5000;
BA_ "InvalidValue" SG_ 1195 EPS2_Warning_Flag_10 "";
BA_ "GenSigSendType" SG_ 1195 EPS2_Warning_Flag_11 4;
BA_ "GenSigTimeoutTime_ALL" SG_ 1195 EPS2_Warning_Flag_11 5000;
BA_ "InvalidValue" SG_ 1195 EPS2_Warning_Flag_11 "";
BA_ "GenSigSendType" SG_ 1195 EPS2_Warning_Flag_12 4;
BA_ "GenSigTimeoutTime_ALL" SG_ 1195 EPS2_Warning_Flag_12 5000;
BA_ "InvalidValue" SG_ 1195 EPS2_Warning_Flag_12 "";
BA_ "GenSigSendType" SG_ 1195 EPS2_Reserved_signal1 4;
BA_ "GenSigTimeoutTime_ALL" SG_ 1195 EPS2_Reserved_signal1 5000;
BA_ "InvalidValue" SG_ 1195 EPS2_Reserved_signal1 "";
BA_ "GenSigSendType" SG_ 1195 EPS2_Reserved_signal2 4;
BA_ "GenSigTimeoutTime_ALL" SG_ 1195 EPS2_Reserved_signal2 5000;
BA_ "InvalidValue" SG_ 1195 EPS2_Reserved_signal2 "";
BA_ "GenSigSendType" SG_ 1195 EPS2_Reserved_signal3 4;
BA_ "GenSigTimeoutTime_ALL" SG_ 1195 EPS2_Reserved_signal3 5000;
BA_ "InvalidValue" SG_ 1195 EPS2_Reserved_signal3 "";
BA_ "GenSigSendType" SG_ 1195 EPS2_Reserved_signal4 4;
BA_ "GenSigTimeoutTime_ALL" SG_ 1195 EPS2_Reserved_signal4 5000;
BA_ "InvalidValue" SG_ 1195 EPS2_Reserved_signal4 "";
BA_ "GenSigSendType" SG_ 1195 EPS2_Reserved_signal5 4;
BA_ "GenSigTimeoutTime_ALL" SG_ 1195 EPS2_Reserved_signal5 5000;
BA_ "InvalidValue" SG_ 1195 EPS2_Reserved_signal5 "";
BA_ "GenSigSendType" SG_ 1196 CHSKM_VCU_WarnMsg 3;
BA_ "GenSigTimeoutTime_ALL" SG_ 1196 CHSKM_VCU_WarnMsg 5000;
BA_ "GenSigSendType" SG_ 1196 ALV_VCU_WarnMsg 3;
BA_ "GenSigTimeoutTime_ALL" SG_ 1196 ALV_VCU_WarnMsg 5000;
BA_ "InvalidValue" SG_ 1196 ALV_VCU_WarnMsg "Fh";
BA_ "GenSigSendType" SG_ 1196 VCU_GearPOnlyAtStationaryAlert 4;
BA_ "GenSigTimeoutTime_ALL" SG_ 1196 VCU_GearPOnlyAtStationaryAlert 5000;
BA_ "GenSigSendType" SG_ 1196 VCU_GearP_NotPossibleAlert 4;
BA_ "GenSigTimeoutTime_ALL" SG_ 1196 VCU_GearP_NotPossibleAlert 5000;
BA_ "GenSigSendType" SG_ 1196 VCU_PressBrakeToEngageGear 4;
BA_ "GenSigTimeoutTime_ALL" SG_ 1196 VCU_PressBrakeToEngageGear 5000;
BA_ "GenSigSendType" SG_ 1196 VCU_CantChangeGear 4;
BA_ "GenSigTimeoutTime_ALL" SG_ 1196 VCU_CantChangeGear 5000;
BA_ "GenSigSendType" SG_ 1196 VCU_GearMalfunction 4;
BA_ "GenSigTimeoutTime_ALL" SG_ 1196 VCU_GearMalfunction 5000;
BA_ "GenSigSendType" SG_ 1196 VCU_RangeAlert 4;
BA_ "GenSigTimeoutTime_ALL" SG_ 1196 VCU_RangeAlert 5000;
BA_ "GenSigSendType" SG_ 1196 VCU_HVSystemReduced 4;
BA_ "GenSigTimeoutTime_ALL" SG_ 1196 VCU_HVSystemReduced 5000;
BA_ "GenSigSendType" SG_ 1196 VCU_FrontEDSReduced 4;
BA_ "GenSigTimeoutTime_ALL" SG_ 1196 VCU_FrontEDSReduced 5000;
BA_ "GenSigSendType" SG_ 1196 VCU_FrontEDS_Malfunc 4;
BA_ "GenSigTimeoutTime_ALL" SG_ 1196 VCU_FrontEDS_Malfunc 5000;
BA_ "GenSigSendType" SG_ 1196 VCU_RearEDSReduced 4;
BA_ "GenSigTimeoutTime_ALL" SG_ 1196 VCU_RearEDSReduced 5000;
BA_ "GenSigSendType" SG_ 1196 VCU_RearEDS_Malfunc 4;
BA_ "GenSigTimeoutTime_ALL" SG_ 1196 VCU_RearEDS_Malfunc 5000;
BA_ "GenSigSendType" SG_ 1196 VCU_CoolingSystem_Malfunc 4;
BA_ "GenSigTimeoutTime_ALL" SG_ 1196 VCU_CoolingSystem_Malfunc 5000;
BA_ "GenSigSendType" SG_ 1196 VCU_NeutralRequest 4;
BA_ "GenSigTimeoutTime_ALL" SG_ 1196 VCU_NeutralRequest 5000;
BA_ "GenSigSendType" SG_ 1196 VCU_SoftShutdown 4;
BA_ "GenSigTimeoutTime_ALL" SG_ 1196 VCU_SoftShutdown 5000;
BA_ "GenSigSendType" SG_ 1196 VCU_EmergencyShutdown 4;
BA_ "GenSigTimeoutTime_ALL" SG_ 1196 VCU_EmergencyShutdown 5000;
BA_ "GenSigSendType" SG_ 1196 VCU_ChgPortDoorSys_Malfunc 4;
BA_ "GenSigTimeoutTime_ALL" SG_ 1196 VCU_ChgPortDoorSys_Malfunc 5000;
BA_ "GenSigSendType" SG_ 1196 VCU_Gearchange_NotPossible 4;
BA_ "GenSigTimeoutTime_ALL" SG_ 1196 VCU_Gearchange_NotPossible 5000;
BA_ "GenSigSendType" SG_ 1196 VCU_12v_Warning 4;
BA_ "GenSigTimeoutTime_ALL" SG_ 1196 VCU_12v_Warning 5000;
BA_ "GenSigSendType" SG_ 1196 VCU_WflagRes19 4;
BA_ "GenSigTimeoutTime_ALL" SG_ 1196 VCU_WflagRes19 5000;
BA_ "GenSigSendType" SG_ 1196 VCU_WflagRes20 4;
BA_ "GenSigTimeoutTime_ALL" SG_ 1196 VCU_WflagRes20 5000;
BA_ "GenSigSendType" SG_ 1196 VCU_WflagRes21 4;
BA_ "GenSigTimeoutTime_ALL" SG_ 1196 VCU_WflagRes21 5000;
BA_ "GenSigSendType" SG_ 1196 VCU_WflagRes22 4;
BA_ "GenSigTimeoutTime_ALL" SG_ 1196 VCU_WflagRes22 5000;
BA_ "GenSigSendType" SG_ 1196 VCU_WflagRes23 4;
BA_ "GenSigTimeoutTime_ALL" SG_ 1196 VCU_WflagRes23 5000;
BA_ "GenSigSendType" SG_ 1196 VCU_WflagRes24 4;
BA_ "GenSigTimeoutTime_ALL" SG_ 1196 VCU_WflagRes24 5000;
BA_ "GenSigSendType" SG_ 1196 VCU_WflagRes25 4;
BA_ "GenSigTimeoutTime_ALL" SG_ 1196 VCU_WflagRes25 5000;
BA_ "GenSigSendType" SG_ 1196 VCU_WflagRes26 4;
BA_ "GenSigTimeoutTime_ALL" SG_ 1196 VCU_WflagRes26 5000;
BA_ "GenSigSendType" SG_ 1196 VCU_WflagRes27 4;
BA_ "GenSigTimeoutTime_ALL" SG_ 1196 VCU_WflagRes27 5000;
BA_ "GenSigSendType" SG_ 1196 VCU_SuperFastCharge_longer 4;
BA_ "GenSigTimeoutTime_ALL" SG_ 1196 VCU_SuperFastCharge_longer 5000;
BA_ "GenSigSendType" SG_ 1196 VCU_Reserved_signal1 4;
BA_ "GenSigTimeoutTime_ALL" SG_ 1196 VCU_Reserved_signal1 5000;
BA_ "GenSigSendType" SG_ 1196 VCU_Reserved_signal2 4;
BA_ "GenSigTimeoutTime_ALL" SG_ 1196 VCU_Reserved_signal2 5000;
BA_ "GenSigSendType" SG_ 1196 VCU_Reserved_signal3 4;
BA_ "GenSigTimeoutTime_ALL" SG_ 1196 VCU_Reserved_signal3 5000;
BA_ "GenSigSendType" SG_ 1213 CHSKM_POD_WarnMsg 3;
BA_ "GenSigTimeoutTime_ALL" SG_ 1213 CHSKM_POD_WarnMsg 5000;
BA_ "GenSigSendType" SG_ 1213 ALV_POD_WarnMsg 3;
BA_ "GenSigTimeoutTime_ALL" SG_ 1213 ALV_POD_WarnMsg 5000;
BA_ "InvalidValue" SG_ 1213 ALV_POD_WarnMsg "Fh";
BA_ "GenSigSendType" SG_ 1213 POD_Warning_Flag_1 4;
BA_ "GenSigTimeoutTime_ALL" SG_ 1213 POD_Warning_Flag_1 5000;
BA_ "GenSigSendType" SG_ 1213 POD_Warning_Flag_2 4;
BA_ "GenSigTimeoutTime_ALL" SG_ 1213 POD_Warning_Flag_2 5000;
BA_ "GenSigSendType" SG_ 1213 POD_Warning_Flag_3 4;
BA_ "GenSigTimeoutTime_ALL" SG_ 1213 POD_Warning_Flag_3 5000;
BA_ "GenSigSendType" SG_ 1213 POD_Warning_Flag_4 4;
BA_ "GenSigTimeoutTime_ALL" SG_ 1213 POD_Warning_Flag_4 5000;
BA_ "GenSigSendType" SG_ 1213 POD_Warning_Flag_5 4;
BA_ "GenSigTimeoutTime_ALL" SG_ 1213 POD_Warning_Flag_5 5000;
BA_ "GenSigSendType" SG_ 1213 POD_Warning_Flag_6 4;
BA_ "GenSigTimeoutTime_ALL" SG_ 1213 POD_Warning_Flag_6 5000;
BA_ "GenSigSendType" SG_ 1213 POD_Warning_Flag_7 4;
BA_ "GenSigTimeoutTime_ALL" SG_ 1213 POD_Warning_Flag_7 5000;
BA_ "GenSigSendType" SG_ 1213 POD_Warning_Flag_8 4;
BA_ "GenSigTimeoutTime_ALL" SG_ 1213 POD_Warning_Flag_8 5000;
BA_ "GenSigSendType" SG_ 1213 POD_Warning_Flag_9 4;
BA_ "GenSigTimeoutTime_ALL" SG_ 1213 POD_Warning_Flag_9 5000;
BA_ "GenSigSendType" SG_ 1213 POD_Warning_Flag_10 4;
BA_ "GenSigTimeoutTime_ALL" SG_ 1213 POD_Warning_Flag_10 5000;
BA_ "GenSigSendType" SG_ 1213 POD_Warning_Flag_11 4;
BA_ "GenSigTimeoutTime_ALL" SG_ 1213 POD_Warning_Flag_11 5000;
BA_ "GenSigSendType" SG_ 1213 POD_Warning_Flag_12 4;
BA_ "GenSigTimeoutTime_ALL" SG_ 1213 POD_Warning_Flag_12 5000;
BA_ "GenSigSendType" SG_ 1213 POD_Warning_Flag_13 4;
BA_ "GenSigTimeoutTime_ALL" SG_ 1213 POD_Warning_Flag_13 5000;
BA_ "GenSigSendType" SG_ 1213 POD_Warning_Flag_14 4;
BA_ "GenSigTimeoutTime_ALL" SG_ 1213 POD_Warning_Flag_14 5000;
BA_ "GenSigSendType" SG_ 1213 POD_Warning_Flag_15 4;
BA_ "GenSigTimeoutTime_ALL" SG_ 1213 POD_Warning_Flag_15 5000;
BA_ "GenSigSendType" SG_ 1213 POD_Warning_Flag_16 4;
BA_ "GenSigTimeoutTime_ALL" SG_ 1213 POD_Warning_Flag_16 5000;
BA_ "GenSigSendType" SG_ 1213 POD_Warning_Flag_17 4;
BA_ "GenSigTimeoutTime_ALL" SG_ 1213 POD_Warning_Flag_17 5000;
BA_ "GenSigSendType" SG_ 1213 POD_Warning_Flag_18 4;
BA_ "GenSigTimeoutTime_ALL" SG_ 1213 POD_Warning_Flag_18 5000;
BA_ "GenSigSendType" SG_ 1213 POD_Warning_Flag_19 4;
BA_ "GenSigTimeoutTime_ALL" SG_ 1213 POD_Warning_Flag_19 5000;
BA_ "GenSigSendType" SG_ 1213 POD_Warning_Flag_20 4;
BA_ "GenSigTimeoutTime_ALL" SG_ 1213 POD_Warning_Flag_20 5000;
BA_ "GenSigSendType" SG_ 1213 POD_Warning_Flag_21 4;
BA_ "GenSigTimeoutTime_ALL" SG_ 1213 POD_Warning_Flag_21 5000;
BA_ "GenSigSendType" SG_ 1213 POD_Warning_Flag_22 4;
BA_ "GenSigTimeoutTime_ALL" SG_ 1213 POD_Warning_Flag_22 5000;
BA_ "GenSigSendType" SG_ 1213 POD_Warning_Flag_23 4;
BA_ "GenSigTimeoutTime_ALL" SG_ 1213 POD_Warning_Flag_23 5000;
BA_ "GenSigSendType" SG_ 1213 POD_Warning_Flag_24 4;
BA_ "GenSigTimeoutTime_ALL" SG_ 1213 POD_Warning_Flag_24 5000;
BA_ "GenSigSendType" SG_ 1213 POD_Warning_Flag_25 4;
BA_ "GenSigTimeoutTime_ALL" SG_ 1213 POD_Warning_Flag_25 5000;
BA_ "GenSigSendType" SG_ 1213 POD_Warning_Flag_26 4;
BA_ "GenSigTimeoutTime_ALL" SG_ 1213 POD_Warning_Flag_26 5000;
BA_ "GenSigSendType" SG_ 1213 POD_Warning_Flag_27 4;
BA_ "GenSigTimeoutTime_ALL" SG_ 1213 POD_Warning_Flag_27 5000;
BA_ "GenSigSendType" SG_ 1213 POD_Warning_Flag_28 4;
BA_ "GenSigTimeoutTime_ALL" SG_ 1213 POD_Warning_Flag_28 5000;
BA_ "GenSigSendType" SG_ 1213 POD_Reserved_signal3 4;
BA_ "GenSigTimeoutTime_ALL" SG_ 1213 POD_Reserved_signal3 5000;
BA_ "GenSigSendType" SG_ 1213 POD_Reserved_signal4 4;
BA_ "GenSigTimeoutTime_ALL" SG_ 1213 POD_Reserved_signal4 5000;
BA_ "GenSigSendType" SG_ 1213 POD_Reserved_signal5 4;
BA_ "GenSigTimeoutTime_ALL" SG_ 1213 POD_Reserved_signal5 5000;
BA_ "GenSigTimeoutTime_ALL" SG_ 1282 XGW_srcNodeID 2000;
BA_ "InvalidValue" SG_ 1282 XGW_srcNodeID "FFh";
BA_ "GenSigTimeoutTime_ALL" SG_ 1282 XGW_CtrlBitVector 2000;
BA_ "InvalidValue" SG_ 1282 XGW_CtrlBitVector "";
BA_ "GenSigStartValue" SG_ 1282 XGW_usrData0 255;
BA_ "GenSigTimeoutTime_ALL" SG_ 1282 XGW_usrData0 2000;
BA_ "InvalidValue" SG_ 1282 XGW_usrData0 "";
BA_ "GenSigStartValue" SG_ 1282 XGW_usrData1 255;
BA_ "GenSigTimeoutTime_ALL" SG_ 1282 XGW_usrData1 2000;
BA_ "InvalidValue" SG_ 1282 XGW_usrData1 "";
BA_ "GenSigStartValue" SG_ 1282 XGW_usrData2 255;
BA_ "GenSigTimeoutTime_ALL" SG_ 1282 XGW_usrData2 2000;
BA_ "InvalidValue" SG_ 1282 XGW_usrData2 "";
BA_ "GenSigStartValue" SG_ 1282 XGW_usrData3 255;
BA_ "GenSigTimeoutTime_ALL" SG_ 1282 XGW_usrData3 2000;
BA_ "InvalidValue" SG_ 1282 XGW_usrData3 "";
BA_ "GenSigStartValue" SG_ 1282 XGW_usrData4 255;
BA_ "GenSigTimeoutTime_ALL" SG_ 1282 XGW_usrData4 2000;
BA_ "InvalidValue" SG_ 1282 XGW_usrData4 "";
BA_ "GenSigStartValue" SG_ 1282 XGW_usrData5 255;
BA_ "GenSigTimeoutTime_ALL" SG_ 1282 XGW_usrData5 2000;
BA_ "InvalidValue" SG_ 1282 XGW_usrData5 "";
BA_ "GenSigTimeoutTime_ALL" SG_ 1306 EDS_R_srcNodeID 2000;
BA_ "InvalidValue" SG_ 1306 EDS_R_srcNodeID "FFh";
BA_ "GenSigTimeoutTime_ALL" SG_ 1306 EDS_R_CtrlBitVector 2000;
BA_ "InvalidValue" SG_ 1306 EDS_R_CtrlBitVector "";
BA_ "GenSigStartValue" SG_ 1306 EDS_R_usrData0 255;
BA_ "GenSigTimeoutTime_ALL" SG_ 1306 EDS_R_usrData0 2000;
BA_ "InvalidValue" SG_ 1306 EDS_R_usrData0 "";
BA_ "GenSigStartValue" SG_ 1306 EDS_R_usrData1 255;
BA_ "GenSigTimeoutTime_ALL" SG_ 1306 EDS_R_usrData1 2000;
BA_ "InvalidValue" SG_ 1306 EDS_R_usrData1 "";
BA_ "GenSigStartValue" SG_ 1306 EDS_R_usrData2 255;
BA_ "GenSigTimeoutTime_ALL" SG_ 1306 EDS_R_usrData2 2000;
BA_ "InvalidValue" SG_ 1306 EDS_R_usrData2 "";
BA_ "GenSigStartValue" SG_ 1306 EDS_R_usrData3 255;
BA_ "GenSigTimeoutTime_ALL" SG_ 1306 EDS_R_usrData3 2000;
BA_ "InvalidValue" SG_ 1306 EDS_R_usrData3 "";
BA_ "GenSigStartValue" SG_ 1306 EDS_R_usrData4 255;
BA_ "GenSigTimeoutTime_ALL" SG_ 1306 EDS_R_usrData4 2000;
BA_ "InvalidValue" SG_ 1306 EDS_R_usrData4 "";
BA_ "GenSigStartValue" SG_ 1306 EDS_R_usrData5 255;
BA_ "GenSigTimeoutTime_ALL" SG_ 1306 EDS_R_usrData5 2000;
BA_ "InvalidValue" SG_ 1306 EDS_R_usrData5 "";
BA_ "GenSigTimeoutTime_ALL" SG_ 1307 EDS_F_srcNodeID 2000;
BA_ "InvalidValue" SG_ 1307 EDS_F_srcNodeID "FFh";
BA_ "GenSigTimeoutTime_ALL" SG_ 1307 EDS_F_CtrlBitVector 2000;
BA_ "InvalidValue" SG_ 1307 EDS_F_CtrlBitVector "";
BA_ "GenSigStartValue" SG_ 1307 EDS_F_usrData0 255;
BA_ "GenSigTimeoutTime_ALL" SG_ 1307 EDS_F_usrData0 2000;
BA_ "InvalidValue" SG_ 1307 EDS_F_usrData0 "";
BA_ "GenSigStartValue" SG_ 1307 EDS_F_usrData1 255;
BA_ "GenSigTimeoutTime_ALL" SG_ 1307 EDS_F_usrData1 2000;
BA_ "InvalidValue" SG_ 1307 EDS_F_usrData1 "";
BA_ "GenSigStartValue" SG_ 1307 EDS_F_usrData2 255;
BA_ "GenSigTimeoutTime_ALL" SG_ 1307 EDS_F_usrData2 2000;
BA_ "InvalidValue" SG_ 1307 EDS_F_usrData2 "";
BA_ "GenSigStartValue" SG_ 1307 EDS_F_usrData3 255;
BA_ "GenSigTimeoutTime_ALL" SG_ 1307 EDS_F_usrData3 2000;
BA_ "InvalidValue" SG_ 1307 EDS_F_usrData3 "";
BA_ "GenSigStartValue" SG_ 1307 EDS_F_usrData4 255;
BA_ "GenSigTimeoutTime_ALL" SG_ 1307 EDS_F_usrData4 2000;
BA_ "InvalidValue" SG_ 1307 EDS_F_usrData4 "";
BA_ "GenSigStartValue" SG_ 1307 EDS_F_usrData5 255;
BA_ "GenSigTimeoutTime_ALL" SG_ 1307 EDS_F_usrData5 2000;
BA_ "InvalidValue" SG_ 1307 EDS_F_usrData5 "";
BA_ "GenSigTimeoutTime_ALL" SG_ 1324 VCU_srcNodeID 2000;
BA_ "InvalidValue" SG_ 1324 VCU_srcNodeID "FFh";
BA_ "GenSigTimeoutTime_ALL" SG_ 1324 VCU_CtrlBitVector 2000;
BA_ "InvalidValue" SG_ 1324 VCU_CtrlBitVector "";
BA_ "GenSigStartValue" SG_ 1324 VCU_usrData0 255;
BA_ "GenSigTimeoutTime_ALL" SG_ 1324 VCU_usrData0 2000;
BA_ "InvalidValue" SG_ 1324 VCU_usrData0 "";
BA_ "GenSigStartValue" SG_ 1324 VCU_usrData1 255;
BA_ "GenSigTimeoutTime_ALL" SG_ 1324 VCU_usrData1 2000;
BA_ "InvalidValue" SG_ 1324 VCU_usrData1 "";
BA_ "GenSigStartValue" SG_ 1324 VCU_usrData2 255;
BA_ "GenSigTimeoutTime_ALL" SG_ 1324 VCU_usrData2 2000;
BA_ "InvalidValue" SG_ 1324 VCU_usrData2 "";
BA_ "GenSigStartValue" SG_ 1324 VCU_usrData3 255;
BA_ "GenSigTimeoutTime_ALL" SG_ 1324 VCU_usrData3 2000;
BA_ "InvalidValue" SG_ 1324 VCU_usrData3 "";
BA_ "GenSigStartValue" SG_ 1324 VCU_usrData4 255;
BA_ "GenSigTimeoutTime_ALL" SG_ 1324 VCU_usrData4 2000;
BA_ "InvalidValue" SG_ 1324 VCU_usrData4 "";
BA_ "GenSigStartValue" SG_ 1324 VCU_usrData5 255;
BA_ "GenSigTimeoutTime_ALL" SG_ 1324 VCU_usrData5 2000;
BA_ "InvalidValue" SG_ 1324 VCU_usrData5 "";
BA_ "GenSigTimeoutTime_ALL" SG_ 1344 ADAS_srcNodeID 2000;
BA_ "InvalidValue" SG_ 1344 ADAS_srcNodeID "FFh";
BA_ "GenSigTimeoutTime_ALL" SG_ 1344 ADAS_CtrlBitVector 2000;
BA_ "InvalidValue" SG_ 1344 ADAS_CtrlBitVector "";
BA_ "GenSigStartValue" SG_ 1344 ADAS_usrData0 255;
BA_ "GenSigTimeoutTime_ALL" SG_ 1344 ADAS_usrData0 2000;
BA_ "InvalidValue" SG_ 1344 ADAS_usrData0 "";
BA_ "GenSigStartValue" SG_ 1344 ADAS_usrData1 255;
BA_ "GenSigTimeoutTime_ALL" SG_ 1344 ADAS_usrData1 2000;
BA_ "InvalidValue" SG_ 1344 ADAS_usrData1 "";
BA_ "GenSigStartValue" SG_ 1344 ADAS_usrData2 255;
BA_ "GenSigTimeoutTime_ALL" SG_ 1344 ADAS_usrData2 2000;
BA_ "InvalidValue" SG_ 1344 ADAS_usrData2 "";
BA_ "GenSigStartValue" SG_ 1344 ADAS_usrData3 255;
BA_ "GenSigTimeoutTime_ALL" SG_ 1344 ADAS_usrData3 2000;
BA_ "InvalidValue" SG_ 1344 ADAS_usrData3 "";
BA_ "GenSigStartValue" SG_ 1344 ADAS_usrData4 255;
BA_ "GenSigTimeoutTime_ALL" SG_ 1344 ADAS_usrData4 2000;
BA_ "InvalidValue" SG_ 1344 ADAS_usrData4 "";
BA_ "GenSigStartValue" SG_ 1344 ADAS_usrData5 255;
BA_ "GenSigTimeoutTime_ALL" SG_ 1344 ADAS_usrData5 2000;
BA_ "InvalidValue" SG_ 1344 ADAS_usrData5 "";
BA_ "GenSigSendType" SG_ 1552 GS_DiagRespData0 7;
BA_ "InvalidValue" SG_ 1552 GS_DiagRespData0 "";
BA_ "GenSigSendType" SG_ 1552 GS_DiagRespData1 7;
BA_ "InvalidValue" SG_ 1552 GS_DiagRespData1 "";
BA_ "GenSigSendType" SG_ 1552 GS_DiagRespData2 7;
BA_ "InvalidValue" SG_ 1552 GS_DiagRespData2 "";
BA_ "GenSigSendType" SG_ 1552 GS_DiagRespData3 7;
BA_ "InvalidValue" SG_ 1552 GS_DiagRespData3 "";
BA_ "GenSigSendType" SG_ 1552 GS_DiagRespData4 7;
BA_ "InvalidValue" SG_ 1552 GS_DiagRespData4 "";
BA_ "GenSigSendType" SG_ 1552 GS_DiagRespData5 7;
BA_ "InvalidValue" SG_ 1552 GS_DiagRespData5 "";
BA_ "GenSigSendType" SG_ 1552 GS_DiagRespData6 7;
BA_ "InvalidValue" SG_ 1552 GS_DiagRespData6 "";
BA_ "GenSigSendType" SG_ 1552 GS_DiagRespData7 7;
BA_ "InvalidValue" SG_ 1552 GS_DiagRespData7 "";
BA_ "GenSigSendType" SG_ 1562 EDS_R_DiagRespData0 7;
BA_ "InvalidValue" SG_ 1562 EDS_R_DiagRespData0 "";
BA_ "GenSigSendType" SG_ 1562 EDS_R_DiagRespData1 7;
BA_ "InvalidValue" SG_ 1562 EDS_R_DiagRespData1 "";
BA_ "GenSigSendType" SG_ 1562 EDS_R_DiagRespData2 7;
BA_ "InvalidValue" SG_ 1562 EDS_R_DiagRespData2 "";
BA_ "GenSigSendType" SG_ 1562 EDS_R_DiagRespData3 7;
BA_ "InvalidValue" SG_ 1562 EDS_R_DiagRespData3 "";
BA_ "GenSigSendType" SG_ 1562 EDS_R_DiagRespData4 7;
BA_ "InvalidValue" SG_ 1562 EDS_R_DiagRespData4 "";
BA_ "GenSigSendType" SG_ 1562 EDS_R_DiagRespData5 7;
BA_ "InvalidValue" SG_ 1562 EDS_R_DiagRespData5 "";
BA_ "GenSigSendType" SG_ 1562 EDS_R_DiagRespData6 7;
BA_ "InvalidValue" SG_ 1562 EDS_R_DiagRespData6 "";
BA_ "GenSigSendType" SG_ 1562 EDS_R_DiagRespData7 7;
BA_ "InvalidValue" SG_ 1562 EDS_R_DiagRespData7 "";
BA_ "GenSigSendType" SG_ 1563 EDS_F_DiagRespData0 7;
BA_ "InvalidValue" SG_ 1563 EDS_F_DiagRespData0 "";
BA_ "GenSigSendType" SG_ 1563 EDS_F_DiagRespData1 7;
BA_ "InvalidValue" SG_ 1563 EDS_F_DiagRespData1 "";
BA_ "GenSigSendType" SG_ 1563 EDS_F_DiagRespData2 7;
BA_ "InvalidValue" SG_ 1563 EDS_F_DiagRespData2 "";
BA_ "GenSigSendType" SG_ 1563 EDS_F_DiagRespData3 7;
BA_ "InvalidValue" SG_ 1563 EDS_F_DiagRespData3 "";
BA_ "GenSigSendType" SG_ 1563 EDS_F_DiagRespData4 7;
BA_ "InvalidValue" SG_ 1563 EDS_F_DiagRespData4 "";
BA_ "GenSigSendType" SG_ 1563 EDS_F_DiagRespData5 7;
BA_ "InvalidValue" SG_ 1563 EDS_F_DiagRespData5 "";
BA_ "GenSigSendType" SG_ 1563 EDS_F_DiagRespData6 7;
BA_ "InvalidValue" SG_ 1563 EDS_F_DiagRespData6 "";
BA_ "GenSigSendType" SG_ 1563 EDS_F_DiagRespData7 7;
BA_ "InvalidValue" SG_ 1563 EDS_F_DiagRespData7 "";
BA_ "GenSigSendType" SG_ 1575 RCU_DiagRespData0 7;
BA_ "InvalidValue" SG_ 1575 RCU_DiagRespData0 "";
BA_ "GenSigSendType" SG_ 1575 RCU_DiagRespData1 7;
BA_ "InvalidValue" SG_ 1575 RCU_DiagRespData1 "";
BA_ "GenSigSendType" SG_ 1575 RCU_DiagRespData2 7;
BA_ "InvalidValue" SG_ 1575 RCU_DiagRespData2 "";
BA_ "GenSigSendType" SG_ 1575 RCU_DiagRespData3 7;
BA_ "InvalidValue" SG_ 1575 RCU_DiagRespData3 "";
BA_ "GenSigSendType" SG_ 1575 RCU_DiagRespData4 7;
BA_ "InvalidValue" SG_ 1575 RCU_DiagRespData4 "";
BA_ "GenSigSendType" SG_ 1575 RCU_DiagRespData5 7;
BA_ "InvalidValue" SG_ 1575 RCU_DiagRespData5 "";
BA_ "GenSigSendType" SG_ 1575 RCU_DiagRespData6 7;
BA_ "InvalidValue" SG_ 1575 RCU_DiagRespData6 "";
BA_ "GenSigSendType" SG_ 1575 RCU_DiagRespData7 7;
BA_ "InvalidValue" SG_ 1575 RCU_DiagRespData7 "";
BA_ "GenSigSendType" SG_ 1577 IDB_DiagRespData0 7;
BA_ "InvalidValue" SG_ 1577 IDB_DiagRespData0 "";
BA_ "GenSigSendType" SG_ 1577 IDB_DiagRespData1 7;
BA_ "InvalidValue" SG_ 1577 IDB_DiagRespData1 "";
BA_ "GenSigSendType" SG_ 1577 IDB_DiagRespData2 7;
BA_ "InvalidValue" SG_ 1577 IDB_DiagRespData2 "";
BA_ "GenSigSendType" SG_ 1577 IDB_DiagRespData3 7;
BA_ "InvalidValue" SG_ 1577 IDB_DiagRespData3 "";
BA_ "GenSigSendType" SG_ 1577 IDB_DiagRespData4 7;
BA_ "InvalidValue" SG_ 1577 IDB_DiagRespData4 "";
BA_ "GenSigSendType" SG_ 1577 IDB_DiagRespData5 7;
BA_ "InvalidValue" SG_ 1577 IDB_DiagRespData5 "";
BA_ "GenSigSendType" SG_ 1577 IDB_DiagRespData6 7;
BA_ "InvalidValue" SG_ 1577 IDB_DiagRespData6 "";
BA_ "GenSigSendType" SG_ 1577 IDB_DiagRespData7 7;
BA_ "InvalidValue" SG_ 1577 IDB_DiagRespData7 "";
BA_ "GenSigSendType" SG_ 1579 EPS2_DiagRespData0 7;
BA_ "InvalidValue" SG_ 1579 EPS2_DiagRespData0 "";
BA_ "GenSigSendType" SG_ 1579 EPS2_DiagRespData1 7;
BA_ "InvalidValue" SG_ 1579 EPS2_DiagRespData1 "";
BA_ "GenSigSendType" SG_ 1579 EPS2_DiagRespData2 7;
BA_ "InvalidValue" SG_ 1579 EPS2_DiagRespData2 "";
BA_ "GenSigSendType" SG_ 1579 EPS2_DiagRespData3 7;
BA_ "InvalidValue" SG_ 1579 EPS2_DiagRespData3 "";
BA_ "GenSigSendType" SG_ 1579 EPS2_DiagRespData4 7;
BA_ "InvalidValue" SG_ 1579 EPS2_DiagRespData4 "";
BA_ "GenSigSendType" SG_ 1579 EPS2_DiagRespData5 7;
BA_ "InvalidValue" SG_ 1579 EPS2_DiagRespData5 "";
BA_ "GenSigSendType" SG_ 1579 EPS2_DiagRespData6 7;
BA_ "InvalidValue" SG_ 1579 EPS2_DiagRespData6 "";
BA_ "GenSigSendType" SG_ 1579 EPS2_DiagRespData7 7;
BA_ "InvalidValue" SG_ 1579 EPS2_DiagRespData7 "";
BA_ "GenSigSendType" SG_ 1580 VCU_DiagRespData0 7;
BA_ "InvalidValue" SG_ 1580 VCU_DiagRespData0 "";
BA_ "GenSigSendType" SG_ 1580 VCU_DiagRespData1 7;
BA_ "InvalidValue" SG_ 1580 VCU_DiagRespData1 "";
BA_ "GenSigSendType" SG_ 1580 VCU_DiagRespData2 7;
BA_ "InvalidValue" SG_ 1580 VCU_DiagRespData2 "";
BA_ "GenSigSendType" SG_ 1580 VCU_DiagRespData3 7;
BA_ "InvalidValue" SG_ 1580 VCU_DiagRespData3 "";
BA_ "GenSigSendType" SG_ 1580 VCU_DiagRespData4 7;
BA_ "InvalidValue" SG_ 1580 VCU_DiagRespData4 "";
BA_ "GenSigSendType" SG_ 1580 VCU_DiagRespData5 7;
BA_ "InvalidValue" SG_ 1580 VCU_DiagRespData5 "";
BA_ "GenSigSendType" SG_ 1580 VCU_DiagRespData6 7;
BA_ "InvalidValue" SG_ 1580 VCU_DiagRespData6 "";
BA_ "GenSigSendType" SG_ 1580 VCU_DiagRespData7 7;
BA_ "InvalidValue" SG_ 1580 VCU_DiagRespData7 "";
BA_ "GenSigSendType" SG_ 1597 POD_DCDC_DiagRespData0 7;
BA_ "InvalidValue" SG_ 1597 POD_DCDC_DiagRespData0 "";
BA_ "GenSigSendType" SG_ 1597 POD_DCDC_DiagRespData1 7;
BA_ "InvalidValue" SG_ 1597 POD_DCDC_DiagRespData1 "";
BA_ "GenSigSendType" SG_ 1597 POD_DCDC_DiagRespData2 7;
BA_ "InvalidValue" SG_ 1597 POD_DCDC_DiagRespData2 "";
BA_ "GenSigSendType" SG_ 1597 POD_DCDC_DiagRespData3 7;
BA_ "InvalidValue" SG_ 1597 POD_DCDC_DiagRespData3 "";
BA_ "GenSigSendType" SG_ 1597 POD_DCDC_DiagRespData4 7;
BA_ "InvalidValue" SG_ 1597 POD_DCDC_DiagRespData4 "";
BA_ "GenSigSendType" SG_ 1597 POD_DCDC_DiagRespData5 7;
BA_ "InvalidValue" SG_ 1597 POD_DCDC_DiagRespData5 "";
BA_ "GenSigSendType" SG_ 1597 POD_DCDC_DiagRespData6 7;
BA_ "InvalidValue" SG_ 1597 POD_DCDC_DiagRespData6 "";
BA_ "GenSigSendType" SG_ 1597 POD_DCDC_DiagRespData7 7;
BA_ "InvalidValue" SG_ 1597 POD_DCDC_DiagRespData7 "";
BA_ "GenSigSendType" SG_ 1598 POD_OBC_DiagRespData0 7;
BA_ "InvalidValue" SG_ 1598 POD_OBC_DiagRespData0 "";
BA_ "GenSigSendType" SG_ 1598 POD_OBC_DiagRespData1 7;
BA_ "InvalidValue" SG_ 1598 POD_OBC_DiagRespData1 "";
BA_ "GenSigSendType" SG_ 1598 POD_OBC_DiagRespData2 7;
BA_ "InvalidValue" SG_ 1598 POD_OBC_DiagRespData2 "";
BA_ "GenSigSendType" SG_ 1598 POD_OBC_DiagRespData3 7;
BA_ "InvalidValue" SG_ 1598 POD_OBC_DiagRespData3 "";
BA_ "GenSigSendType" SG_ 1598 POD_OBC_DiagRespData4 7;
BA_ "InvalidValue" SG_ 1598 POD_OBC_DiagRespData4 "";
BA_ "GenSigSendType" SG_ 1598 POD_OBC_DiagRespData5 7;
BA_ "InvalidValue" SG_ 1598 POD_OBC_DiagRespData5 "";
BA_ "GenSigSendType" SG_ 1598 POD_OBC_DiagRespData6 7;
BA_ "InvalidValue" SG_ 1598 POD_OBC_DiagRespData6 "";
BA_ "GenSigSendType" SG_ 1598 POD_OBC_DiagRespData7 7;
BA_ "InvalidValue" SG_ 1598 POD_OBC_DiagRespData7 "";
BA_ "GenSigSendType" SG_ 1599 POD_DiagRespData0 7;
BA_ "InvalidValue" SG_ 1599 POD_DiagRespData0 "";
BA_ "GenSigSendType" SG_ 1599 POD_DiagRespData1 7;
BA_ "InvalidValue" SG_ 1599 POD_DiagRespData1 "";
BA_ "GenSigSendType" SG_ 1599 POD_DiagRespData2 7;
BA_ "InvalidValue" SG_ 1599 POD_DiagRespData2 "";
BA_ "GenSigSendType" SG_ 1599 POD_DiagRespData3 7;
BA_ "InvalidValue" SG_ 1599 POD_DiagRespData3 "";
BA_ "GenSigSendType" SG_ 1599 POD_DiagRespData4 7;
BA_ "InvalidValue" SG_ 1599 POD_DiagRespData4 "";
BA_ "GenSigSendType" SG_ 1599 POD_DiagRespData5 7;
BA_ "InvalidValue" SG_ 1599 POD_DiagRespData5 "";
BA_ "GenSigSendType" SG_ 1599 POD_DiagRespData6 7;
BA_ "InvalidValue" SG_ 1599 POD_DiagRespData6 "";
BA_ "GenSigSendType" SG_ 1599 POD_DiagRespData7 7;
BA_ "InvalidValue" SG_ 1599 POD_DiagRespData7 "";
BA_ "GenSigSendType" SG_ 1605 POD_GW_Flash_Resp 7;
BA_ "InvalidValue" SG_ 1605 POD_GW_Flash_Resp "";
BA_ "GenSigSendType" SG_ 1680 GS_DiagReqData0 7;
BA_ "InvalidValue" SG_ 1680 GS_DiagReqData0 "";
BA_ "GenSigSendType" SG_ 1680 GS_DiagReqData1 7;
BA_ "InvalidValue" SG_ 1680 GS_DiagReqData1 "";
BA_ "GenSigSendType" SG_ 1680 GS_DiagReqData2 7;
BA_ "InvalidValue" SG_ 1680 GS_DiagReqData2 "";
BA_ "GenSigSendType" SG_ 1680 GS_DiagReqData3 7;
BA_ "InvalidValue" SG_ 1680 GS_DiagReqData3 "";
BA_ "GenSigSendType" SG_ 1680 GS_DiagReqData4 7;
BA_ "InvalidValue" SG_ 1680 GS_DiagReqData4 "";
BA_ "GenSigSendType" SG_ 1680 GS_DiagReqData5 7;
BA_ "InvalidValue" SG_ 1680 GS_DiagReqData5 "";
BA_ "GenSigSendType" SG_ 1680 GS_DiagReqData6 7;
BA_ "InvalidValue" SG_ 1680 GS_DiagReqData6 "";
BA_ "GenSigSendType" SG_ 1680 GS_DiagReqData7 7;
BA_ "InvalidValue" SG_ 1680 GS_DiagReqData7 "";
BA_ "GenSigSendType" SG_ 1690 EDS_R_DiagReqData0 7;
BA_ "InvalidValue" SG_ 1690 EDS_R_DiagReqData0 "";
BA_ "GenSigSendType" SG_ 1690 EDS_R_DiagReqData1 7;
BA_ "InvalidValue" SG_ 1690 EDS_R_DiagReqData1 "";
BA_ "GenSigSendType" SG_ 1690 EDS_R_DiagReqData2 7;
BA_ "InvalidValue" SG_ 1690 EDS_R_DiagReqData2 "";
BA_ "GenSigSendType" SG_ 1690 EDS_R_DiagReqData3 7;
BA_ "InvalidValue" SG_ 1690 EDS_R_DiagReqData3 "";
BA_ "GenSigSendType" SG_ 1690 EDS_R_DiagReqData4 7;
BA_ "InvalidValue" SG_ 1690 EDS_R_DiagReqData4 "";
BA_ "GenSigSendType" SG_ 1690 EDS_R_DiagReqData5 7;
BA_ "InvalidValue" SG_ 1690 EDS_R_DiagReqData5 "";
BA_ "GenSigSendType" SG_ 1690 EDS_R_DiagReqData6 7;
BA_ "InvalidValue" SG_ 1690 EDS_R_DiagReqData6 "";
BA_ "GenSigSendType" SG_ 1690 EDS_R_DiagReqData7 7;
BA_ "InvalidValue" SG_ 1690 EDS_R_DiagReqData7 "";
BA_ "GenSigSendType" SG_ 1691 EDS_F_DiagReqData0 7;
BA_ "InvalidValue" SG_ 1691 EDS_F_DiagReqData0 "";
BA_ "GenSigSendType" SG_ 1691 EDS_F_DiagReqData1 7;
BA_ "InvalidValue" SG_ 1691 EDS_F_DiagReqData1 "";
BA_ "GenSigSendType" SG_ 1691 EDS_F_DiagReqData2 7;
BA_ "InvalidValue" SG_ 1691 EDS_F_DiagReqData2 "";
BA_ "GenSigSendType" SG_ 1691 EDS_F_DiagReqData3 7;
BA_ "InvalidValue" SG_ 1691 EDS_F_DiagReqData3 "";
BA_ "GenSigSendType" SG_ 1691 EDS_F_DiagReqData4 7;
BA_ "InvalidValue" SG_ 1691 EDS_F_DiagReqData4 "";
BA_ "GenSigSendType" SG_ 1691 EDS_F_DiagReqData5 7;
BA_ "InvalidValue" SG_ 1691 EDS_F_DiagReqData5 "";
BA_ "GenSigSendType" SG_ 1691 EDS_F_DiagReqData6 7;
BA_ "InvalidValue" SG_ 1691 EDS_F_DiagReqData6 "";
BA_ "GenSigSendType" SG_ 1691 EDS_F_DiagReqData7 7;
BA_ "InvalidValue" SG_ 1691 EDS_F_DiagReqData7 "";
BA_ "GenSigSendType" SG_ 1703 RCU_DiagReqData0 7;
BA_ "InvalidValue" SG_ 1703 RCU_DiagReqData0 "";
BA_ "GenSigSendType" SG_ 1703 RCU_DiagReqData1 7;
BA_ "InvalidValue" SG_ 1703 RCU_DiagReqData1 "";
BA_ "GenSigSendType" SG_ 1703 RCU_DiagReqData2 7;
BA_ "InvalidValue" SG_ 1703 RCU_DiagReqData2 "";
BA_ "GenSigSendType" SG_ 1703 RCU_DiagReqData3 7;
BA_ "InvalidValue" SG_ 1703 RCU_DiagReqData3 "";
BA_ "GenSigSendType" SG_ 1703 RCU_DiagReqData4 7;
BA_ "InvalidValue" SG_ 1703 RCU_DiagReqData4 "";
BA_ "GenSigSendType" SG_ 1703 RCU_DiagReqData5 7;
BA_ "InvalidValue" SG_ 1703 RCU_DiagReqData5 "";
BA_ "GenSigSendType" SG_ 1703 RCU_DiagReqData6 7;
BA_ "InvalidValue" SG_ 1703 RCU_DiagReqData6 "";
BA_ "GenSigSendType" SG_ 1703 RCU_DiagReqData7 7;
BA_ "InvalidValue" SG_ 1703 RCU_DiagReqData7 "";
BA_ "GenSigSendType" SG_ 1705 IDB_DiagReqData0 7;
BA_ "InvalidValue" SG_ 1705 IDB_DiagReqData0 "";
BA_ "GenSigSendType" SG_ 1705 IDB_DiagReqData1 7;
BA_ "InvalidValue" SG_ 1705 IDB_DiagReqData1 "";
BA_ "GenSigSendType" SG_ 1705 IDB_DiagReqData2 7;
BA_ "InvalidValue" SG_ 1705 IDB_DiagReqData2 "";
BA_ "GenSigSendType" SG_ 1705 IDB_DiagReqData3 7;
BA_ "InvalidValue" SG_ 1705 IDB_DiagReqData3 "";
BA_ "GenSigSendType" SG_ 1705 IDB_DiagReqData4 7;
BA_ "InvalidValue" SG_ 1705 IDB_DiagReqData4 "";
BA_ "GenSigSendType" SG_ 1705 IDB_DiagReqData5 7;
BA_ "InvalidValue" SG_ 1705 IDB_DiagReqData5 "";
BA_ "GenSigSendType" SG_ 1705 IDB_DiagReqData6 7;
BA_ "InvalidValue" SG_ 1705 IDB_DiagReqData6 "";
BA_ "GenSigSendType" SG_ 1705 IDB_DiagReqData7 7;
BA_ "InvalidValue" SG_ 1705 IDB_DiagReqData7 "";
BA_ "GenSigSendType" SG_ 1707 EPS2_DiagReqData0 7;
BA_ "InvalidValue" SG_ 1707 EPS2_DiagReqData0 "";
BA_ "GenSigSendType" SG_ 1707 EPS2_DiagReqData1 7;
BA_ "InvalidValue" SG_ 1707 EPS2_DiagReqData1 "";
BA_ "GenSigSendType" SG_ 1707 EPS2_DiagReqData2 7;
BA_ "InvalidValue" SG_ 1707 EPS2_DiagReqData2 "";
BA_ "GenSigSendType" SG_ 1707 EPS2_DiagReqData3 7;
BA_ "InvalidValue" SG_ 1707 EPS2_DiagReqData3 "";
BA_ "GenSigSendType" SG_ 1707 EPS2_DiagReqData4 7;
BA_ "InvalidValue" SG_ 1707 EPS2_DiagReqData4 "";
BA_ "GenSigSendType" SG_ 1707 EPS2_DiagReqData5 7;
BA_ "InvalidValue" SG_ 1707 EPS2_DiagReqData5 "";
BA_ "GenSigSendType" SG_ 1707 EPS2_DiagReqData6 7;
BA_ "InvalidValue" SG_ 1707 EPS2_DiagReqData6 "";
BA_ "GenSigSendType" SG_ 1707 EPS2_DiagReqData7 7;
BA_ "InvalidValue" SG_ 1707 EPS2_DiagReqData7 "";
BA_ "GenSigSendType" SG_ 1708 VCU_DiagReqData0 7;
BA_ "InvalidValue" SG_ 1708 VCU_DiagReqData0 "";
BA_ "GenSigSendType" SG_ 1708 VCU_DiagReqData1 7;
BA_ "InvalidValue" SG_ 1708 VCU_DiagReqData1 "";
BA_ "GenSigSendType" SG_ 1708 VCU_DiagReqData2 7;
BA_ "InvalidValue" SG_ 1708 VCU_DiagReqData2 "";
BA_ "GenSigSendType" SG_ 1708 VCU_DiagReqData3 7;
BA_ "InvalidValue" SG_ 1708 VCU_DiagReqData3 "";
BA_ "GenSigSendType" SG_ 1708 VCU_DiagReqData4 7;
BA_ "InvalidValue" SG_ 1708 VCU_DiagReqData4 "";
BA_ "GenSigSendType" SG_ 1708 VCU_DiagReqData5 7;
BA_ "InvalidValue" SG_ 1708 VCU_DiagReqData5 "";
BA_ "GenSigSendType" SG_ 1708 VCU_DiagReqData6 7;
BA_ "InvalidValue" SG_ 1708 VCU_DiagReqData6 "";
BA_ "GenSigSendType" SG_ 1708 VCU_DiagReqData7 7;
BA_ "InvalidValue" SG_ 1708 VCU_DiagReqData7 "";
BA_ "GenSigSendType" SG_ 1725 POD_DCDC_DiagReqData0 7;
BA_ "InvalidValue" SG_ 1725 POD_DCDC_DiagReqData0 "";
BA_ "GenSigSendType" SG_ 1725 POD_DCDC_DiagReqData1 7;
BA_ "InvalidValue" SG_ 1725 POD_DCDC_DiagReqData1 "";
BA_ "GenSigSendType" SG_ 1725 POD_DCDC_DiagReqData2 7;
BA_ "InvalidValue" SG_ 1725 POD_DCDC_DiagReqData2 "";
BA_ "GenSigSendType" SG_ 1725 POD_DCDC_DiagReqData3 7;
BA_ "InvalidValue" SG_ 1725 POD_DCDC_DiagReqData3 "";
BA_ "GenSigSendType" SG_ 1725 POD_DCDC_DiagReqData4 7;
BA_ "InvalidValue" SG_ 1725 POD_DCDC_DiagReqData4 "";
BA_ "GenSigSendType" SG_ 1725 POD_DCDC_DiagReqData5 7;
BA_ "InvalidValue" SG_ 1725 POD_DCDC_DiagReqData5 "";
BA_ "GenSigSendType" SG_ 1725 POD_DCDC_DiagReqData6 7;
BA_ "InvalidValue" SG_ 1725 POD_DCDC_DiagReqData6 "";
BA_ "GenSigSendType" SG_ 1725 POD_DCDC_DiagReqData7 7;
BA_ "InvalidValue" SG_ 1725 POD_DCDC_DiagReqData7 "";
BA_ "GenSigSendType" SG_ 1726 POD_OBC_DiagReqData0 7;
BA_ "InvalidValue" SG_ 1726 POD_OBC_DiagReqData0 "";
BA_ "GenSigSendType" SG_ 1726 POD_OBC_DiagReqData1 7;
BA_ "InvalidValue" SG_ 1726 POD_OBC_DiagReqData1 "";
BA_ "GenSigSendType" SG_ 1726 POD_OBC_DiagReqData2 7;
BA_ "InvalidValue" SG_ 1726 POD_OBC_DiagReqData2 "";
BA_ "GenSigSendType" SG_ 1726 POD_OBC_DiagReqData3 7;
BA_ "InvalidValue" SG_ 1726 POD_OBC_DiagReqData3 "";
BA_ "GenSigSendType" SG_ 1726 POD_OBC_DiagReqData4 7;
BA_ "InvalidValue" SG_ 1726 POD_OBC_DiagReqData4 "";
BA_ "GenSigSendType" SG_ 1726 POD_OBC_DiagReqData5 7;
BA_ "InvalidValue" SG_ 1726 POD_OBC_DiagReqData5 "";
BA_ "GenSigSendType" SG_ 1726 POD_OBC_DiagReqData6 7;
BA_ "InvalidValue" SG_ 1726 POD_OBC_DiagReqData6 "";
BA_ "GenSigSendType" SG_ 1726 POD_OBC_DiagReqData7 7;
BA_ "InvalidValue" SG_ 1726 POD_OBC_DiagReqData7 "";
BA_ "GenSigSendType" SG_ 1727 POD_DiagReqData0 7;
BA_ "InvalidValue" SG_ 1727 POD_DiagReqData0 "";
BA_ "GenSigSendType" SG_ 1727 POD_DiagReqData1 7;
BA_ "InvalidValue" SG_ 1727 POD_DiagReqData1 "";
BA_ "GenSigSendType" SG_ 1727 POD_DiagReqData2 7;
BA_ "InvalidValue" SG_ 1727 POD_DiagReqData2 "";
BA_ "GenSigSendType" SG_ 1727 POD_DiagReqData3 7;
BA_ "InvalidValue" SG_ 1727 POD_DiagReqData3 "";
BA_ "GenSigSendType" SG_ 1727 POD_DiagReqData4 7;
BA_ "InvalidValue" SG_ 1727 POD_DiagReqData4 "";
BA_ "GenSigSendType" SG_ 1727 POD_DiagReqData5 7;
BA_ "InvalidValue" SG_ 1727 POD_DiagReqData5 "";
BA_ "GenSigSendType" SG_ 1727 POD_DiagReqData6 7;
BA_ "InvalidValue" SG_ 1727 POD_DiagReqData6 "";
BA_ "GenSigSendType" SG_ 1727 POD_DiagReqData7 7;
BA_ "InvalidValue" SG_ 1727 POD_DiagReqData7 "";
BA_ "GenSigSendType" SG_ 1733 POD_GW_Flash_Req 7;
BA_ "InvalidValue" SG_ 1733 POD_GW_Flash_Req "";
BA_ "GenSigSendType" SG_ 1775 DiagReqAllCANData0 7;
BA_ "InvalidValue" SG_ 1775 DiagReqAllCANData0 "";
BA_ "GenSigSendType" SG_ 1775 DiagReqAllCANData1 7;
BA_ "InvalidValue" SG_ 1775 DiagReqAllCANData1 "";
BA_ "GenSigSendType" SG_ 1775 DiagReqAllCANData2 7;
BA_ "InvalidValue" SG_ 1775 DiagReqAllCANData2 "";
BA_ "GenSigSendType" SG_ 1775 DiagReqAllCANData3 7;
BA_ "InvalidValue" SG_ 1775 DiagReqAllCANData3 "";
BA_ "GenSigSendType" SG_ 1775 DiagReqAllCANData4 7;
BA_ "InvalidValue" SG_ 1775 DiagReqAllCANData4 "";
BA_ "GenSigSendType" SG_ 1775 DiagReqAllCANData5 7;
BA_ "InvalidValue" SG_ 1775 DiagReqAllCANData5 "";
BA_ "GenSigSendType" SG_ 1775 DiagReqAllCANData6 7;
BA_ "InvalidValue" SG_ 1775 DiagReqAllCANData6 "";
BA_ "GenSigSendType" SG_ 1775 DiagReqAllCANData7 7;
BA_ "InvalidValue" SG_ 1775 DiagReqAllCANData7 "";
BA_ "GenSigSendType" SG_ 1791 DiagReqAllEcuData0 7;
BA_ "InvalidValue" SG_ 1791 DiagReqAllEcuData0 "";
BA_ "GenSigSendType" SG_ 1791 DiagReqAllEcuData1 7;
BA_ "InvalidValue" SG_ 1791 DiagReqAllEcuData1 "";
BA_ "GenSigSendType" SG_ 1791 DiagReqAllEcuData2 7;
BA_ "InvalidValue" SG_ 1791 DiagReqAllEcuData2 "";
BA_ "GenSigSendType" SG_ 1791 DiagReqAllEcuData3 7;
BA_ "InvalidValue" SG_ 1791 DiagReqAllEcuData3 "";
BA_ "GenSigSendType" SG_ 1791 DiagReqAllEcuData4 7;
BA_ "InvalidValue" SG_ 1791 DiagReqAllEcuData4 "";
BA_ "GenSigSendType" SG_ 1791 DiagReqAllEcuData5 7;
BA_ "InvalidValue" SG_ 1791 DiagReqAllEcuData5 "";
BA_ "GenSigSendType" SG_ 1791 DiagReqAllEcuData6 7;
BA_ "InvalidValue" SG_ 1791 DiagReqAllEcuData6 "";
BA_ "GenSigSendType" SG_ 1791 DiagReqAllEcuData7 7;
BA_ "InvalidValue" SG_ 1791 DiagReqAllEcuData7 "";
BA_ "GenSigSendType" SG_ 1793 SEED_CAN_Req1 7;
BA_ "InvalidValue" SG_ 1793 SEED_CAN_Req1 "";
BA_ "GenSigSendType" SG_ 1795 SEED_CAN_Req2 7;
BA_ "InvalidValue" SG_ 1795 SEED_CAN_Req2 "";
BA_ "GenSigSendType" SG_ 1801 SEED_CAN_Req5 7;
BA_ "InvalidValue" SG_ 1801 SEED_CAN_Req5 "";
BA_ "GenSigSendType" SG_ 1803 SEED_CAN_Req6 7;
BA_ "InvalidValue" SG_ 1803 SEED_CAN_Req6 "";
BA_ "GenSigSendType" SG_ 1805 SEED_CAN_Req7 7;
BA_ "InvalidValue" SG_ 1805 SEED_CAN_Req7 "";
BA_ "GenSigSendType" SG_ 1807 SEED_CAN_Req8 7;
BA_ "InvalidValue" SG_ 1807 SEED_CAN_Req8 "";
BA_ "GenSigTimeoutTime_ALL" SG_ 1808 POD_PDU_Major_App_Version 5000;
BA_ "InvalidValue" SG_ 1808 POD_PDU_Major_App_Version "";
BA_ "GenSigTimeoutTime_ALL" SG_ 1808 POD_PDU_Minor_App_Version 5000;
BA_ "InvalidValue" SG_ 1808 POD_PDU_Minor_App_Version "";
BA_ "GenSigTimeoutTime_ALL" SG_ 1808 POD_PDU_Subminor_App_Version 5000;
BA_ "InvalidValue" SG_ 1808 POD_PDU_Subminor_App_Version "";
BA_ "GenSigTimeoutTime_ALL" SG_ 1809 CRC_POD_Err_Lvl 5000;
BA_ "GenSigTimeoutTime_ALL" SG_ 1809 ALIVE_POD_Err_Lvl 5000;
BA_ "InvalidValue" SG_ 1809 ALIVE_POD_Err_Lvl "Fh";
BA_ "GenSigTimeoutTime_ALL" SG_ 1809 DCFC_Err_Lvl 5000;
BA_ "InvalidValue" SG_ 1809 DCFC_Err_Lvl "";
BA_ "GenSigTimeoutTime_ALL" SG_ 1809 DCDC_Err_Lvl 5000;
BA_ "InvalidValue" SG_ 1809 DCDC_Err_Lvl "";
BA_ "GenSigTimeoutTime_ALL" SG_ 1809 OBC_Err_Lvl 5000;
BA_ "InvalidValue" SG_ 1809 OBC_Err_Lvl "";
BA_ "GenSigSendType" SG_ 1815 SEED_CAN_Req10 7;
BA_ "InvalidValue" SG_ 1815 SEED_CAN_Req10 "";
BA_ "GenSigSendType" SG_ 1843 SEED_CAN_Req18 7;
BA_ "InvalidValue" SG_ 1843 SEED_CAN_Req18 "";
BA_ "GenSigSendType" SG_ 1857 SEED_CAN_Req23 7;
BA_ "InvalidValue" SG_ 1857 SEED_CAN_Req23 "";
BA_ "GenSigSendType" SG_ 1859 SEED_CAN_Req22 7;
BA_ "InvalidValue" SG_ 1859 SEED_CAN_Req22 "";
BA_ "GenSigSendType" SG_ 1862 POD_Boot_Major_Version 7;
BA_ "InvalidValue" SG_ 1862 POD_Boot_Major_Version "";
BA_ "GenSigSendType" SG_ 1862 POD_Boot_Minor_Version 7;
BA_ "InvalidValue" SG_ 1862 POD_Boot_Minor_Version "";
BA_ "GenSigSendType" SG_ 1862 POD_Boot_Subminor_Version 7;
BA_ "InvalidValue" SG_ 1862 POD_Boot_Subminor_Version "";
BA_ "GenSigSendType" SG_ 1862 POD_Boot_Reason 7;
BA_ "InvalidValue" SG_ 1862 POD_Boot_Reason "";
BA_ "GenSigSendType" SG_ 1862 POD_App_valid 7;
BA_ "InvalidValue" SG_ 1862 POD_App_valid "";
BA_ "GenSigSendType" SG_ 1862 POD_App_Compatibility 7;
BA_ "InvalidValue" SG_ 1862 POD_App_Compatibility "";
BA_ "GenSigSendType" SG_ 1862 POD_Cal_Valid 7;
BA_ "InvalidValue" SG_ 1862 POD_Cal_Valid "";
BA_ "GenSigSendType" SG_ 1862 POD_Cal_Compatibility 7;
BA_ "InvalidValue" SG_ 1862 POD_Cal_Compatibility "";
BA_ "GenSigTimeoutTime_ALL" SG_ 1863 POD_DCDC_Major_App_Version 5000;
BA_ "InvalidValue" SG_ 1863 POD_DCDC_Major_App_Version "";
BA_ "GenSigTimeoutTime_ALL" SG_ 1863 POD_DCDC_Minor_App_Version 5000;
BA_ "InvalidValue" SG_ 1863 POD_DCDC_Minor_App_Version "";
BA_ "GenSigTimeoutTime_ALL" SG_ 1863 POD_DCDC_Subminor_App_Version 5000;
BA_ "InvalidValue" SG_ 1863 POD_DCDC_Subminor_App_Version "";
BA_ "GenSigTimeoutTime_ALL" SG_ 1864 POD_OBC_C1_Major_App_Version 5000;
BA_ "InvalidValue" SG_ 1864 POD_OBC_C1_Major_App_Version "";
BA_ "GenSigTimeoutTime_ALL" SG_ 1864 POD_OBC_C1_Minor_App_Version 5000;
BA_ "InvalidValue" SG_ 1864 POD_OBC_C1_Minor_App_Version "";
BA_ "GenSigTimeoutTime_ALL" SG_ 1864 POD_OBC_C1_Subminor_App_Version 5000;
BA_ "InvalidValue" SG_ 1864 POD_OBC_C1_Subminor_App_Version "";
BA_ "GenSigTimeoutTime_ALL" SG_ 1864 POD_OBC_C2_Major_App_Version 5000;
BA_ "InvalidValue" SG_ 1864 POD_OBC_C2_Major_App_Version "";
BA_ "GenSigTimeoutTime_ALL" SG_ 1864 POD_OBC_C2_Minor_App_Version 5000;
BA_ "InvalidValue" SG_ 1864 POD_OBC_C2_Minor_App_Version "";
BA_ "GenSigTimeoutTime_ALL" SG_ 1864 POD_OBC_C2_Subminor_App_Version 5000;
BA_ "InvalidValue" SG_ 1864 POD_OBC_C2_Subminor_App_Version "";
BA_ "GenSigTimeoutTime_ALL" SG_ 1864 POD_OBC_Build_Version 5000;
BA_ "InvalidValue" SG_ 1864 POD_OBC_Build_Version "";
BA_ "GenSigTimeoutTime_ALL" SG_ 1873 VCU_DebugDiag2 500;
BA_ "InvalidValue" SG_ 1873 VCU_DebugDiag2 "";
BA_ "GenSigTimeoutTime_ALL" SG_ 1873 VCU_DebugDiag1 500;
BA_ "InvalidValue" SG_ 1873 VCU_DebugDiag1 "";
BA_ "GenSigTimeoutTime_ALL" SG_ 1873 VCU_DebugDiag5 500;
BA_ "InvalidValue" SG_ 1873 VCU_DebugDiag5 "";
BA_ "GenSigTimeoutTime_ALL" SG_ 1873 VCU_DebugDiag4 500;
BA_ "InvalidValue" SG_ 1873 VCU_DebugDiag4 "";
BA_ "GenSigTimeoutTime_ALL" SG_ 1873 VCU_DebugDiag3 500;
BA_ "InvalidValue" SG_ 1873 VCU_DebugDiag3 "";
BA_ "GenSigTimeoutTime_ALL" SG_ 1873 VCU_DebugDiag8 500;
BA_ "InvalidValue" SG_ 1873 VCU_DebugDiag8 "";
BA_ "GenSigTimeoutTime_ALL" SG_ 1873 VCU_DebugDiag7 500;
BA_ "InvalidValue" SG_ 1873 VCU_DebugDiag7 "";
BA_ "GenSigTimeoutTime_ALL" SG_ 1873 VCU_DebugDiag6 500;
BA_ "InvalidValue" SG_ 1873 VCU_DebugDiag6 "";
BA_ "GenSigTimeoutTime_ALL" SG_ 1873 VCU_DebugDiag10 500;
BA_ "InvalidValue" SG_ 1873 VCU_DebugDiag10 "";
BA_ "GenSigTimeoutTime_ALL" SG_ 1873 VCU_DebugDiag9 500;
BA_ "InvalidValue" SG_ 1873 VCU_DebugDiag9 "";
BA_ "GenSigTimeoutTime_ALL" SG_ 1873 VCU_DebugDiag13 500;
BA_ "InvalidValue" SG_ 1873 VCU_DebugDiag13 "";
BA_ "GenSigTimeoutTime_ALL" SG_ 1873 VCU_DebugDiag12 500;
BA_ "InvalidValue" SG_ 1873 VCU_DebugDiag12 "";
BA_ "GenSigTimeoutTime_ALL" SG_ 1873 VCU_DebugDiag11 500;
BA_ "InvalidValue" SG_ 1873 VCU_DebugDiag11 "";
BA_ "GenSigTimeoutTime_ALL" SG_ 1873 VCU_DebugDiag16 500;
BA_ "InvalidValue" SG_ 1873 VCU_DebugDiag16 "";
BA_ "GenSigTimeoutTime_ALL" SG_ 1873 VCU_DebugDiag15 500;
BA_ "InvalidValue" SG_ 1873 VCU_DebugDiag15 "";
BA_ "GenSigTimeoutTime_ALL" SG_ 1873 VCU_DebugDiag14 500;
BA_ "InvalidValue" SG_ 1873 VCU_DebugDiag14 "";
BA_ "GenSigTimeoutTime_ALL" SG_ 1873 VCU_DebugDiag18 500;
BA_ "InvalidValue" SG_ 1873 VCU_DebugDiag18 "";
BA_ "GenSigTimeoutTime_ALL" SG_ 1873 VCU_DebugDiag17 500;
BA_ "InvalidValue" SG_ 1873 VCU_DebugDiag17 "";
BA_ "GenSigTimeoutTime_ALL" SG_ 1873 VCU_DebugDiag20 500;
BA_ "InvalidValue" SG_ 1873 VCU_DebugDiag20 "";
BA_ "GenSigTimeoutTime_ALL" SG_ 1873 VCU_DebugDiag19 500;
BA_ "InvalidValue" SG_ 1873 VCU_DebugDiag19 "";
BA_ "GenSigSendType" SG_ 1963 EPS2_XCP_CCPRespData0 7;
BA_ "InvalidValue" SG_ 1963 EPS2_XCP_CCPRespData0 "";
BA_ "GenSigSendType" SG_ 1963 EPS2_XCP_CCPRespData1 7;
BA_ "InvalidValue" SG_ 1963 EPS2_XCP_CCPRespData1 "";
BA_ "GenSigSendType" SG_ 1963 EPS2_XCP_CCPRespData2 7;
BA_ "InvalidValue" SG_ 1963 EPS2_XCP_CCPRespData2 "";
BA_ "GenSigSendType" SG_ 1963 EPS2_XCP_CCPRespData3 7;
BA_ "InvalidValue" SG_ 1963 EPS2_XCP_CCPRespData3 "";
BA_ "GenSigSendType" SG_ 1963 EPS2_XCP_CCPRespData4 7;
BA_ "InvalidValue" SG_ 1963 EPS2_XCP_CCPRespData4 "";
BA_ "GenSigSendType" SG_ 1963 EPS2_XCP_CCPRespData5 7;
BA_ "InvalidValue" SG_ 1963 EPS2_XCP_CCPRespData5 "";
BA_ "GenSigSendType" SG_ 1963 EPS2_XCP_CCPRespData6 7;
BA_ "InvalidValue" SG_ 1963 EPS2_XCP_CCPRespData6 "";
BA_ "GenSigSendType" SG_ 1963 EPS2_XCP_CCPRespData7 7;
BA_ "InvalidValue" SG_ 1963 EPS2_XCP_CCPRespData7 "";
BA_ "GenSigSendType" SG_ 2010 EPS2_XCP_CCPReqData0 7;
BA_ "InvalidValue" SG_ 2010 EPS2_XCP_CCPReqData0 "";
BA_ "GenSigSendType" SG_ 2010 EPS2_XCP_CCPReqData1 7;
BA_ "InvalidValue" SG_ 2010 EPS2_XCP_CCPReqData1 "";
BA_ "GenSigSendType" SG_ 2010 EPS2_XCP_CCPReqData2 7;
BA_ "InvalidValue" SG_ 2010 EPS2_XCP_CCPReqData2 "";
BA_ "GenSigSendType" SG_ 2010 EPS2_XCP_CCPReqData3 7;
BA_ "InvalidValue" SG_ 2010 EPS2_XCP_CCPReqData3 "";
BA_ "GenSigSendType" SG_ 2010 EPS2_XCP_CCPReqData4 7;
BA_ "InvalidValue" SG_ 2010 EPS2_XCP_CCPReqData4 "";
BA_ "GenSigSendType" SG_ 2010 EPS2_XCP_CCPReqData5 7;
BA_ "InvalidValue" SG_ 2010 EPS2_XCP_CCPReqData5 "";
BA_ "GenSigSendType" SG_ 2010 EPS2_XCP_CCPReqData6 7;
BA_ "InvalidValue" SG_ 2010 EPS2_XCP_CCPReqData6 "";
BA_ "GenSigSendType" SG_ 2010 EPS2_XCP_CCPReqData7 7;
BA_ "InvalidValue" SG_ 2010 EPS2_XCP_CCPReqData7 "";
BA_ "GenSigSendType" SG_ 2015 Diag_Request_ECU_Data0 7;
BA_ "InvalidValue" SG_ 2015 Diag_Request_ECU_Data0 "";
BA_ "GenSigSendType" SG_ 2015 Diag_Request_ECU_Data1 7;
BA_ "InvalidValue" SG_ 2015 Diag_Request_ECU_Data1 "";
BA_ "GenSigSendType" SG_ 2015 Diag_Request_ECU_Data2 7;
BA_ "InvalidValue" SG_ 2015 Diag_Request_ECU_Data2 "";
BA_ "GenSigSendType" SG_ 2015 Diag_Request_ECU_Data3 7;
BA_ "InvalidValue" SG_ 2015 Diag_Request_ECU_Data3 "";
BA_ "GenSigSendType" SG_ 2015 Diag_Request_ECU_Data4 7;
BA_ "InvalidValue" SG_ 2015 Diag_Request_ECU_Data4 "";
BA_ "GenSigSendType" SG_ 2015 Diag_Request_ECU_Data5 7;
BA_ "InvalidValue" SG_ 2015 Diag_Request_ECU_Data5 "";
BA_ "GenSigSendType" SG_ 2015 Diag_Request_ECU_Data6 7;
BA_ "InvalidValue" SG_ 2015 Diag_Request_ECU_Data6 "";
BA_ "GenSigSendType" SG_ 2015 Diag_Request_ECU_Data7 7;
BA_ "InvalidValue" SG_ 2015 Diag_Request_ECU_Data7 "";
VAL_ 1110 OP_WISW_SZL_LIN 0 "No action" 255 "Signal Invalid";
VAL_ 1110 COMM_ERR_SZL_LIN 0 "No error" 1 "Error active";
VAL_ 1110 BCM_Wiper_Front_Status 0 "OFF" 1 "Mist" 2 "IntermittentAuto" 3 "Low Speed" 4 "High Speed" 5 "Reserved" 6 "Reserved" 7 "Invalid";
VAL_ 1110 OP_WIPO_SZL_LIN 0 "Step 1" 1 "Step 2" 2 "Step 3" 4 "Step 4" 7 "Signal Invalid";
VAL_ 1110 OP_COLS_SZL_LIN 0 "No action" 255 "Signal Invalid";
VAL_ 1110 NOD_ERR_SZL_LIN 0 "NO error" 1 "error active" 2 "error Stat change" 3 "Signal invalid";
VAL_ 1110 BCM_Wiper_Rear_Status 0 "OFF" 1 "ON" 2 "Reserved" 3 "Signal Invalid";
VAL_ 1168 GS_Warning_Flag_1 0 "No Error" 1 "Error";
VAL_ 1168 GS_Warning_Flag_2 0 "No Error" 1 "Error";
VAL_ 1168 GS_Warning_Flag_3 0 "No Error" 1 "Error";
VAL_ 1168 GS_Warning_Flag_4 0 "No Error" 1 "Error";
VAL_ 1168 GS_Warning_Flag_5 0 "No Error" 1 "Error";
VAL_ 1168 GS_Warning_Flag_6 0 "No Error" 1 "Error";
VAL_ 1168 GS_Warning_Flag_7 0 "No Error" 1 "Error";
VAL_ 1168 GS_Warning_Flag_8 0 "No Error" 1 "Error";
VAL_ 1168 GS_Warning_Flag_9 0 "No Error" 1 "Error";
VAL_ 1168 GS_Warning_Flag_10 0 "No Error" 1 "Error";
VAL_ 1168 GS_Warning_Flag_11 0 "No Error" 1 "Error";
VAL_ 1168 GS_Warning_Flag_12 0 "No Error" 1 "Error";
VAL_ 1178 EDS_R_Warning_Flag_1 0 "No Error" 1 "Error";
VAL_ 1178 EDS_R_Warning_Flag_2 0 "No Error" 1 "Error";
VAL_ 1178 EDS_R_Warning_Flag_3 0 "No Error" 1 "Error";
VAL_ 1178 EDS_R_Warning_Flag_4 0 "No Error" 1 "Error";
VAL_ 1178 EDS_R_Warning_Flag_5 0 "No Error" 1 "Error";
VAL_ 1178 EDS_R_Warning_Flag_6 0 "No Error" 1 "Error";
VAL_ 1178 EDS_R_Warning_Flag_7 0 "No Error" 1 "Error";
VAL_ 1178 EDS_R_Warning_Flag_8 0 "No Error" 1 "Error";
VAL_ 1178 EDS_R_Warning_Flag_9 0 "No Error" 1 "Error";
VAL_ 1178 EDS_R_Warning_Flag_10 0 "No Error" 1 "Error";
VAL_ 1178 EDS_R_Warning_Flag_11 0 "No Error" 1 "Error";
VAL_ 1178 EDS_R_Warning_Flag_12 0 "No Error" 1 "Error";
VAL_ 1179 EDS_F_Warning_Flag_1 0 "No Error" 1 "Error";
VAL_ 1179 EDS_F_Warning_Flag_2 0 "No Error" 1 "Error";
VAL_ 1179 EDS_F_Warning_Flag_3 0 "No Error" 1 "Error";
VAL_ 1179 EDS_F_Warning_Flag_4 0 "No Error" 1 "Error";
VAL_ 1179 EDS_F_Warning_Flag_5 0 "No Error" 1 "Error";
VAL_ 1179 EDS_F_Warning_Flag_6 0 "No Error" 1 "Error";
VAL_ 1179 EDS_F_Warning_Flag_7 0 "No Error" 1 "Error";
VAL_ 1179 EDS_F_Warning_Flag_8 0 "No Error" 1 "Error";
VAL_ 1179 EDS_F_Warning_Flag_9 0 "No Error" 1 "Error";
VAL_ 1179 EDS_F_Warning_Flag_10 0 "No Error" 1 "Error";
VAL_ 1179 EDS_F_Warning_Flag_11 0 "No Error" 1 "Error";
VAL_ 1179 EDS_F_Warning_Flag_12 0 "No Error" 1 "Error";
VAL_ 1195 EPS2_Malfunction 0 "No Error" 1 "Error";
VAL_ 1195 EPS2_Reduced 0 "No Error" 1 "Error";
VAL_ 1195 EPS2_Overheat 0 "No Error" 1 "Error";
VAL_ 1195 EPS2_NotReady 0 "No Error" 1 "Error";
VAL_ 1195 EPS2_Warning_Flag_5 0 "No Error" 1 "Error";
VAL_ 1195 EPS2_Warning_Flag_6 0 "No Error" 1 "Error";
VAL_ 1195 EPS2_Warning_Flag_7 0 "No Error" 1 "Error";
VAL_ 1195 EPS2_Warning_Flag_8 0 "No Error" 1 "Error";
VAL_ 1195 EPS2_Warning_Flag_9 0 "No Error" 1 "Error";
VAL_ 1195 EPS2_Warning_Flag_10 0 "No Error" 1 "Error";
VAL_ 1195 EPS2_Warning_Flag_11 0 "No Error" 1 "Error";
VAL_ 1195 EPS2_Warning_Flag_12 0 "No Error" 1 "Error";
VAL_ 1196 VCU_GearPOnlyAtStationaryAlert 0 "None" 1 "Alert";
VAL_ 1196 VCU_GearP_NotPossibleAlert 0 "None" 1 "Alert";
VAL_ 1196 VCU_PressBrakeToEngageGear 0 "None" 1 "Alert";
VAL_ 1196 VCU_CantChangeGear 0 "None" 1 "Alert";
VAL_ 1196 VCU_GearMalfunction 0 "None" 1 "Alert";
VAL_ 1196 VCU_RangeAlert 0 "None" 1 "Alert";
VAL_ 1196 VCU_HVSystemReduced 0 "None" 1 "Alert";
VAL_ 1196 VCU_FrontEDSReduced 0 "None" 1 "Alert";
VAL_ 1196 VCU_FrontEDS_Malfunc 0 "None" 1 "Alert";
VAL_ 1196 VCU_RearEDSReduced 0 "None" 1 "Alert";
VAL_ 1196 VCU_RearEDS_Malfunc 0 "None" 1 "Alert";
VAL_ 1196 VCU_CoolingSystem_Malfunc 0 "None" 1 "Alert";
VAL_ 1196 VCU_NeutralRequest 0 "None" 1 "Alert";
VAL_ 1196 VCU_SoftShutdown 0 "None" 1 "Alert";
VAL_ 1196 VCU_EmergencyShutdown 0 "None" 1 "Alert";
VAL_ 1196 VCU_ChgPortDoorSys_Malfunc 0 "None" 1 "Alert";
VAL_ 1196 VCU_Gearchange_NotPossible 0 "None" 1 "Alert";
VAL_ 1196 VCU_12v_Warning 0 "None" 1 "Alert";
VAL_ 1196 VCU_WflagRes19 0 "None" 1 "Alert";
VAL_ 1196 VCU_WflagRes20 0 "None" 1 "Alert";
VAL_ 1196 VCU_WflagRes21 0 "None" 1 "Alert";
VAL_ 1196 VCU_WflagRes22 0 "None" 1 "Alert";
VAL_ 1196 VCU_WflagRes23 0 "None" 1 "Alert";
VAL_ 1196 VCU_WflagRes24 0 "None" 1 "Alert";
VAL_ 1196 VCU_WflagRes25 0 "None" 1 "Alert";
VAL_ 1196 VCU_WflagRes26 0 "None" 1 "Alert";
VAL_ 1196 VCU_WflagRes27 0 "None" 1 "Alert";
VAL_ 1196 VCU_SuperFastCharge_longer 0 "None" 1 "Alert";
VAL_ 1213 POD_Warning_Flag_1 0 "No Error" 1 "Error";
VAL_ 1213 POD_Warning_Flag_2 0 "No Error" 1 "Error";
VAL_ 1213 POD_Warning_Flag_3 0 "No Error" 1 "Error";
VAL_ 1213 POD_Warning_Flag_4 0 "No Error" 1 "Error";
VAL_ 1213 POD_Warning_Flag_5 0 "No Error" 1 "Error";
VAL_ 1213 POD_Warning_Flag_6 0 "No Error" 1 "Error";
VAL_ 1213 POD_Warning_Flag_7 0 "No Error" 1 "Error";
VAL_ 1213 POD_Warning_Flag_8 0 "No Error" 1 "Error";
VAL_ 1213 POD_Warning_Flag_9 0 "No Error" 1 "Error";
VAL_ 1213 POD_Warning_Flag_10 0 "No Error" 1 "Error";
VAL_ 1213 POD_Warning_Flag_11 0 "No Error" 1 "Error";
VAL_ 1213 POD_Warning_Flag_12 0 "No Error" 1 "Error";
VAL_ 1213 POD_Warning_Flag_13 0 "No Error" 1 "Error";
VAL_ 1213 POD_Warning_Flag_14 0 "No Error" 1 "Error";
VAL_ 1213 POD_Warning_Flag_15 0 "No Error" 1 "Error";
VAL_ 1213 POD_Warning_Flag_16 0 "No Error" 1 "Error";
VAL_ 1213 POD_Warning_Flag_17 0 "No Error" 1 "Error";
VAL_ 1213 POD_Warning_Flag_18 0 "No Error" 1 "Error";
VAL_ 1213 POD_Warning_Flag_19 0 "No Error" 1 "Error";
VAL_ 1213 POD_Warning_Flag_20 0 "No Error" 1 "Error";
VAL_ 1213 POD_Warning_Flag_21 0 "No Error" 1 "Error";
VAL_ 1213 POD_Warning_Flag_22 0 "No Error" 1 "Error";
VAL_ 1213 POD_Warning_Flag_23 0 "No Error" 1 "Error";
VAL_ 1213 POD_Warning_Flag_24 0 "No Error" 1 "Error";
VAL_ 1213 POD_Warning_Flag_25 0 "No Error" 1 "Error";
VAL_ 1213 POD_Warning_Flag_26 0 "No Error" 1 "Error";
VAL_ 1213 POD_Warning_Flag_27 0 "No Error" 1 "Error";
VAL_ 1213 POD_Warning_Flag_28 0 "No Error" 1 "Error";
VAL_ 1809 DCFC_Err_Lvl 0 "No fault" 1 "Level1-Minor fault" 2 "Level2-Serious fault" 3 "Level3-Fatal fault";
VAL_ 1809 DCDC_Err_Lvl 0 "No Fault" 1 "Level1-slight fault" 2 "Level2-Minor fault" 3 "Level3-General fault" 4 "Level4-Serious fault" 5 "Level5-Fatal fault";
VAL_ 1809 OBC_Err_Lvl 0 "No Fault" 1 "Level1-slight fault" 2 "Level2-Minor fault" 3 "Level3-General fault" 4 "Level4-Serious fault" 5 "Level5-Fatal fault";
VAL_ 1873 VCU_DebugDiag2 0 "No Error" 1 "Error Level 1" 2 "Error Level 2" 3 "Error Level 3" 4 "Error Level 4";
VAL_ 1873 VCU_DebugDiag1 0 "No Error" 1 "Error Level 1" 2 "Error Level 2" 3 "Error Level 3" 4 "Error Level 4";
VAL_ 1873 VCU_DebugDiag5 0 "No Error" 1 "Error Level 1" 2 "Error Level 2" 3 "Error Level 3" 4 "Error Level 4";
VAL_ 1873 VCU_DebugDiag4 0 "No Error" 1 "Error Level 1" 2 "Error Level 2" 3 "Error Level 3" 4 "Error Level 4";
VAL_ 1873 VCU_DebugDiag3 0 "No Error" 1 "Error Level 1" 2 "Error Level 2" 3 "Error Level 3" 4 "Error Level 4";
VAL_ 1873 VCU_DebugDiag8 0 "No Error" 1 "Error Level 1" 2 "Error Level 2" 3 "Error Level 3" 4 "Error Level 4";
VAL_ 1873 VCU_DebugDiag7 0 "No Error" 1 "Error Level 1" 2 "Error Level 2" 3 "Error Level 3" 4 "Error Level 4";
VAL_ 1873 VCU_DebugDiag6 0 "No Error" 1 "Error Level 1" 2 "Error Level 2" 3 "Error Level 3" 4 "Error Level 4";
VAL_ 1873 VCU_DebugDiag10 0 "No Error" 1 "Error Level 1" 2 "Error Level 2" 3 "Error Level 3" 4 "Error Level 4";
VAL_ 1873 VCU_DebugDiag9 0 "No Error" 1 "Error Level 1" 2 "Error Level 2" 3 "Error Level 3" 4 "Error Level 4";
VAL_ 1873 VCU_DebugDiag13 0 "No Error" 1 "Error Level 1" 2 "Error Level 2" 3 "Error Level 3" 4 "Error Level 4";
VAL_ 1873 VCU_DebugDiag12 0 "No Error" 1 "Error Level 1" 2 "Error Level 2" 3 "Error Level 3" 4 "Error Level 4";
VAL_ 1873 VCU_DebugDiag11 0 "No Error" 1 "Error Level 1" 2 "Error Level 2" 3 "Error Level 3" 4 "Error Level 4";
VAL_ 1873 VCU_DebugDiag16 0 "No Error" 1 "Error Level 1" 2 "Error Level 2" 3 "Error Level 3" 4 "Error Level 4";
VAL_ 1873 VCU_DebugDiag15 0 "No Error" 1 "Error Level 1" 2 "Error Level 2" 3 "Error Level 3" 4 "Error Level 4";
VAL_ 1873 VCU_DebugDiag14 0 "No Error" 1 "Error Level 1" 2 "Error Level 2" 3 "Error Level 3" 4 "Error Level 4";
VAL_ 1873 VCU_DebugDiag18 0 "No Error" 1 "Error Level 1" 2 "Error Level 2" 3 "Error Level 3" 4 "Error Level 4";
VAL_ 1873 VCU_DebugDiag17 0 "No Error" 1 "Error Level 1" 2 "Error Level 2" 3 "Error Level 3" 4 "Error Level 4";
VAL_ 1873 VCU_DebugDiag20 0 "No Error" 1 "Error Level 1" 2 "Error Level 2" 3 "Error Level 3" 4 "Error Level 4";
VAL_ 1873 VCU_DebugDiag19 0 "No Error" 1 "Error Level 1" 2 "Error Level 2" 3 "Error Level 3" 4 "Error Level 4";
